VERSION ""

NS_ :

BS_:

BU_: LECU25 LECU23 LECU22 LECU21 LECU19 LECU20 LECU18 LECU17 LECU16 LECU15 LECU14 LECU12 LECU11 LECU10 LECU9 LECU8 LECU7 LECU6 LECU5 LECU4 LECU2 LECU31 LECU30 LECU29 LECU28 LECU27 LECU26 LECU24 LECU13 LECU3 LECU1 BMU Tester LECU32 Host IVT_Mod

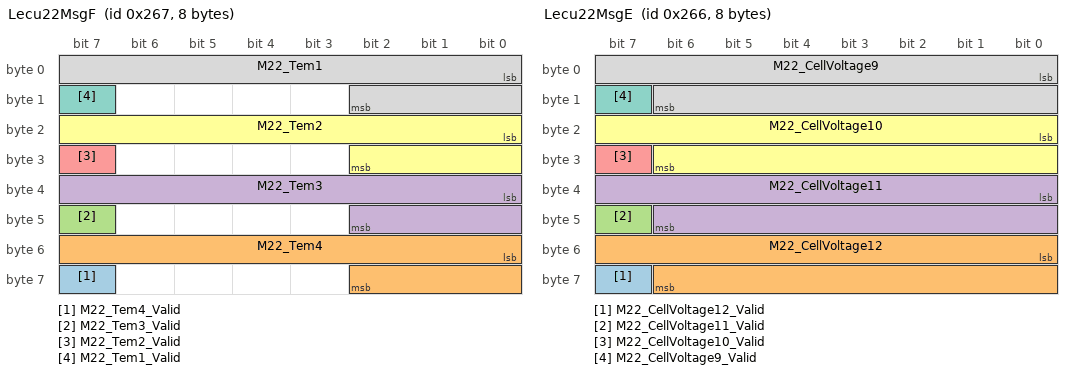
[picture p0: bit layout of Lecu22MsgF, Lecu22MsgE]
BO_ 615 Lecu22MsgF: 8 Vector__XXX
 SG_ M22_Tem4_Valid : 63|1@1+ (1,0) [0|0] "" Vector__XXX
 SG_ M22_Tem4 : 48|11@1+ (0.1,-40) [0|0] "" Vector__XXX
 SG_ M22_Tem3_Valid : 47|1@1+ (1,0) [0|0] "" Vector__XXX
 SG_ M22_Tem3 : 32|11@1+ (0.1,-40) [0|0] "" Vector__XXX
 SG_ M22_Tem2_Valid : 31|1@1+ (1,0) [0|0] "" Vector__XXX
 SG_ M22_Tem2 : 16|11@1+ (0.1,-40) [0|0] "" Vector__XXX
 SG_ M22_Tem1_Valid : 15|1@1+ (1,0) [0|0] "" Vector__XXX
 SG_ M22_Tem1 : 0|11@1+ (0.1,-40) [0|0] "" Vector__XXX

BO_ 614 Lecu22MsgE: 8 Vector__XXX
 SG_ M22_CellVoltage12_Valid : 63|1@1+ (1,0) [0|0] "" Vector__XXX
 SG_ M22_CellVoltage12 : 48|15@1- (0.001,0) [0|0] "" Vector__XXX
 SG_ M22_CellVoltage11_Valid : 47|1@1+ (1,0) [0|0] "" Vector__XXX
 SG_ M22_CellVoltage11 : 32|15@1- (0.001,0) [0|0] "" Vector__XXX
 SG_ M22_CellVoltage10_Valid : 31|1@1+ (1,0) [0|0] "" Vector__XXX
 SG_ M22_CellVoltage10 : 16|15@1- (0.001,0) [0|0] "" Vector__XXX
 SG_ M22_CellVoltage9_Valid : 15|1@1+ (1,0) [0|0] "" Vector__XXX
 SG_ M22_CellVoltage9 : 0|15@1- (0.001,0) [0|0] "" Vector__XXX

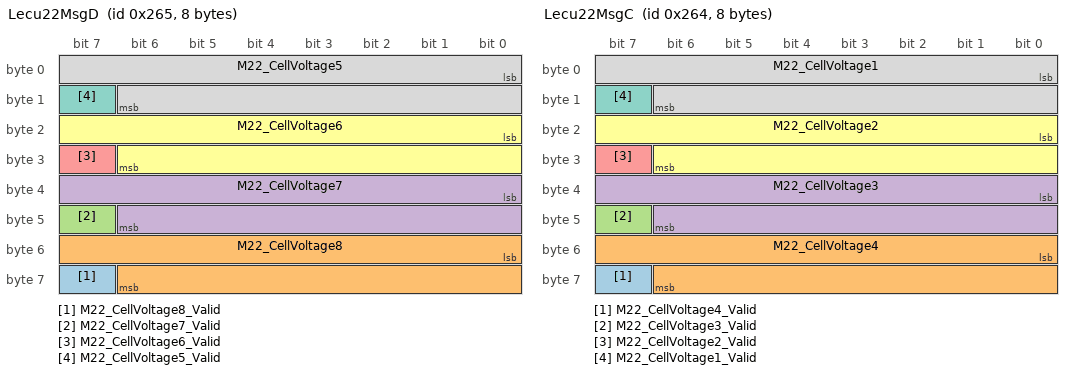
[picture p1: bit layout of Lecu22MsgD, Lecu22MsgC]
BO_ 613 Lecu22MsgD: 8 Vector__XXX
 SG_ M22_CellVoltage8_Valid : 63|1@1+ (1,0) [0|0] "" Vector__XXX
 SG_ M22_CellVoltage8 : 48|15@1- (0.001,0) [0|0] "" Vector__XXX
 SG_ M22_CellVoltage7_Valid : 47|1@1+ (1,0) [0|0] "" Vector__XXX
 SG_ M22_CellVoltage7 : 32|15@1- (0.001,0) [0|0] "" Vector__XXX
 SG_ M22_CellVoltage6_Valid : 31|1@1+ (1,0) [0|0] "" Vector__XXX
 SG_ M22_CellVoltage6 : 16|15@1- (0.001,0) [0|0] "" Vector__XXX
 SG_ M22_CellVoltage5_Valid : 15|1@1+ (1,0) [0|0] "" Vector__XXX
 SG_ M22_CellVoltage5 : 0|15@1- (0.001,0) [0|0] "" Vector__XXX

BO_ 612 Lecu22MsgC: 8 Vector__XXX
 SG_ M22_CellVoltage4_Valid : 63|1@1+ (1,0) [0|0] "" Vector__XXX
 SG_ M22_CellVoltage4 : 48|15@1- (0.001,0) [0|0] "" Vector__XXX
 SG_ M22_CellVoltage3_Valid : 47|1@1+ (1,0) [0|0] "" Vector__XXX
 SG_ M22_CellVoltage3 : 32|15@1- (0.001,0) [0|0] "" Vector__XXX
 SG_ M22_CellVoltage2_Valid : 31|1@1+ (1,0) [0|0] "" Vector__XXX
 SG_ M22_CellVoltage2 : 16|15@1- (0.001,0) [0|0] "" Vector__XXX
 SG_ M22_CellVoltage1_Valid : 15|1@1+ (1,0) [0|0] "" Vector__XXX
 SG_ M22_CellVoltage1 : 0|15@1- (0.001,0) [0|0] "" Vector__XXX

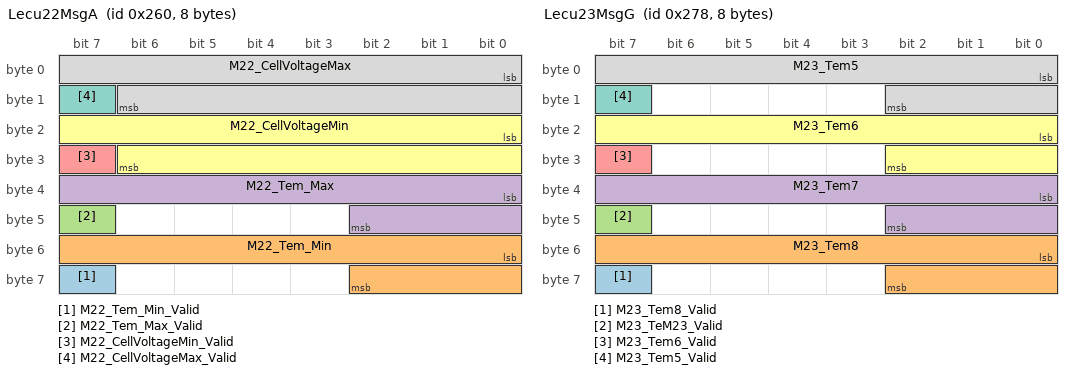
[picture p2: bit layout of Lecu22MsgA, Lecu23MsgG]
BO_ 608 Lecu22MsgA: 8 LECU22
 SG_ M22_Tem_Min_Valid : 63|1@1+ (1,0) [0|0] ""  BMU
 SG_ M22_Tem_Min : 48|11@1+ (0.1,-40) [0|0] "℃"  BMU
 SG_ M22_Tem_Max_Valid : 47|1@1+ (1,0) [0|0] ""  BMU
 SG_ M22_Tem_Max : 32|11@1+ (0.1,-40) [0|0] "℃"  BMU
 SG_ M22_CellVoltageMin_Valid : 31|1@1+ (1,0) [0|0] ""  BMU
 SG_ M22_CellVoltageMin : 16|15@1- (0.001,0) [0|0] "V"  BMU
 SG_ M22_CellVoltageMax_Valid : 15|1@1+ (1,0) [0|0] ""  BMU
 SG_ M22_CellVoltageMax : 0|15@1- (0.001,0) [0|0] "V"  BMU

BO_ 633 Lecu23MsgH: 8 Vector__XXX
 SG_ Lecu_Version3 : 63|8@0+ (1,0) [0|0] "" Vector__XXX
 SG_ Lecu_Version2 : 55|8@0+ (1,0) [0|0] "" Vector__XXX
 SG_ Lecu_Version1 : 47|8@0+ (1,0) [0|0] "" Vector__XXX
 SG_ Lecu_Version0 : 39|8@0+ (1,0) [0|0] "" Vector__XXX
 SG_ M23_CellBalance24 : 23|1@1+ (1,0) [0|0] "" Vector__XXX
 SG_ M23_CellBalance23 : 22|1@1+ (1,0) [0|0] "" Vector__XXX
 SG_ M23_CellBalance22 : 21|1@1+ (1,0) [0|0] "" Vector__XXX
 SG_ M23_CellBalance21 : 20|1@1+ (1,0) [0|0] "" Vector__XXX
 SG_ M23_CellBalance20 : 19|1@1+ (1,0) [0|0] "" Vector__XXX
 SG_ M23_CellBalance19 : 18|1@1+ (1,0) [0|0] "" Vector__XXX
 SG_ M23_CellBalance18 : 17|1@1+ (1,0) [0|0] "" Vector__XXX
 SG_ M23_CellBalance17 : 16|1@1+ (1,0) [0|0] "" Vector__XXX
 SG_ M23_CellBalance16 : 15|1@1+ (1,0) [0|0] "" Vector__XXX
 SG_ M23_CellBalance15 : 14|1@1+ (1,0) [0|0] "" Vector__XXX
 SG_ M23_CellBalance14 : 13|1@1+ (1,0) [0|0] "" Vector__XXX
 SG_ M23_CellBalance13 : 12|1@1+ (1,0) [0|0] "" Vector__XXX
 SG_ M23_CellBalance9 : 8|1@1+ (1,0) [0|0] "" Vector__XXX
 SG_ M23_CellBalance8 : 7|1@1+ (1,0) [0|0] "" Vector__XXX
 SG_ M23_CellBalance7 : 6|1@1+ (1,0) [0|0] "" Vector__XXX
 SG_ M23_CellBalance6 : 5|1@1+ (1,0) [0|0] "" Vector__XXX
 SG_ M23_CellBalance5 : 4|1@1+ (1,0) [0|0] "" Vector__XXX
 SG_ M23_CellBalance4 : 3|1@1+ (1,0) [0|0] "" Vector__XXX
 SG_ M23_CellBalance3 : 2|1@1+ (1,0) [0|0] "" Vector__XXX
 SG_ M23_CellBalance2 : 1|1@1+ (1,0) [0|0] "" Vector__XXX
 SG_ M23_CellBalance12 : 11|1@1+ (1,0) [0|0] "" Vector__XXX
 SG_ M23_CellBalance11 : 10|1@1+ (1,0) [0|0] "" Vector__XXX
 SG_ M23_CellBalance10 : 9|1@1+ (1,0) [0|0] "" Vector__XXX
 SG_ M23_CellBalance1 : 0|1@1+ (1,0) [0|0] "" Vector__XXX

BO_ 632 Lecu23MsgG: 8 Vector__XXX
 SG_ M23_Tem8_Valid : 63|1@1+ (1,0) [0|0] "" Vector__XXX
 SG_ M23_Tem8 : 48|11@1+ (0.1,-40) [0|0] "" Vector__XXX
 SG_ M23_TeM23_Valid : 47|1@1+ (1,0) [0|0] "" Vector__XXX
 SG_ M23_Tem7 : 32|11@1+ (0.1,-40) [0|0] "" Vector__XXX
 SG_ M23_Tem6_Valid : 31|1@1+ (1,0) [0|0] "" Vector__XXX
 SG_ M23_Tem6 : 16|11@1+ (0.1,-40) [0|0] "" Vector__XXX
 SG_ M23_Tem5_Valid : 15|1@1+ (1,0) [0|0] "" Vector__XXX
 SG_ M23_Tem5 : 0|11@1+ (0.1,-40) [0|0] "" Vector__XXX

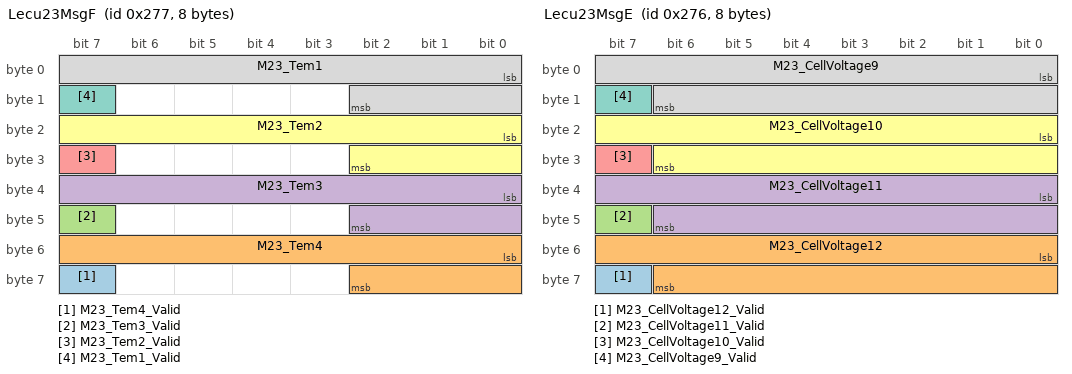
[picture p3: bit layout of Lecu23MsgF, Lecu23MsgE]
BO_ 631 Lecu23MsgF: 8 Vector__XXX
 SG_ M23_Tem4_Valid : 63|1@1+ (1,0) [0|0] "" Vector__XXX
 SG_ M23_Tem4 : 48|11@1+ (0.1,-40) [0|0] "" Vector__XXX
 SG_ M23_Tem3_Valid : 47|1@1+ (1,0) [0|0] "" Vector__XXX
 SG_ M23_Tem3 : 32|11@1+ (0.1,-40) [0|0] "" Vector__XXX
 SG_ M23_Tem2_Valid : 31|1@1+ (1,0) [0|0] "" Vector__XXX
 SG_ M23_Tem2 : 16|11@1+ (0.1,-40) [0|0] "" Vector__XXX
 SG_ M23_Tem1_Valid : 15|1@1+ (1,0) [0|0] "" Vector__XXX
 SG_ M23_Tem1 : 0|11@1+ (0.1,-40) [0|0] "" Vector__XXX

BO_ 630 Lecu23MsgE: 8 Vector__XXX
 SG_ M23_CellVoltage12_Valid : 63|1@1+ (1,0) [0|0] "" Vector__XXX
 SG_ M23_CellVoltage12 : 48|15@1- (0.001,0) [0|0] "" Vector__XXX
 SG_ M23_CellVoltage11_Valid : 47|1@1+ (1,0) [0|0] "" Vector__XXX
 SG_ M23_CellVoltage11 : 32|15@1- (0.001,0) [0|0] "" Vector__XXX
 SG_ M23_CellVoltage10_Valid : 31|1@1+ (1,0) [0|0] "" Vector__XXX
 SG_ M23_CellVoltage10 : 16|15@1- (0.001,0) [0|0] "" Vector__XXX
 SG_ M23_CellVoltage9_Valid : 15|1@1+ (1,0) [0|0] "" Vector__XXX
 SG_ M23_CellVoltage9 : 0|15@1- (0.001,0) [0|0] "" Vector__XXX

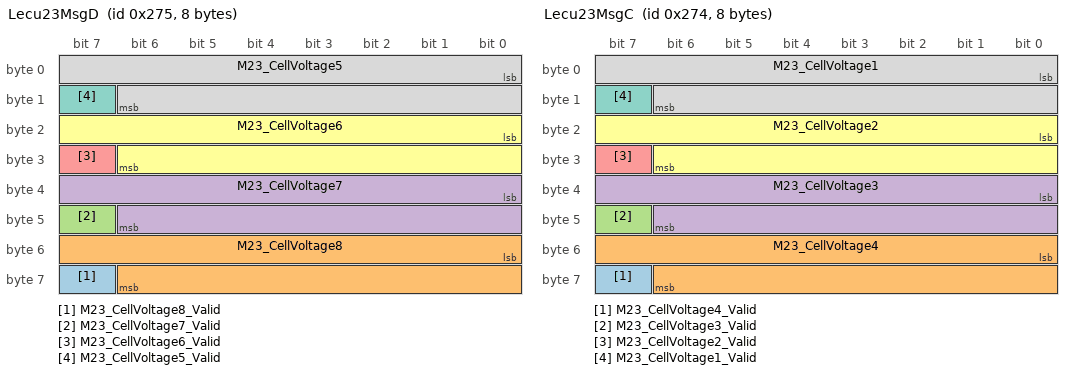
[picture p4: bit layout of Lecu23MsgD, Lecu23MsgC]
BO_ 629 Lecu23MsgD: 8 Vector__XXX
 SG_ M23_CellVoltage8_Valid : 63|1@1+ (1,0) [0|0] "" Vector__XXX
 SG_ M23_CellVoltage8 : 48|15@1- (0.001,0) [0|0] "" Vector__XXX
 SG_ M23_CellVoltage7_Valid : 47|1@1+ (1,0) [0|0] "" Vector__XXX
 SG_ M23_CellVoltage7 : 32|15@1- (0.001,0) [0|0] "" Vector__XXX
 SG_ M23_CellVoltage6_Valid : 31|1@1+ (1,0) [0|0] "" Vector__XXX
 SG_ M23_CellVoltage6 : 16|15@1- (0.001,0) [0|0] "" Vector__XXX
 SG_ M23_CellVoltage5_Valid : 15|1@1+ (1,0) [0|0] "" Vector__XXX
 SG_ M23_CellVoltage5 : 0|15@1- (0.001,0) [0|0] "" Vector__XXX

BO_ 628 Lecu23MsgC: 8 Vector__XXX
 SG_ M23_CellVoltage4_Valid : 63|1@1+ (1,0) [0|0] "" Vector__XXX
 SG_ M23_CellVoltage4 : 48|15@1- (0.001,0) [0|0] "" Vector__XXX
 SG_ M23_CellVoltage3_Valid : 47|1@1+ (1,0) [0|0] "" Vector__XXX
 SG_ M23_CellVoltage3 : 32|15@1- (0.001,0) [0|0] "" Vector__XXX
 SG_ M23_CellVoltage2_Valid : 31|1@1+ (1,0) [0|0] "" Vector__XXX
 SG_ M23_CellVoltage2 : 16|15@1- (0.001,0) [0|0] "" Vector__XXX
 SG_ M23_CellVoltage1_Valid : 15|1@1+ (1,0) [0|0] "" Vector__XXX
 SG_ M23_CellVoltage1 : 0|15@1- (0.001,0) [0|0] "" Vector__XXX

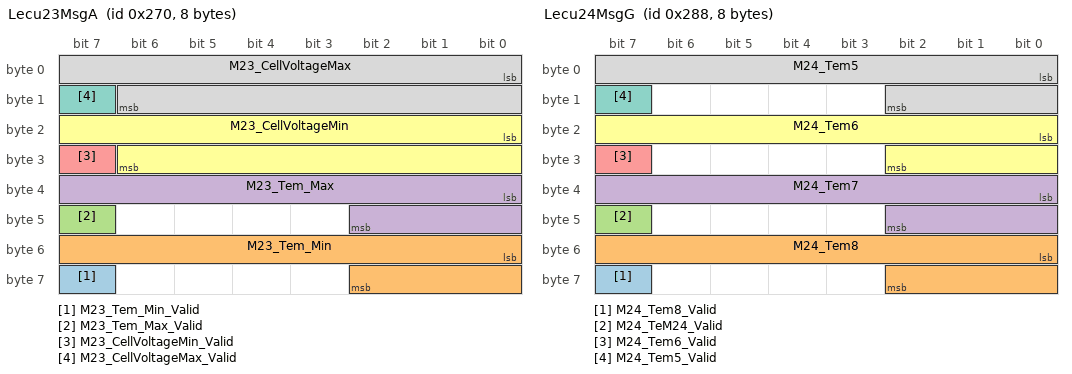
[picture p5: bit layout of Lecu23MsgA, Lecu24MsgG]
BO_ 624 Lecu23MsgA: 8 LECU23
 SG_ M23_Tem_Min_Valid : 63|1@1+ (1,0) [0|0] ""  BMU
 SG_ M23_Tem_Min : 48|11@1+ (0.1,-40) [0|0] "℃"  BMU
 SG_ M23_Tem_Max_Valid : 47|1@1+ (1,0) [0|0] ""  BMU
 SG_ M23_Tem_Max : 32|11@1+ (0.1,-40) [0|0] "℃"  BMU
 SG_ M23_CellVoltageMin_Valid : 31|1@1+ (1,0) [0|0] ""  BMU
 SG_ M23_CellVoltageMin : 16|15@1- (0.001,0) [0|0] "V"  BMU
 SG_ M23_CellVoltageMax_Valid : 15|1@1+ (1,0) [0|0] ""  BMU
 SG_ M23_CellVoltageMax : 0|15@1- (0.001,0) [0|0] "V"  BMU

BO_ 649 Lecu24MsgH: 8 Vector__XXX
 SG_ Lecu_Version3 : 63|8@0+ (1,0) [0|0] "" Vector__XXX
 SG_ Lecu_Version2 : 55|8@0+ (1,0) [0|0] "" Vector__XXX
 SG_ Lecu_Version1 : 47|8@0+ (1,0) [0|0] "" Vector__XXX
 SG_ Lecu_Version0 : 39|8@0+ (1,0) [0|0] "" Vector__XXX
 SG_ M24_CellBalance24 : 23|1@1+ (1,0) [0|0] "" Vector__XXX
 SG_ M24_CellBalance23 : 22|1@1+ (1,0) [0|0] "" Vector__XXX
 SG_ M24_CellBalance22 : 21|1@1+ (1,0) [0|0] "" Vector__XXX
 SG_ M24_CellBalance21 : 20|1@1+ (1,0) [0|0] "" Vector__XXX
 SG_ M24_CellBalance20 : 19|1@1+ (1,0) [0|0] "" Vector__XXX
 SG_ M24_CellBalance19 : 18|1@1+ (1,0) [0|0] "" Vector__XXX
 SG_ M24_CellBalance18 : 17|1@1+ (1,0) [0|0] "" Vector__XXX
 SG_ M24_CellBalance17 : 16|1@1+ (1,0) [0|0] "" Vector__XXX
 SG_ M24_CellBalance16 : 15|1@1+ (1,0) [0|0] "" Vector__XXX
 SG_ M24_CellBalance15 : 14|1@1+ (1,0) [0|0] "" Vector__XXX
 SG_ M24_CellBalance14 : 13|1@1+ (1,0) [0|0] "" Vector__XXX
 SG_ M24_CellBalance13 : 12|1@1+ (1,0) [0|0] "" Vector__XXX
 SG_ M24_CellBalance9 : 8|1@1+ (1,0) [0|0] "" Vector__XXX
 SG_ M24_CellBalance8 : 7|1@1+ (1,0) [0|0] "" Vector__XXX
 SG_ M24_CellBalance7 : 6|1@1+ (1,0) [0|0] "" Vector__XXX
 SG_ M24_CellBalance6 : 5|1@1+ (1,0) [0|0] "" Vector__XXX
 SG_ M24_CellBalance5 : 4|1@1+ (1,0) [0|0] "" Vector__XXX
 SG_ M24_CellBalance4 : 3|1@1+ (1,0) [0|0] "" Vector__XXX
 SG_ M24_CellBalance3 : 2|1@1+ (1,0) [0|0] "" Vector__XXX
 SG_ M24_CellBalance2 : 1|1@1+ (1,0) [0|0] "" Vector__XXX
 SG_ M24_CellBalance12 : 11|1@1+ (1,0) [0|0] "" Vector__XXX
 SG_ M24_CellBalance11 : 10|1@1+ (1,0) [0|0] "" Vector__XXX
 SG_ M24_CellBalance10 : 9|1@1+ (1,0) [0|0] "" Vector__XXX
 SG_ M24_CellBalance1 : 0|1@1+ (1,0) [0|0] "" Vector__XXX

BO_ 648 Lecu24MsgG: 8 Vector__XXX
 SG_ M24_Tem8_Valid : 63|1@1+ (1,0) [0|0] "" Vector__XXX
 SG_ M24_Tem8 : 48|11@1+ (0.1,-40) [0|0] "" Vector__XXX
 SG_ M24_TeM24_Valid : 47|1@1+ (1,0) [0|0] "" Vector__XXX
 SG_ M24_Tem7 : 32|11@1+ (0.1,-40) [0|0] "" Vector__XXX
 SG_ M24_Tem6_Valid : 31|1@1+ (1,0) [0|0] "" Vector__XXX
 SG_ M24_Tem6 : 16|11@1+ (0.1,-40) [0|0] "" Vector__XXX
 SG_ M24_Tem5_Valid : 15|1@1+ (1,0) [0|0] "" Vector__XXX
 SG_ M24_Tem5 : 0|11@1+ (0.1,-40) [0|0] "" Vector__XXX

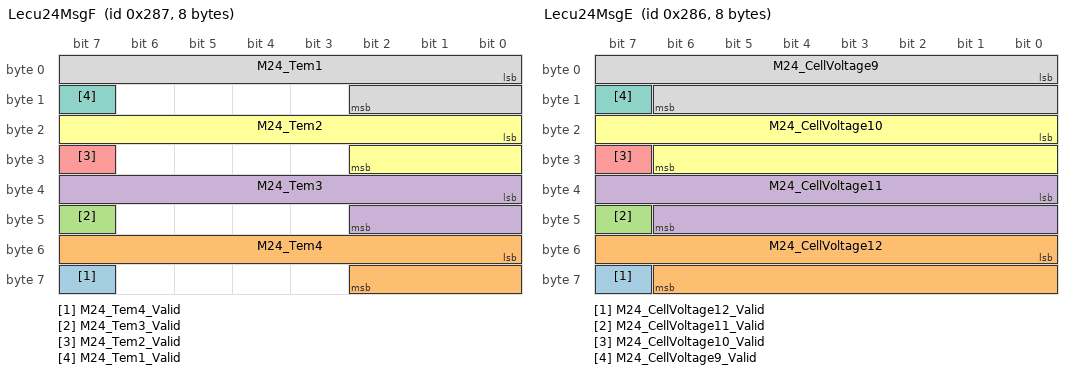
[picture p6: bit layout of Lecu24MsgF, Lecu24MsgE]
BO_ 647 Lecu24MsgF: 8 Vector__XXX
 SG_ M24_Tem4_Valid : 63|1@1+ (1,0) [0|0] "" Vector__XXX
 SG_ M24_Tem4 : 48|11@1+ (0.1,-40) [0|0] "" Vector__XXX
 SG_ M24_Tem3_Valid : 47|1@1+ (1,0) [0|0] "" Vector__XXX
 SG_ M24_Tem3 : 32|11@1+ (0.1,-40) [0|0] "" Vector__XXX
 SG_ M24_Tem2_Valid : 31|1@1+ (1,0) [0|0] "" Vector__XXX
 SG_ M24_Tem2 : 16|11@1+ (0.1,-40) [0|0] "" Vector__XXX
 SG_ M24_Tem1_Valid : 15|1@1+ (1,0) [0|0] "" Vector__XXX
 SG_ M24_Tem1 : 0|11@1+ (0.1,-40) [0|0] "" Vector__XXX

BO_ 646 Lecu24MsgE: 8 Vector__XXX
 SG_ M24_CellVoltage12_Valid : 63|1@1+ (1,0) [0|0] "" Vector__XXX
 SG_ M24_CellVoltage12 : 48|15@1- (0.001,0) [0|0] "" Vector__XXX
 SG_ M24_CellVoltage11_Valid : 47|1@1+ (1,0) [0|0] "" Vector__XXX
 SG_ M24_CellVoltage11 : 32|15@1- (0.001,0) [0|0] "" Vector__XXX
 SG_ M24_CellVoltage10_Valid : 31|1@1+ (1,0) [0|0] "" Vector__XXX
 SG_ M24_CellVoltage10 : 16|15@1- (0.001,0) [0|0] "" Vector__XXX
 SG_ M24_CellVoltage9_Valid : 15|1@1+ (1,0) [0|0] "" Vector__XXX
 SG_ M24_CellVoltage9 : 0|15@1- (0.001,0) [0|0] "" Vector__XXX

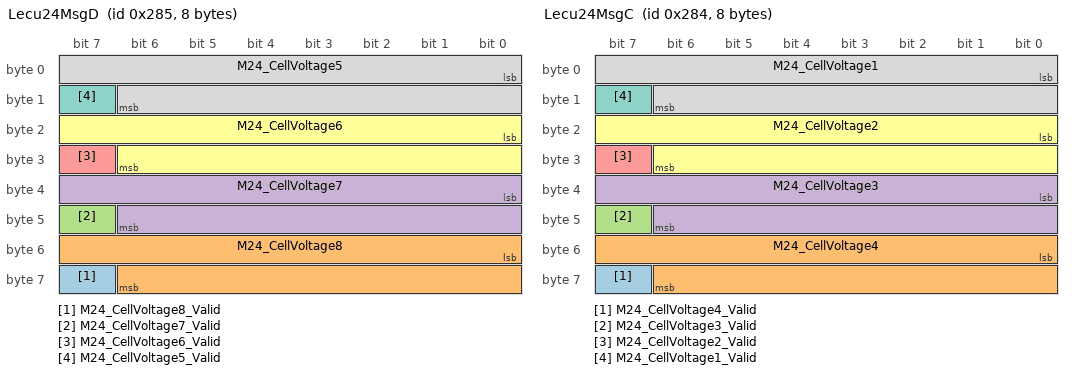
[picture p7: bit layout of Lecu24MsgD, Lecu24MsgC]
BO_ 645 Lecu24MsgD: 8 Vector__XXX
 SG_ M24_CellVoltage8_Valid : 63|1@1+ (1,0) [0|0] "" Vector__XXX
 SG_ M24_CellVoltage8 : 48|15@1- (0.001,0) [0|0] "" Vector__XXX
 SG_ M24_CellVoltage7_Valid : 47|1@1+ (1,0) [0|0] "" Vector__XXX
 SG_ M24_CellVoltage7 : 32|15@1- (0.001,0) [0|0] "" Vector__XXX
 SG_ M24_CellVoltage6_Valid : 31|1@1+ (1,0) [0|0] "" Vector__XXX
 SG_ M24_CellVoltage6 : 16|15@1- (0.001,0) [0|0] "" Vector__XXX
 SG_ M24_CellVoltage5_Valid : 15|1@1+ (1,0) [0|0] "" Vector__XXX
 SG_ M24_CellVoltage5 : 0|15@1- (0.001,0) [0|0] "" Vector__XXX

BO_ 644 Lecu24MsgC: 8 Vector__XXX
 SG_ M24_CellVoltage4_Valid : 63|1@1+ (1,0) [0|0] "" Vector__XXX
 SG_ M24_CellVoltage4 : 48|15@1- (0.001,0) [0|0] "" Vector__XXX
 SG_ M24_CellVoltage3_Valid : 47|1@1+ (1,0) [0|0] "" Vector__XXX
 SG_ M24_CellVoltage3 : 32|15@1- (0.001,0) [0|0] "" Vector__XXX
 SG_ M24_CellVoltage2_Valid : 31|1@1+ (1,0) [0|0] "" Vector__XXX
 SG_ M24_CellVoltage2 : 16|15@1- (0.001,0) [0|0] "" Vector__XXX
 SG_ M24_CellVoltage1_Valid : 15|1@1+ (1,0) [0|0] "" Vector__XXX
 SG_ M24_CellVoltage1 : 0|15@1- (0.001,0) [0|0] "" Vector__XXX

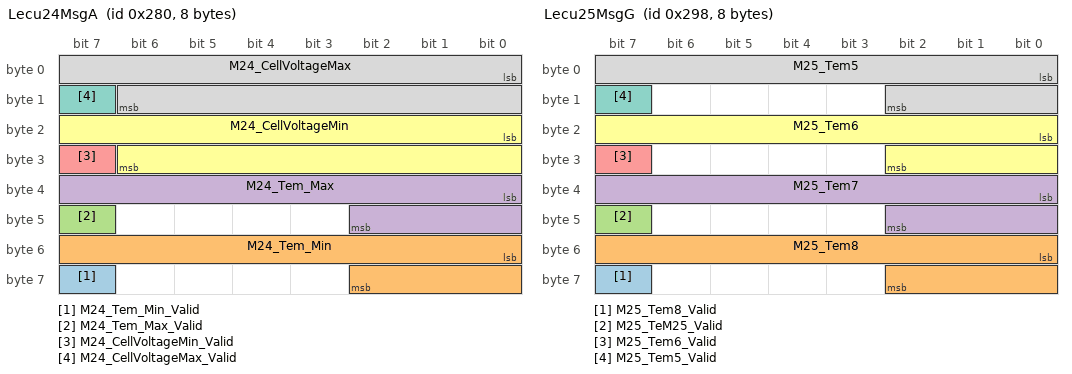
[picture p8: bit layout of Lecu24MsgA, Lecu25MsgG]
BO_ 640 Lecu24MsgA: 8 LECU24
 SG_ M24_Tem_Min_Valid : 63|1@1+ (1,0) [0|0] ""  BMU
 SG_ M24_Tem_Min : 48|11@1+ (0.1,-40) [0|0] "℃"  BMU
 SG_ M24_Tem_Max_Valid : 47|1@1+ (1,0) [0|0] ""  BMU
 SG_ M24_Tem_Max : 32|11@1+ (0.1,-40) [0|0] "℃"  BMU
 SG_ M24_CellVoltageMin_Valid : 31|1@1+ (1,0) [0|0] ""  BMU
 SG_ M24_CellVoltageMin : 16|15@1- (0.001,0) [0|0] "V"  BMU
 SG_ M24_CellVoltageMax_Valid : 15|1@1+ (1,0) [0|0] ""  BMU
 SG_ M24_CellVoltageMax : 0|15@1- (0.001,0) [0|0] "V"  BMU

BO_ 665 Lecu25MsgH: 8 Vector__XXX
 SG_ Lecu_Version3 : 63|8@0+ (1,0) [0|0] "" Vector__XXX
 SG_ Lecu_Version2 : 55|8@0+ (1,0) [0|0] "" Vector__XXX
 SG_ Lecu_Version1 : 47|8@0+ (1,0) [0|0] "" Vector__XXX
 SG_ Lecu_Version0 : 39|8@0+ (1,0) [0|0] "" Vector__XXX
 SG_ M25_CellBalance24 : 23|1@1+ (1,0) [0|0] "" Vector__XXX
 SG_ M25_CellBalance23 : 22|1@1+ (1,0) [0|0] "" Vector__XXX
 SG_ M25_CellBalance22 : 21|1@1+ (1,0) [0|0] "" Vector__XXX
 SG_ M25_CellBalance21 : 20|1@1+ (1,0) [0|0] "" Vector__XXX
 SG_ M25_CellBalance20 : 19|1@1+ (1,0) [0|0] "" Vector__XXX
 SG_ M25_CellBalance19 : 18|1@1+ (1,0) [0|0] "" Vector__XXX
 SG_ M25_CellBalance18 : 17|1@1+ (1,0) [0|0] "" Vector__XXX
 SG_ M25_CellBalance17 : 16|1@1+ (1,0) [0|0] "" Vector__XXX
 SG_ M25_CellBalance16 : 15|1@1+ (1,0) [0|0] "" Vector__XXX
 SG_ M25_CellBalance15 : 14|1@1+ (1,0) [0|0] "" Vector__XXX
 SG_ M25_CellBalance14 : 13|1@1+ (1,0) [0|0] "" Vector__XXX
 SG_ M25_CellBalance13 : 12|1@1+ (1,0) [0|0] "" Vector__XXX
 SG_ M25_CellBalance9 : 8|1@1+ (1,0) [0|0] "" Vector__XXX
 SG_ M25_CellBalance8 : 7|1@1+ (1,0) [0|0] "" Vector__XXX
 SG_ M25_CellBalance7 : 6|1@1+ (1,0) [0|0] "" Vector__XXX
 SG_ M25_CellBalance6 : 5|1@1+ (1,0) [0|0] "" Vector__XXX
 SG_ M25_CellBalance5 : 4|1@1+ (1,0) [0|0] "" Vector__XXX
 SG_ M25_CellBalance4 : 3|1@1+ (1,0) [0|0] "" Vector__XXX
 SG_ M25_CellBalance3 : 2|1@1+ (1,0) [0|0] "" Vector__XXX
 SG_ M25_CellBalance2 : 1|1@1+ (1,0) [0|0] "" Vector__XXX
 SG_ M25_CellBalance12 : 11|1@1+ (1,0) [0|0] "" Vector__XXX
 SG_ M25_CellBalance11 : 10|1@1+ (1,0) [0|0] "" Vector__XXX
 SG_ M25_CellBalance10 : 9|1@1+ (1,0) [0|0] "" Vector__XXX
 SG_ M25_CellBalance1 : 0|1@1+ (1,0) [0|0] "" Vector__XXX

BO_ 664 Lecu25MsgG: 8 Vector__XXX
 SG_ M25_Tem8_Valid : 63|1@1+ (1,0) [0|0] "" Vector__XXX
 SG_ M25_Tem8 : 48|11@1+ (0.1,-40) [0|0] "" Vector__XXX
 SG_ M25_TeM25_Valid : 47|1@1+ (1,0) [0|0] "" Vector__XXX
 SG_ M25_Tem7 : 32|11@1+ (0.1,-40) [0|0] "" Vector__XXX
 SG_ M25_Tem6_Valid : 31|1@1+ (1,0) [0|0] "" Vector__XXX
 SG_ M25_Tem6 : 16|11@1+ (0.1,-40) [0|0] "" Vector__XXX
 SG_ M25_Tem5_Valid : 15|1@1+ (1,0) [0|0] "" Vector__XXX
 SG_ M25_Tem5 : 0|11@1+ (0.1,-40) [0|0] "" Vector__XXX

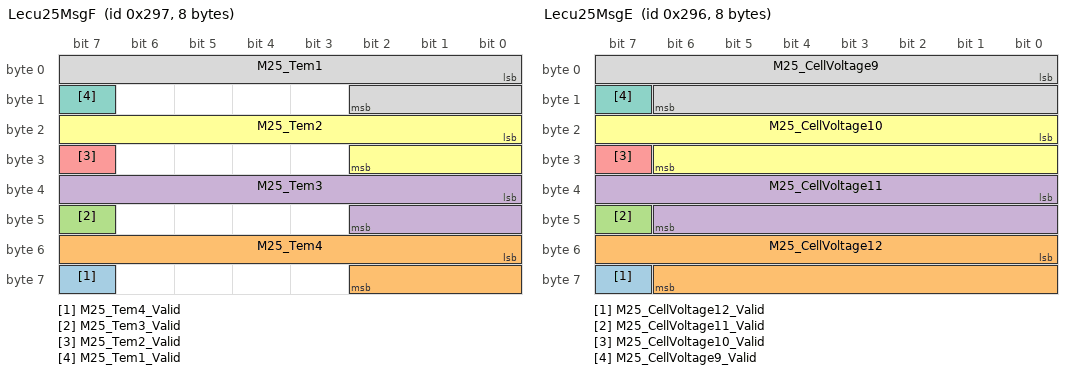
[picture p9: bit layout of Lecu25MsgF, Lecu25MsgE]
BO_ 663 Lecu25MsgF: 8 Vector__XXX
 SG_ M25_Tem4_Valid : 63|1@1+ (1,0) [0|0] "" Vector__XXX
 SG_ M25_Tem4 : 48|11@1+ (0.1,-40) [0|0] "" Vector__XXX
 SG_ M25_Tem3_Valid : 47|1@1+ (1,0) [0|0] "" Vector__XXX
 SG_ M25_Tem3 : 32|11@1+ (0.1,-40) [0|0] "" Vector__XXX
 SG_ M25_Tem2_Valid : 31|1@1+ (1,0) [0|0] "" Vector__XXX
 SG_ M25_Tem2 : 16|11@1+ (0.1,-40) [0|0] "" Vector__XXX
 SG_ M25_Tem1_Valid : 15|1@1+ (1,0) [0|0] "" Vector__XXX
 SG_ M25_Tem1 : 0|11@1+ (0.1,-40) [0|0] "" Vector__XXX

BO_ 662 Lecu25MsgE: 8 Vector__XXX
 SG_ M25_CellVoltage12_Valid : 63|1@1+ (1,0) [0|0] "" Vector__XXX
 SG_ M25_CellVoltage12 : 48|15@1- (0.001,0) [0|0] "" Vector__XXX
 SG_ M25_CellVoltage11_Valid : 47|1@1+ (1,0) [0|0] "" Vector__XXX
 SG_ M25_CellVoltage11 : 32|15@1- (0.001,0) [0|0] "" Vector__XXX
 SG_ M25_CellVoltage10_Valid : 31|1@1+ (1,0) [0|0] "" Vector__XXX
 SG_ M25_CellVoltage10 : 16|15@1- (0.001,0) [0|0] "" Vector__XXX
 SG_ M25_CellVoltage9_Valid : 15|1@1+ (1,0) [0|0] "" Vector__XXX
 SG_ M25_CellVoltage9 : 0|15@1- (0.001,0) [0|0] "" Vector__XXX

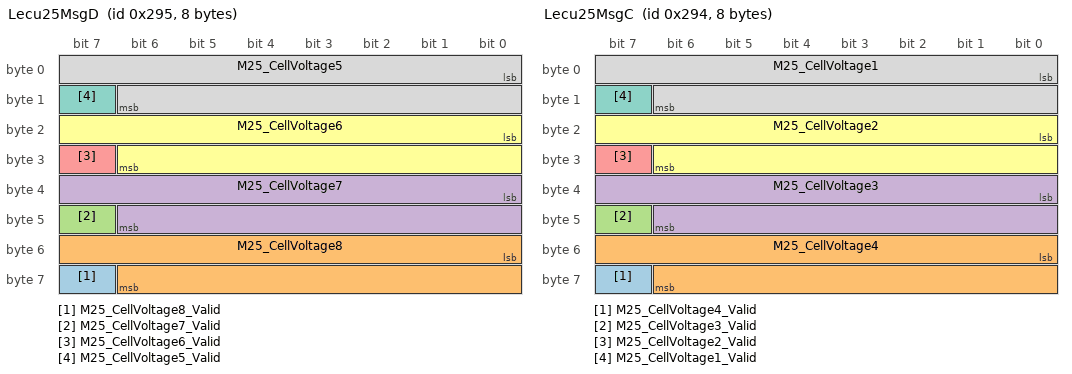
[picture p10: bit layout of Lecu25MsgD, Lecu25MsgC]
BO_ 661 Lecu25MsgD: 8 Vector__XXX
 SG_ M25_CellVoltage8_Valid : 63|1@1+ (1,0) [0|0] "" Vector__XXX
 SG_ M25_CellVoltage8 : 48|15@1- (0.001,0) [0|0] "" Vector__XXX
 SG_ M25_CellVoltage7_Valid : 47|1@1+ (1,0) [0|0] "" Vector__XXX
 SG_ M25_CellVoltage7 : 32|15@1- (0.001,0) [0|0] "" Vector__XXX
 SG_ M25_CellVoltage6_Valid : 31|1@1+ (1,0) [0|0] "" Vector__XXX
 SG_ M25_CellVoltage6 : 16|15@1- (0.001,0) [0|0] "" Vector__XXX
 SG_ M25_CellVoltage5_Valid : 15|1@1+ (1,0) [0|0] "" Vector__XXX
 SG_ M25_CellVoltage5 : 0|15@1- (0.001,0) [0|0] "" Vector__XXX

BO_ 660 Lecu25MsgC: 8 Vector__XXX
 SG_ M25_CellVoltage4_Valid : 63|1@1+ (1,0) [0|0] "" Vector__XXX
 SG_ M25_CellVoltage4 : 48|15@1- (0.001,0) [0|0] "" Vector__XXX
 SG_ M25_CellVoltage3_Valid : 47|1@1+ (1,0) [0|0] "" Vector__XXX
 SG_ M25_CellVoltage3 : 32|15@1- (0.001,0) [0|0] "" Vector__XXX
 SG_ M25_CellVoltage2_Valid : 31|1@1+ (1,0) [0|0] "" Vector__XXX
 SG_ M25_CellVoltage2 : 16|15@1- (0.001,0) [0|0] "" Vector__XXX
 SG_ M25_CellVoltage1_Valid : 15|1@1+ (1,0) [0|0] "" Vector__XXX
 SG_ M25_CellVoltage1 : 0|15@1- (0.001,0) [0|0] "" Vector__XXX

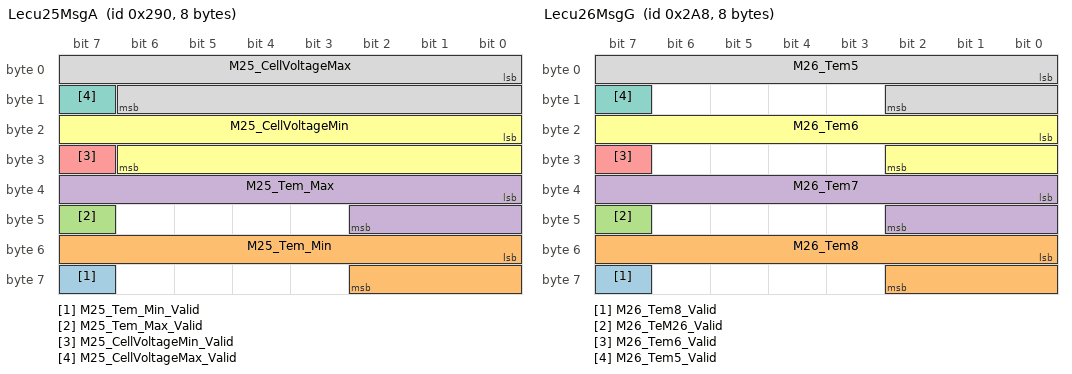
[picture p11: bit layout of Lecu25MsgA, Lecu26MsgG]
BO_ 656 Lecu25MsgA: 8 LECU25
 SG_ M25_Tem_Min_Valid : 63|1@1+ (1,0) [0|0] ""  BMU
 SG_ M25_Tem_Min : 48|11@1+ (0.1,-40) [0|0] "℃"  BMU
 SG_ M25_Tem_Max_Valid : 47|1@1+ (1,0) [0|0] ""  BMU
 SG_ M25_Tem_Max : 32|11@1+ (0.1,-40) [0|0] "℃"  BMU
 SG_ M25_CellVoltageMin_Valid : 31|1@1+ (1,0) [0|0] ""  BMU
 SG_ M25_CellVoltageMin : 16|15@1- (0.001,0) [0|0] "V"  BMU
 SG_ M25_CellVoltageMax_Valid : 15|1@1+ (1,0) [0|0] ""  BMU
 SG_ M25_CellVoltageMax : 0|15@1- (0.001,0) [0|0] "V"  BMU

BO_ 681 Lecu26MsgH: 8 Vector__XXX
 SG_ Lecu_Version3 : 63|8@0+ (1,0) [0|0] "" Vector__XXX
 SG_ Lecu_Version2 : 55|8@0+ (1,0) [0|0] "" Vector__XXX
 SG_ Lecu_Version1 : 47|8@0+ (1,0) [0|0] "" Vector__XXX
 SG_ Lecu_Version0 : 39|8@0+ (1,0) [0|0] "" Vector__XXX
 SG_ M26_CellBalance24 : 23|1@1+ (1,0) [0|0] "" Vector__XXX
 SG_ M26_CellBalance23 : 22|1@1+ (1,0) [0|0] "" Vector__XXX
 SG_ M26_CellBalance22 : 21|1@1+ (1,0) [0|0] "" Vector__XXX
 SG_ M26_CellBalance21 : 20|1@1+ (1,0) [0|0] "" Vector__XXX
 SG_ M26_CellBalance20 : 19|1@1+ (1,0) [0|0] "" Vector__XXX
 SG_ M26_CellBalance19 : 18|1@1+ (1,0) [0|0] "" Vector__XXX
 SG_ M26_CellBalance18 : 17|1@1+ (1,0) [0|0] "" Vector__XXX
 SG_ M26_CellBalance17 : 16|1@1+ (1,0) [0|0] "" Vector__XXX
 SG_ M26_CellBalance16 : 15|1@1+ (1,0) [0|0] "" Vector__XXX
 SG_ M26_CellBalance15 : 14|1@1+ (1,0) [0|0] "" Vector__XXX
 SG_ M26_CellBalance14 : 13|1@1+ (1,0) [0|0] "" Vector__XXX
 SG_ M26_CellBalance13 : 12|1@1+ (1,0) [0|0] "" Vector__XXX
 SG_ M26_CellBalance9 : 8|1@1+ (1,0) [0|0] "" Vector__XXX
 SG_ M26_CellBalance8 : 7|1@1+ (1,0) [0|0] "" Vector__XXX
 SG_ M26_CellBalance7 : 6|1@1+ (1,0) [0|0] "" Vector__XXX
 SG_ M26_CellBalance6 : 5|1@1+ (1,0) [0|0] "" Vector__XXX
 SG_ M26_CellBalance5 : 4|1@1+ (1,0) [0|0] "" Vector__XXX
 SG_ M26_CellBalance4 : 3|1@1+ (1,0) [0|0] "" Vector__XXX
 SG_ M26_CellBalance3 : 2|1@1+ (1,0) [0|0] "" Vector__XXX
 SG_ M26_CellBalance2 : 1|1@1+ (1,0) [0|0] "" Vector__XXX
 SG_ M26_CellBalance12 : 11|1@1+ (1,0) [0|0] "" Vector__XXX
 SG_ M26_CellBalance11 : 10|1@1+ (1,0) [0|0] "" Vector__XXX
 SG_ M26_CellBalance10 : 9|1@1+ (1,0) [0|0] "" Vector__XXX
 SG_ M26_CellBalance1 : 0|1@1+ (1,0) [0|0] "" Vector__XXX

BO_ 680 Lecu26MsgG: 8 Vector__XXX
 SG_ M26_Tem8_Valid : 63|1@1+ (1,0) [0|0] "" Vector__XXX
 SG_ M26_Tem8 : 48|11@1+ (0.1,-40) [0|0] "" Vector__XXX
 SG_ M26_TeM26_Valid : 47|1@1+ (1,0) [0|0] "" Vector__XXX
 SG_ M26_Tem7 : 32|11@1+ (0.1,-40) [0|0] "" Vector__XXX
 SG_ M26_Tem6_Valid : 31|1@1+ (1,0) [0|0] "" Vector__XXX
 SG_ M26_Tem6 : 16|11@1+ (0.1,-40) [0|0] "" Vector__XXX
 SG_ M26_Tem5_Valid : 15|1@1+ (1,0) [0|0] "" Vector__XXX
 SG_ M26_Tem5 : 0|11@1+ (0.1,-40) [0|0] "" Vector__XXX

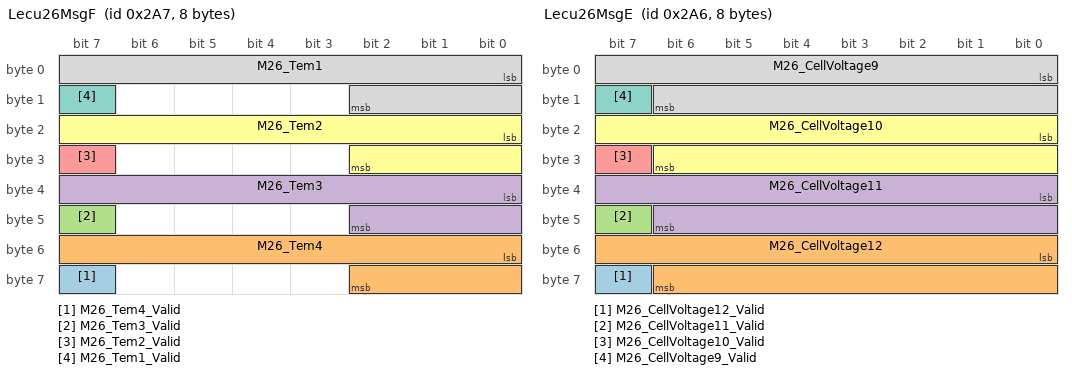
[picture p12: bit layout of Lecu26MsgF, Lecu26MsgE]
BO_ 679 Lecu26MsgF: 8 Vector__XXX
 SG_ M26_Tem4_Valid : 63|1@1+ (1,0) [0|0] "" Vector__XXX
 SG_ M26_Tem4 : 48|11@1+ (0.1,-40) [0|0] "" Vector__XXX
 SG_ M26_Tem3_Valid : 47|1@1+ (1,0) [0|0] "" Vector__XXX
 SG_ M26_Tem3 : 32|11@1+ (0.1,-40) [0|0] "" Vector__XXX
 SG_ M26_Tem2_Valid : 31|1@1+ (1,0) [0|0] "" Vector__XXX
 SG_ M26_Tem2 : 16|11@1+ (0.1,-40) [0|0] "" Vector__XXX
 SG_ M26_Tem1_Valid : 15|1@1+ (1,0) [0|0] "" Vector__XXX
 SG_ M26_Tem1 : 0|11@1+ (0.1,-40) [0|0] "" Vector__XXX

BO_ 678 Lecu26MsgE: 8 Vector__XXX
 SG_ M26_CellVoltage12_Valid : 63|1@1+ (1,0) [0|0] "" Vector__XXX
 SG_ M26_CellVoltage12 : 48|15@1- (0.001,0) [0|0] "" Vector__XXX
 SG_ M26_CellVoltage11_Valid : 47|1@1+ (1,0) [0|0] "" Vector__XXX
 SG_ M26_CellVoltage11 : 32|15@1- (0.001,0) [0|0] "" Vector__XXX
 SG_ M26_CellVoltage10_Valid : 31|1@1+ (1,0) [0|0] "" Vector__XXX
 SG_ M26_CellVoltage10 : 16|15@1- (0.001,0) [0|0] "" Vector__XXX
 SG_ M26_CellVoltage9_Valid : 15|1@1+ (1,0) [0|0] "" Vector__XXX
 SG_ M26_CellVoltage9 : 0|15@1- (0.001,0) [0|0] "" Vector__XXX

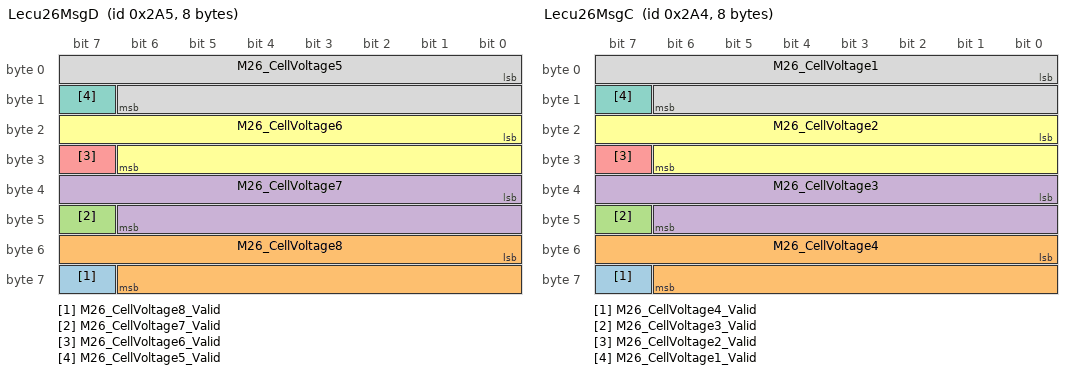
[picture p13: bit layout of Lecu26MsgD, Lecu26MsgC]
BO_ 677 Lecu26MsgD: 8 Vector__XXX
 SG_ M26_CellVoltage8_Valid : 63|1@1+ (1,0) [0|0] "" Vector__XXX
 SG_ M26_CellVoltage8 : 48|15@1- (0.001,0) [0|0] "" Vector__XXX
 SG_ M26_CellVoltage7_Valid : 47|1@1+ (1,0) [0|0] "" Vector__XXX
 SG_ M26_CellVoltage7 : 32|15@1- (0.001,0) [0|0] "" Vector__XXX
 SG_ M26_CellVoltage6_Valid : 31|1@1+ (1,0) [0|0] "" Vector__XXX
 SG_ M26_CellVoltage6 : 16|15@1- (0.001,0) [0|0] "" Vector__XXX
 SG_ M26_CellVoltage5_Valid : 15|1@1+ (1,0) [0|0] "" Vector__XXX
 SG_ M26_CellVoltage5 : 0|15@1- (0.001,0) [0|0] "" Vector__XXX

BO_ 676 Lecu26MsgC: 8 Vector__XXX
 SG_ M26_CellVoltage4_Valid : 63|1@1+ (1,0) [0|0] "" Vector__XXX
 SG_ M26_CellVoltage4 : 48|15@1- (0.001,0) [0|0] "" Vector__XXX
 SG_ M26_CellVoltage3_Valid : 47|1@1+ (1,0) [0|0] "" Vector__XXX
 SG_ M26_CellVoltage3 : 32|15@1- (0.001,0) [0|0] "" Vector__XXX
 SG_ M26_CellVoltage2_Valid : 31|1@1+ (1,0) [0|0] "" Vector__XXX
 SG_ M26_CellVoltage2 : 16|15@1- (0.001,0) [0|0] "" Vector__XXX
 SG_ M26_CellVoltage1_Valid : 15|1@1+ (1,0) [0|0] "" Vector__XXX
 SG_ M26_CellVoltage1 : 0|15@1- (0.001,0) [0|0] "" Vector__XXX

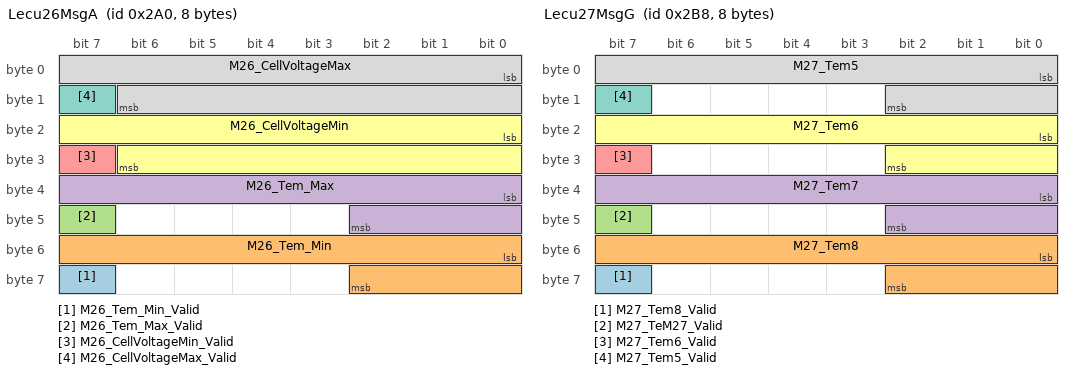
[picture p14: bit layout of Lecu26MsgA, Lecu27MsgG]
BO_ 672 Lecu26MsgA: 8 LECU26
 SG_ M26_Tem_Min_Valid : 63|1@1+ (1,0) [0|0] ""  BMU
 SG_ M26_Tem_Min : 48|11@1+ (0.1,-40) [0|0] "℃"  BMU
 SG_ M26_Tem_Max_Valid : 47|1@1+ (1,0) [0|0] ""  BMU
 SG_ M26_Tem_Max : 32|11@1+ (0.1,-40) [0|0] "℃"  BMU
 SG_ M26_CellVoltageMin_Valid : 31|1@1+ (1,0) [0|0] ""  BMU
 SG_ M26_CellVoltageMin : 16|15@1- (0.001,0) [0|0] "V"  BMU
 SG_ M26_CellVoltageMax_Valid : 15|1@1+ (1,0) [0|0] ""  BMU
 SG_ M26_CellVoltageMax : 0|15@1- (0.001,0) [0|0] "V"  BMU

BO_ 697 Lecu27MsgH: 8 Vector__XXX
 SG_ Lecu_Version3 : 63|8@0+ (1,0) [0|0] "" Vector__XXX
 SG_ Lecu_Version2 : 55|8@0+ (1,0) [0|0] "" Vector__XXX
 SG_ Lecu_Version1 : 47|8@0+ (1,0) [0|0] "" Vector__XXX
 SG_ Lecu_Version0 : 39|8@0+ (1,0) [0|0] "" Vector__XXX
 SG_ M27_CellBalance24 : 23|1@1+ (1,0) [0|0] "" Vector__XXX
 SG_ M27_CellBalance23 : 22|1@1+ (1,0) [0|0] "" Vector__XXX
 SG_ M27_CellBalance22 : 21|1@1+ (1,0) [0|0] "" Vector__XXX
 SG_ M27_CellBalance21 : 20|1@1+ (1,0) [0|0] "" Vector__XXX
 SG_ M27_CellBalance20 : 19|1@1+ (1,0) [0|0] "" Vector__XXX
 SG_ M27_CellBalance19 : 18|1@1+ (1,0) [0|0] "" Vector__XXX
 SG_ M27_CellBalance18 : 17|1@1+ (1,0) [0|0] "" Vector__XXX
 SG_ M27_CellBalance17 : 16|1@1+ (1,0) [0|0] "" Vector__XXX
 SG_ M27_CellBalance16 : 15|1@1+ (1,0) [0|0] "" Vector__XXX
 SG_ M27_CellBalance15 : 14|1@1+ (1,0) [0|0] "" Vector__XXX
 SG_ M27_CellBalance14 : 13|1@1+ (1,0) [0|0] "" Vector__XXX
 SG_ M27_CellBalance13 : 12|1@1+ (1,0) [0|0] "" Vector__XXX
 SG_ M27_CellBalance9 : 8|1@1+ (1,0) [0|0] "" Vector__XXX
 SG_ M27_CellBalance8 : 7|1@1+ (1,0) [0|0] "" Vector__XXX
 SG_ M27_CellBalance7 : 6|1@1+ (1,0) [0|0] "" Vector__XXX
 SG_ M27_CellBalance6 : 5|1@1+ (1,0) [0|0] "" Vector__XXX
 SG_ M27_CellBalance5 : 4|1@1+ (1,0) [0|0] "" Vector__XXX
 SG_ M27_CellBalance4 : 3|1@1+ (1,0) [0|0] "" Vector__XXX
 SG_ M27_CellBalance3 : 2|1@1+ (1,0) [0|0] "" Vector__XXX
 SG_ M27_CellBalance2 : 1|1@1+ (1,0) [0|0] "" Vector__XXX
 SG_ M27_CellBalance12 : 11|1@1+ (1,0) [0|0] "" Vector__XXX
 SG_ M27_CellBalance11 : 10|1@1+ (1,0) [0|0] "" Vector__XXX
 SG_ M27_CellBalance10 : 9|1@1+ (1,0) [0|0] "" Vector__XXX
 SG_ M27_CellBalance1 : 0|1@1+ (1,0) [0|0] "" Vector__XXX

BO_ 696 Lecu27MsgG: 8 Vector__XXX
 SG_ M27_Tem8_Valid : 63|1@1+ (1,0) [0|0] "" Vector__XXX
 SG_ M27_Tem8 : 48|11@1+ (0.1,-40) [0|0] "" Vector__XXX
 SG_ M27_TeM27_Valid : 47|1@1+ (1,0) [0|0] "" Vector__XXX
 SG_ M27_Tem7 : 32|11@1+ (0.1,-40) [0|0] "" Vector__XXX
 SG_ M27_Tem6_Valid : 31|1@1+ (1,0) [0|0] "" Vector__XXX
 SG_ M27_Tem6 : 16|11@1+ (0.1,-40) [0|0] "" Vector__XXX
 SG_ M27_Tem5_Valid : 15|1@1+ (1,0) [0|0] "" Vector__XXX
 SG_ M27_Tem5 : 0|11@1+ (0.1,-40) [0|0] "" Vector__XXX

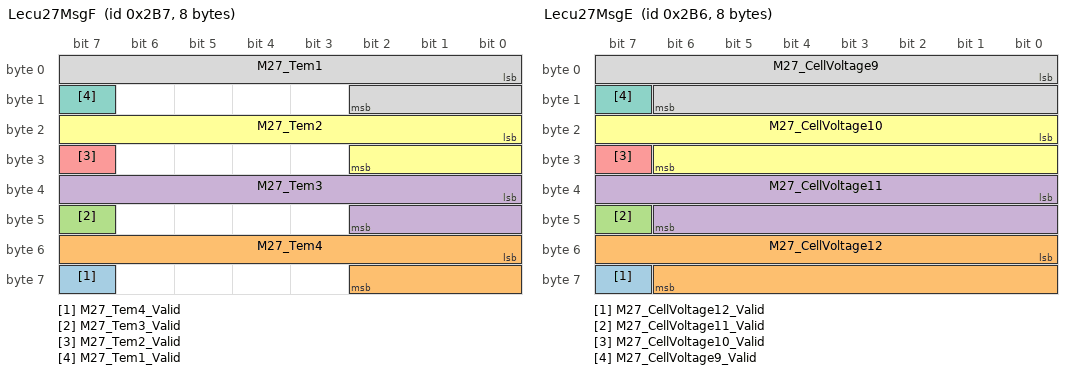
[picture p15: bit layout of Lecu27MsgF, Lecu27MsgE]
BO_ 695 Lecu27MsgF: 8 Vector__XXX
 SG_ M27_Tem4_Valid : 63|1@1+ (1,0) [0|0] "" Vector__XXX
 SG_ M27_Tem4 : 48|11@1+ (0.1,-40) [0|0] "" Vector__XXX
 SG_ M27_Tem3_Valid : 47|1@1+ (1,0) [0|0] "" Vector__XXX
 SG_ M27_Tem3 : 32|11@1+ (0.1,-40) [0|0] "" Vector__XXX
 SG_ M27_Tem2_Valid : 31|1@1+ (1,0) [0|0] "" Vector__XXX
 SG_ M27_Tem2 : 16|11@1+ (0.1,-40) [0|0] "" Vector__XXX
 SG_ M27_Tem1_Valid : 15|1@1+ (1,0) [0|0] "" Vector__XXX
 SG_ M27_Tem1 : 0|11@1+ (0.1,-40) [0|0] "" Vector__XXX

BO_ 694 Lecu27MsgE: 8 Vector__XXX
 SG_ M27_CellVoltage12_Valid : 63|1@1+ (1,0) [0|0] "" Vector__XXX
 SG_ M27_CellVoltage12 : 48|15@1- (0.001,0) [0|0] "" Vector__XXX
 SG_ M27_CellVoltage11_Valid : 47|1@1+ (1,0) [0|0] "" Vector__XXX
 SG_ M27_CellVoltage11 : 32|15@1- (0.001,0) [0|0] "" Vector__XXX
 SG_ M27_CellVoltage10_Valid : 31|1@1+ (1,0) [0|0] "" Vector__XXX
 SG_ M27_CellVoltage10 : 16|15@1- (0.001,0) [0|0] "" Vector__XXX
 SG_ M27_CellVoltage9_Valid : 15|1@1+ (1,0) [0|0] "" Vector__XXX
 SG_ M27_CellVoltage9 : 0|15@1- (0.001,0) [0|0] "" Vector__XXX

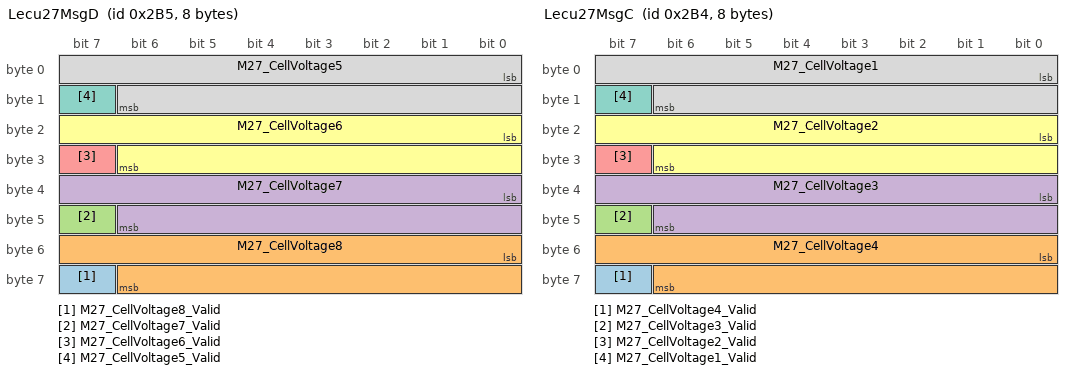
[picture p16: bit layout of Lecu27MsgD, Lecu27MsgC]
BO_ 693 Lecu27MsgD: 8 Vector__XXX
 SG_ M27_CellVoltage8_Valid : 63|1@1+ (1,0) [0|0] "" Vector__XXX
 SG_ M27_CellVoltage8 : 48|15@1- (0.001,0) [0|0] "" Vector__XXX
 SG_ M27_CellVoltage7_Valid : 47|1@1+ (1,0) [0|0] "" Vector__XXX
 SG_ M27_CellVoltage7 : 32|15@1- (0.001,0) [0|0] "" Vector__XXX
 SG_ M27_CellVoltage6_Valid : 31|1@1+ (1,0) [0|0] "" Vector__XXX
 SG_ M27_CellVoltage6 : 16|15@1- (0.001,0) [0|0] "" Vector__XXX
 SG_ M27_CellVoltage5_Valid : 15|1@1+ (1,0) [0|0] "" Vector__XXX
 SG_ M27_CellVoltage5 : 0|15@1- (0.001,0) [0|0] "" Vector__XXX

BO_ 692 Lecu27MsgC: 8 Vector__XXX
 SG_ M27_CellVoltage4_Valid : 63|1@1+ (1,0) [0|0] "" Vector__XXX
 SG_ M27_CellVoltage4 : 48|15@1- (0.001,0) [0|0] "" Vector__XXX
 SG_ M27_CellVoltage3_Valid : 47|1@1+ (1,0) [0|0] "" Vector__XXX
 SG_ M27_CellVoltage3 : 32|15@1- (0.001,0) [0|0] "" Vector__XXX
 SG_ M27_CellVoltage2_Valid : 31|1@1+ (1,0) [0|0] "" Vector__XXX
 SG_ M27_CellVoltage2 : 16|15@1- (0.001,0) [0|0] "" Vector__XXX
 SG_ M27_CellVoltage1_Valid : 15|1@1+ (1,0) [0|0] "" Vector__XXX
 SG_ M27_CellVoltage1 : 0|15@1- (0.001,0) [0|0] "" Vector__XXX

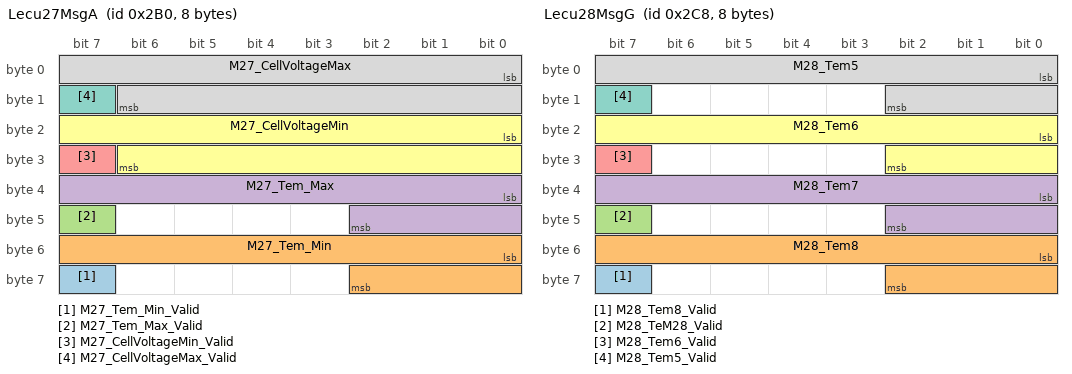
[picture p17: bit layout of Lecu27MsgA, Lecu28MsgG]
BO_ 688 Lecu27MsgA: 8 LECU27
 SG_ M27_Tem_Min_Valid : 63|1@1+ (1,0) [0|0] ""  BMU
 SG_ M27_Tem_Min : 48|11@1+ (0.1,-40) [0|0] "℃"  BMU
 SG_ M27_Tem_Max_Valid : 47|1@1+ (1,0) [0|0] ""  BMU
 SG_ M27_Tem_Max : 32|11@1+ (0.1,-40) [0|0] "℃"  BMU
 SG_ M27_CellVoltageMin_Valid : 31|1@1+ (1,0) [0|0] ""  BMU
 SG_ M27_CellVoltageMin : 16|15@1- (0.001,0) [0|0] "V"  BMU
 SG_ M27_CellVoltageMax_Valid : 15|1@1+ (1,0) [0|0] ""  BMU
 SG_ M27_CellVoltageMax : 0|15@1- (0.001,0) [0|0] "V"  BMU

BO_ 713 Lecu28MsgH: 8 Vector__XXX
 SG_ Lecu_Version3 : 63|8@0+ (1,0) [0|0] "" Vector__XXX
 SG_ Lecu_Version2 : 55|8@0+ (1,0) [0|0] "" Vector__XXX
 SG_ Lecu_Version1 : 47|8@0+ (1,0) [0|0] "" Vector__XXX
 SG_ Lecu_Version0 : 39|8@0+ (1,0) [0|0] "" Vector__XXX
 SG_ M28_CellBalance24 : 23|1@1+ (1,0) [0|0] "" Vector__XXX
 SG_ M28_CellBalance23 : 22|1@1+ (1,0) [0|0] "" Vector__XXX
 SG_ M28_CellBalance22 : 21|1@1+ (1,0) [0|0] "" Vector__XXX
 SG_ M28_CellBalance21 : 20|1@1+ (1,0) [0|0] "" Vector__XXX
 SG_ M28_CellBalance20 : 19|1@1+ (1,0) [0|0] "" Vector__XXX
 SG_ M28_CellBalance19 : 18|1@1+ (1,0) [0|0] "" Vector__XXX
 SG_ M28_CellBalance18 : 17|1@1+ (1,0) [0|0] "" Vector__XXX
 SG_ M28_CellBalance17 : 16|1@1+ (1,0) [0|0] "" Vector__XXX
 SG_ M28_CellBalance16 : 15|1@1+ (1,0) [0|0] "" Vector__XXX
 SG_ M28_CellBalance15 : 14|1@1+ (1,0) [0|0] "" Vector__XXX
 SG_ M28_CellBalance14 : 13|1@1+ (1,0) [0|0] "" Vector__XXX
 SG_ M28_CellBalance13 : 12|1@1+ (1,0) [0|0] "" Vector__XXX
 SG_ M28_CellBalance9 : 8|1@1+ (1,0) [0|0] "" Vector__XXX
 SG_ M28_CellBalance8 : 7|1@1+ (1,0) [0|0] "" Vector__XXX
 SG_ M28_CellBalance7 : 6|1@1+ (1,0) [0|0] "" Vector__XXX
 SG_ M28_CellBalance6 : 5|1@1+ (1,0) [0|0] "" Vector__XXX
 SG_ M28_CellBalance5 : 4|1@1+ (1,0) [0|0] "" Vector__XXX
 SG_ M28_CellBalance4 : 3|1@1+ (1,0) [0|0] "" Vector__XXX
 SG_ M28_CellBalance3 : 2|1@1+ (1,0) [0|0] "" Vector__XXX
 SG_ M28_CellBalance2 : 1|1@1+ (1,0) [0|0] "" Vector__XXX
 SG_ M28_CellBalance12 : 11|1@1+ (1,0) [0|0] "" Vector__XXX
 SG_ M28_CellBalance11 : 10|1@1+ (1,0) [0|0] "" Vector__XXX
 SG_ M28_CellBalance10 : 9|1@1+ (1,0) [0|0] "" Vector__XXX
 SG_ M28_CellBalance1 : 0|1@1+ (1,0) [0|0] "" Vector__XXX

BO_ 712 Lecu28MsgG: 8 Vector__XXX
 SG_ M28_Tem8_Valid : 63|1@1+ (1,0) [0|0] "" Vector__XXX
 SG_ M28_Tem8 : 48|11@1+ (0.1,-40) [0|0] "" Vector__XXX
 SG_ M28_TeM28_Valid : 47|1@1+ (1,0) [0|0] "" Vector__XXX
 SG_ M28_Tem7 : 32|11@1+ (0.1,-40) [0|0] "" Vector__XXX
 SG_ M28_Tem6_Valid : 31|1@1+ (1,0) [0|0] "" Vector__XXX
 SG_ M28_Tem6 : 16|11@1+ (0.1,-40) [0|0] "" Vector__XXX
 SG_ M28_Tem5_Valid : 15|1@1+ (1,0) [0|0] "" Vector__XXX
 SG_ M28_Tem5 : 0|11@1+ (0.1,-40) [0|0] "" Vector__XXX

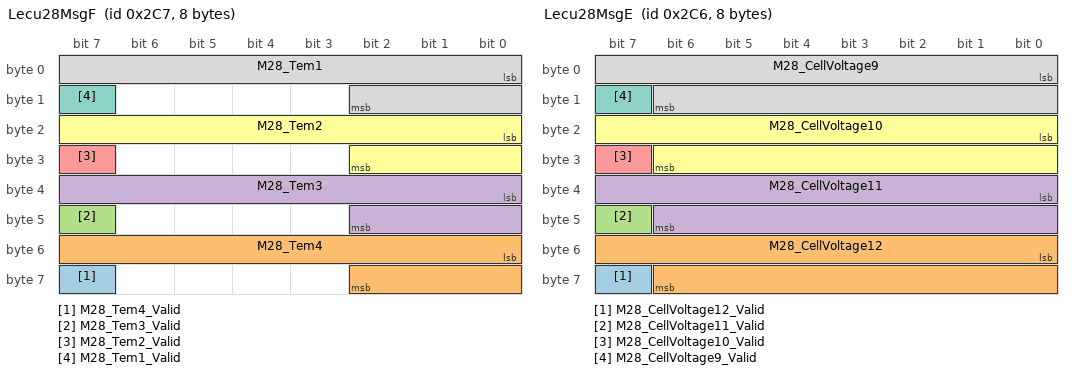
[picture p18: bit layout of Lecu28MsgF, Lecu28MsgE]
BO_ 711 Lecu28MsgF: 8 Vector__XXX
 SG_ M28_Tem4_Valid : 63|1@1+ (1,0) [0|0] "" Vector__XXX
 SG_ M28_Tem4 : 48|11@1+ (0.1,-40) [0|0] "" Vector__XXX
 SG_ M28_Tem3_Valid : 47|1@1+ (1,0) [0|0] "" Vector__XXX
 SG_ M28_Tem3 : 32|11@1+ (0.1,-40) [0|0] "" Vector__XXX
 SG_ M28_Tem2_Valid : 31|1@1+ (1,0) [0|0] "" Vector__XXX
 SG_ M28_Tem2 : 16|11@1+ (0.1,-40) [0|0] "" Vector__XXX
 SG_ M28_Tem1_Valid : 15|1@1+ (1,0) [0|0] "" Vector__XXX
 SG_ M28_Tem1 : 0|11@1+ (0.1,-40) [0|0] "" Vector__XXX

BO_ 710 Lecu28MsgE: 8 Vector__XXX
 SG_ M28_CellVoltage12_Valid : 63|1@1+ (1,0) [0|0] "" Vector__XXX
 SG_ M28_CellVoltage12 : 48|15@1- (0.001,0) [0|0] "" Vector__XXX
 SG_ M28_CellVoltage11_Valid : 47|1@1+ (1,0) [0|0] "" Vector__XXX
 SG_ M28_CellVoltage11 : 32|15@1- (0.001,0) [0|0] "" Vector__XXX
 SG_ M28_CellVoltage10_Valid : 31|1@1+ (1,0) [0|0] "" Vector__XXX
 SG_ M28_CellVoltage10 : 16|15@1- (0.001,0) [0|0] "" Vector__XXX
 SG_ M28_CellVoltage9_Valid : 15|1@1+ (1,0) [0|0] "" Vector__XXX
 SG_ M28_CellVoltage9 : 0|15@1- (0.001,0) [0|0] "" Vector__XXX

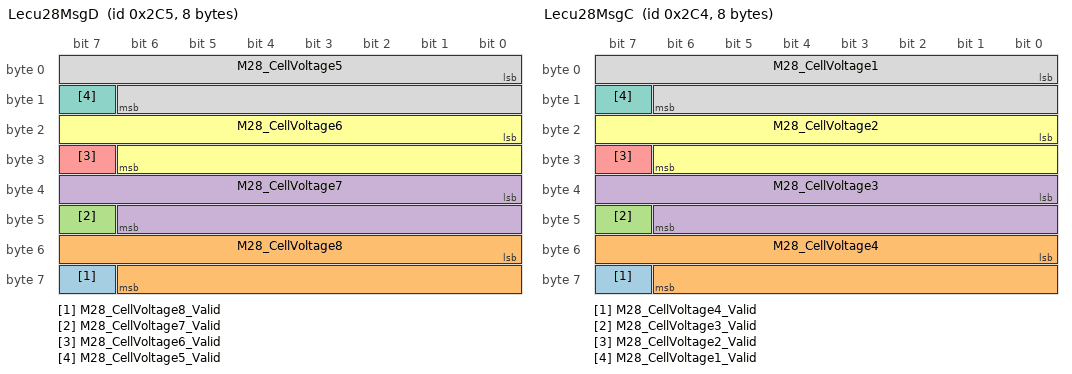
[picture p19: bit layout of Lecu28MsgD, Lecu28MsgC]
BO_ 709 Lecu28MsgD: 8 Vector__XXX
 SG_ M28_CellVoltage8_Valid : 63|1@1+ (1,0) [0|0] "" Vector__XXX
 SG_ M28_CellVoltage8 : 48|15@1- (0.001,0) [0|0] "" Vector__XXX
 SG_ M28_CellVoltage7_Valid : 47|1@1+ (1,0) [0|0] "" Vector__XXX
 SG_ M28_CellVoltage7 : 32|15@1- (0.001,0) [0|0] "" Vector__XXX
 SG_ M28_CellVoltage6_Valid : 31|1@1+ (1,0) [0|0] "" Vector__XXX
 SG_ M28_CellVoltage6 : 16|15@1- (0.001,0) [0|0] "" Vector__XXX
 SG_ M28_CellVoltage5_Valid : 15|1@1+ (1,0) [0|0] "" Vector__XXX
 SG_ M28_CellVoltage5 : 0|15@1- (0.001,0) [0|0] "" Vector__XXX

BO_ 708 Lecu28MsgC: 8 Vector__XXX
 SG_ M28_CellVoltage4_Valid : 63|1@1+ (1,0) [0|0] "" Vector__XXX
 SG_ M28_CellVoltage4 : 48|15@1- (0.001,0) [0|0] "" Vector__XXX
 SG_ M28_CellVoltage3_Valid : 47|1@1+ (1,0) [0|0] "" Vector__XXX
 SG_ M28_CellVoltage3 : 32|15@1- (0.001,0) [0|0] "" Vector__XXX
 SG_ M28_CellVoltage2_Valid : 31|1@1+ (1,0) [0|0] "" Vector__XXX
 SG_ M28_CellVoltage2 : 16|15@1- (0.001,0) [0|0] "" Vector__XXX
 SG_ M28_CellVoltage1_Valid : 15|1@1+ (1,0) [0|0] "" Vector__XXX
 SG_ M28_CellVoltage1 : 0|15@1- (0.001,0) [0|0] "" Vector__XXX

BO_ 704 Lecu28MsgA: 8 LECU28
 SG_ M28_Tem_Min_Valid : 63|1@1+ (1,0) [0|0] ""  BMU
 SG_ M28_Tem_Min : 48|11@1+ (0.1,-40) [0|0] "℃"  BMU
 SG_ M28_Tem_Max_Valid : 47|1@1+ (1,0) [0|0] ""  BMU
 SG_ M28_Tem_Max : 32|11@1+ (0.1,-40) [0|0] "℃"  BMU
 SG_ M28_CellVoltageMin_Valid : 31|1@1+ (1,0) [0|0] ""  BMU
 SG_ M28_CellVoltageMin : 16|15@1- (0.001,0) [0|0] "V"  BMU
 SG_ M28_CellVoltageMax_Valid : 15|1@1+ (1,0) [0|0] ""  BMU
 SG_ M28_CellVoltageMax : 0|15@1- (0.001,0) [0|0] "V"  BMU

BO_ 729 Lecu29MsgH: 8 Vector__XXX
 SG_ Lecu_Version3 : 63|8@0+ (1,0) [0|0] "" Vector__XXX
 SG_ Lecu_Version2 : 55|8@0+ (1,0) [0|0] "" Vector__XXX
 SG_ Lecu_Version1 : 47|8@0+ (1,0) [0|0] "" Vector__XXX
 SG_ Lecu_Version0 : 39|8@0+ (1,0) [0|0] "" Vector__XXX
 SG_ M29_CellBalance24 : 23|1@1+ (1,0) [0|0] "" Vector__XXX
 SG_ M29_CellBalance23 : 22|1@1+ (1,0) [0|0] "" Vector__XXX
 SG_ M29_CellBalance22 : 21|1@1+ (1,0) [0|0] "" Vector__XXX
 SG_ M29_CellBalance21 : 20|1@1+ (1,0) [0|0] "" Vector__XXX
 SG_ M29_CellBalance20 : 19|1@1+ (1,0) [0|0] "" Vector__XXX
 SG_ M29_CellBalance19 : 18|1@1+ (1,0) [0|0] "" Vector__XXX
 SG_ M29_CellBalance18 : 17|1@1+ (1,0) [0|0] "" Vector__XXX
 SG_ M29_CellBalance17 : 16|1@1+ (1,0) [0|0] "" Vector__XXX
 SG_ M29_CellBalance16 : 15|1@1+ (1,0) [0|0] "" Vector__XXX
 SG_ M29_CellBalance15 : 14|1@1+ (1,0) [0|0] "" Vector__XXX
 SG_ M29_CellBalance14 : 13|1@1+ (1,0) [0|0] "" Vector__XXX
 SG_ M29_CellBalance13 : 12|1@1+ (1,0) [0|0] "" Vector__XXX
 SG_ M29_CellBalance9 : 8|1@1+ (1,0) [0|0] "" Vector__XXX
 SG_ M29_CellBalance8 : 7|1@1+ (1,0) [0|0] "" Vector__XXX
 SG_ M29_CellBalance7 : 6|1@1+ (1,0) [0|0] "" Vector__XXX
 SG_ M29_CellBalance6 : 5|1@1+ (1,0) [0|0] "" Vector__XXX
 SG_ M29_CellBalance5 : 4|1@1+ (1,0) [0|0] "" Vector__XXX
 SG_ M29_CellBalance4 : 3|1@1+ (1,0) [0|0] "" Vector__XXX
 SG_ M29_CellBalance3 : 2|1@1+ (1,0) [0|0] "" Vector__XXX
 SG_ M29_CellBalance2 : 1|1@1+ (1,0) [0|0] "" Vector__XXX
 SG_ M29_CellBalance12 : 11|1@1+ (1,0) [0|0] "" Vector__XXX
 SG_ M29_CellBalance11 : 10|1@1+ (1,0) [0|0] "" Vector__XXX
 SG_ M29_CellBalance10 : 9|1@1+ (1,0) [0|0] "" Vector__XXX
 SG_ M29_CellBalance1 : 0|1@1+ (1,0) [0|0] "" Vector__XXX

BO_ 728 Lecu29MsgG: 8 Vector__XXX
 SG_ M29_Tem8_Valid : 63|1@1+ (1,0) [0|0] "" Vector__XXX
 SG_ M29_Tem8 : 48|11@1+ (0.1,-40) [0|0] "" Vector__XXX
 SG_ M29_TeM29_Valid : 47|1@1+ (1,0) [0|0] "" Vector__XXX
 SG_ M29_Tem7 : 32|11@1+ (0.1,-40) [0|0] "" Vector__XXX
 SG_ M29_Tem6_Valid : 31|1@1+ (1,0) [0|0] "" Vector__XXX
 SG_ M29_Tem6 : 16|11@1+ (0.1,-40) [0|0] "" Vector__XXX
 SG_ M29_Tem5_Valid : 15|1@1+ (1,0) [0|0] "" Vector__XXX
 SG_ M29_Tem5 : 0|11@1+ (0.1,-40) [0|0] "" Vector__XXX

BO_ 727 Lecu29MsgF: 8 Vector__XXX
 SG_ M29_Tem4_Valid : 63|1@1+ (1,0) [0|0] "" Vector__XXX
 SG_ M29_Tem4 : 48|11@1+ (0.1,-40) [0|0] "" Vector__XXX
 SG_ M29_Tem3_Valid : 47|1@1+ (1,0) [0|0] "" Vector__XXX
 SG_ M29_Tem3 : 32|11@1+ (0.1,-40) [0|0] "" Vector__XXX
 SG_ M29_Tem2_Valid : 31|1@1+ (1,0) [0|0] "" Vector__XXX
 SG_ M29_Tem2 : 16|11@1+ (0.1,-40) [0|0] "" Vector__XXX
 SG_ M29_Tem1_Valid : 15|1@1+ (1,0) [0|0] "" Vector__XXX
 SG_ M29_Tem1 : 0|11@1+ (0.1,-40) [0|0] "" Vector__XXX

BO_ 726 Lecu29MsgE: 8 Vector__XXX
 SG_ M29_CellVoltage12_Valid : 63|1@1+ (1,0) [0|0] "" Vector__XXX
 SG_ M29_CellVoltage12 : 48|15@1- (0.001,0) [0|0] "" Vector__XXX
 SG_ M29_CellVoltage11_Valid : 47|1@1+ (1,0) [0|0] "" Vector__XXX
 SG_ M29_CellVoltage11 : 32|15@1- (0.001,0) [0|0] "" Vector__XXX
 SG_ M29_CellVoltage10_Valid : 31|1@1+ (1,0) [0|0] "" Vector__XXX
 SG_ M29_CellVoltage10 : 16|15@1- (0.001,0) [0|0] "" Vector__XXX
 SG_ M29_CellVoltage9_Valid : 15|1@1+ (1,0) [0|0] "" Vector__XXX
 SG_ M29_CellVoltage9 : 0|15@1- (0.001,0) [0|0] "" Vector__XXX

BO_ 725 Lecu29MsgD: 8 Vector__XXX
 SG_ M29_CellVoltage8_Valid : 63|1@1+ (1,0) [0|0] "" Vector__XXX
 SG_ M29_CellVoltage8 : 48|15@1- (0.001,0) [0|0] "" Vector__XXX
 SG_ M29_CellVoltage7_Valid : 47|1@1+ (1,0) [0|0] "" Vector__XXX
 SG_ M29_CellVoltage7 : 32|15@1- (0.001,0) [0|0] "" Vector__XXX
 SG_ M29_CellVoltage6_Valid : 31|1@1+ (1,0) [0|0] "" Vector__XXX
 SG_ M29_CellVoltage6 : 16|15@1- (0.001,0) [0|0] "" Vector__XXX
 SG_ M29_CellVoltage5_Valid : 15|1@1+ (1,0) [0|0] "" Vector__XXX
 SG_ M29_CellVoltage5 : 0|15@1- (0.001,0) [0|0] "" Vector__XXX

BO_ 724 Lecu29MsgC: 8 Vector__XXX
 SG_ M29_CellVoltage4_Valid : 63|1@1+ (1,0) [0|0] "" Vector__XXX
 SG_ M29_CellVoltage4 : 48|15@1- (0.001,0) [0|0] "" Vector__XXX
 SG_ M29_CellVoltage3_Valid : 47|1@1+ (1,0) [0|0] "" Vector__XXX
 SG_ M29_CellVoltage3 : 32|15@1- (0.001,0) [0|0] "" Vector__XXX
 SG_ M29_CellVoltage2_Valid : 31|1@1+ (1,0) [0|0] "" Vector__XXX
 SG_ M29_CellVoltage2 : 16|15@1- (0.001,0) [0|0] "" Vector__XXX
 SG_ M29_CellVoltage1_Valid : 15|1@1+ (1,0) [0|0] "" Vector__XXX
 SG_ M29_CellVoltage1 : 0|15@1- (0.001,0) [0|0] "" Vector__XXX

BO_ 720 Lecu29MsgA: 8 LECU29
 SG_ M29_Tem_Min_Valid : 63|1@1+ (1,0) [0|0] ""  BMU
 SG_ M29_Tem_Min : 48|11@1+ (0.1,-40) [0|0] "℃"  BMU
 SG_ M29_Tem_Max_Valid : 47|1@1+ (1,0) [0|0] ""  BMU
 SG_ M29_Tem_Max : 32|11@1+ (0.1,-40) [0|0] "℃"  BMU
 SG_ M29_CellVoltageMin_Valid : 31|1@1+ (1,0) [0|0] ""  BMU
 SG_ M29_CellVoltageMin : 16|15@1- (0.001,0) [0|0] "V"  BMU
 SG_ M29_CellVoltageMax_Valid : 15|1@1+ (1,0) [0|0] ""  BMU
 SG_ M29_CellVoltageMax : 0|15@1- (0.001,0) [0|0] "V"  BMU

BO_ 745 Lecu30MsgH: 8 Vector__XXX
 SG_ Lecu_Version3 : 63|8@0+ (1,0) [0|0] "" Vector__XXX
 SG_ Lecu_Version2 : 55|8@0+ (1,0) [0|0] "" Vector__XXX
 SG_ Lecu_Version1 : 47|8@0+ (1,0) [0|0] "" Vector__XXX
 SG_ Lecu_Version0 : 39|8@0+ (1,0) [0|0] "" Vector__XXX
 SG_ M30_CellBalance24 : 23|1@1+ (1,0) [0|0] "" Vector__XXX
 SG_ M30_CellBalance23 : 22|1@1+ (1,0) [0|0] "" Vector__XXX
 SG_ M30_CellBalance22 : 21|1@1+ (1,0) [0|0] "" Vector__XXX
 SG_ M30_CellBalance21 : 20|1@1+ (1,0) [0|0] "" Vector__XXX
 SG_ M30_CellBalance20 : 19|1@1+ (1,0) [0|0] "" Vector__XXX
 SG_ M30_CellBalance19 : 18|1@1+ (1,0) [0|0] "" Vector__XXX
 SG_ M30_CellBalance18 : 17|1@1+ (1,0) [0|0] "" Vector__XXX
 SG_ M30_CellBalance17 : 16|1@1+ (1,0) [0|0] "" Vector__XXX
 SG_ M30_CellBalance16 : 15|1@1+ (1,0) [0|0] "" Vector__XXX
 SG_ M30_CellBalance15 : 14|1@1+ (1,0) [0|0] "" Vector__XXX
 SG_ M30_CellBalance14 : 13|1@1+ (1,0) [0|0] "" Vector__XXX
 SG_ M30_CellBalance13 : 12|1@1+ (1,0) [0|0] "" Vector__XXX
 SG_ M30_CellBalance9 : 8|1@1+ (1,0) [0|0] "" Vector__XXX
 SG_ M30_CellBalance8 : 7|1@1+ (1,0) [0|0] "" Vector__XXX
 SG_ M30_CellBalance7 : 6|1@1+ (1,0) [0|0] "" Vector__XXX
 SG_ M30_CellBalance6 : 5|1@1+ (1,0) [0|0] "" Vector__XXX
 SG_ M30_CellBalance5 : 4|1@1+ (1,0) [0|0] "" Vector__XXX
 SG_ M30_CellBalance4 : 3|1@1+ (1,0) [0|0] "" Vector__XXX
 SG_ M30_CellBalance3 : 2|1@1+ (1,0) [0|0] "" Vector__XXX
 SG_ M30_CellBalance2 : 1|1@1+ (1,0) [0|0] "" Vector__XXX
 SG_ M30_CellBalance12 : 11|1@1+ (1,0) [0|0] "" Vector__XXX
 SG_ M30_CellBalance11 : 10|1@1+ (1,0) [0|0] "" Vector__XXX
 SG_ M30_CellBalance10 : 9|1@1+ (1,0) [0|0] "" Vector__XXX
 SG_ M30_CellBalance1 : 0|1@1+ (1,0) [0|0] "" Vector__XXX

BO_ 744 Lecu30MsgG: 8 Vector__XXX
 SG_ M30_Tem8_Valid : 63|1@1+ (1,0) [0|0] "" Vector__XXX
 SG_ M30_Tem8 : 48|11@1+ (0.1,-40) [0|0] "" Vector__XXX
 SG_ M30_TeM30_Valid : 47|1@1+ (1,0) [0|0] "" Vector__XXX
 SG_ M30_Tem7 : 32|11@1+ (0.1,-40) [0|0] "" Vector__XXX
 SG_ M30_Tem6_Valid : 31|1@1+ (1,0) [0|0] "" Vector__XXX
 SG_ M30_Tem6 : 16|11@1+ (0.1,-40) [0|0] "" Vector__XXX
 SG_ M30_Tem5_Valid : 15|1@1+ (1,0) [0|0] "" Vector__XXX
 SG_ M30_Tem5 : 0|11@1+ (0.1,-40) [0|0] "" Vector__XXX

BO_ 743 Lecu30MsgF: 8 Vector__XXX
 SG_ M30_Tem4_Valid : 63|1@1+ (1,0) [0|0] "" Vector__XXX
 SG_ M30_Tem4 : 48|11@1+ (0.1,-40) [0|0] "" Vector__XXX
 SG_ M30_Tem3_Valid : 47|1@1+ (1,0) [0|0] "" Vector__XXX
 SG_ M30_Tem3 : 32|11@1+ (0.1,-40) [0|0] "" Vector__XXX
 SG_ M30_Tem2_Valid : 31|1@1+ (1,0) [0|0] "" Vector__XXX
 SG_ M30_Tem2 : 16|11@1+ (0.1,-40) [0|0] "" Vector__XXX
 SG_ M30_Tem1_Valid : 15|1@1+ (1,0) [0|0] "" Vector__XXX
 SG_ M30_Tem1 : 0|11@1+ (0.1,-40) [0|0] "" Vector__XXX

BO_ 742 Lecu30MsgE: 8 Vector__XXX
 SG_ M30_CellVoltage12_Valid : 63|1@1+ (1,0) [0|0] "" Vector__XXX
 SG_ M30_CellVoltage12 : 48|15@1- (0.001,0) [0|0] "" Vector__XXX
 SG_ M30_CellVoltage11_Valid : 47|1@1+ (1,0) [0|0] "" Vector__XXX
 SG_ M30_CellVoltage11 : 32|15@1- (0.001,0) [0|0] "" Vector__XXX
 SG_ M30_CellVoltage10_Valid : 31|1@1+ (1,0) [0|0] "" Vector__XXX
 SG_ M30_CellVoltage10 : 16|15@1- (0.001,0) [0|0] "" Vector__XXX
 SG_ M30_CellVoltage9_Valid : 15|1@1+ (1,0) [0|0] "" Vector__XXX
 SG_ M30_CellVoltage9 : 0|15@1- (0.001,0) [0|0] "" Vector__XXX

BO_ 741 Lecu30MsgD: 8 Vector__XXX
 SG_ M30_CellVoltage8_Valid : 63|1@1+ (1,0) [0|0] "" Vector__XXX
 SG_ M30_CellVoltage8 : 48|15@1- (0.001,0) [0|0] "" Vector__XXX
 SG_ M30_CellVoltage7_Valid : 47|1@1+ (1,0) [0|0] "" Vector__XXX
 SG_ M30_CellVoltage7 : 32|15@1- (0.001,0) [0|0] "" Vector__XXX
 SG_ M30_CellVoltage6_Valid : 31|1@1+ (1,0) [0|0] "" Vector__XXX
 SG_ M30_CellVoltage6 : 16|15@1- (0.001,0) [0|0] "" Vector__XXX
 SG_ M30_CellVoltage5_Valid : 15|1@1+ (1,0) [0|0] "" Vector__XXX
 SG_ M30_CellVoltage5 : 0|15@1- (0.001,0) [0|0] "" Vector__XXX

BO_ 740 Lecu30MsgC: 8 Vector__XXX
 SG_ M30_CellVoltage4_Valid : 63|1@1+ (1,0) [0|0] "" Vector__XXX
 SG_ M30_CellVoltage4 : 48|15@1- (0.001,0) [0|0] "" Vector__XXX
 SG_ M30_CellVoltage3_Valid : 47|1@1+ (1,0) [0|0] "" Vector__XXX
 SG_ M30_CellVoltage3 : 32|15@1- (0.001,0) [0|0] "" Vector__XXX
 SG_ M30_CellVoltage2_Valid : 31|1@1+ (1,0) [0|0] "" Vector__XXX
 SG_ M30_CellVoltage2 : 16|15@1- (0.001,0) [0|0] "" Vector__XXX
 SG_ M30_CellVoltage1_Valid : 15|1@1+ (1,0) [0|0] "" Vector__XXX
 SG_ M30_CellVoltage1 : 0|15@1- (0.001,0) [0|0] "" Vector__XXX

BO_ 736 Lecu30MsgA: 8 LECU30
 SG_ M30_Tem_Min_Valid : 63|1@1+ (1,0) [0|0] ""  BMU
 SG_ M30_Tem_Min : 48|11@1+ (0.1,-40) [0|0] "℃"  BMU
 SG_ M30_Tem_Max_Valid : 47|1@1+ (1,0) [0|0] ""  BMU
 SG_ M30_Tem_Max : 32|11@1+ (0.1,-40) [0|0] "℃"  BMU
 SG_ M30_CellVoltageMin_Valid : 31|1@1+ (1,0) [0|0] ""  BMU
 SG_ M30_CellVoltageMin : 16|15@1- (0.001,0) [0|0] "V"  BMU
 SG_ M30_CellVoltageMax_Valid : 15|1@1+ (1,0) [0|0] ""  BMU
 SG_ M30_CellVoltageMax : 0|15@1- (0.001,0) [0|0] "V"  BMU

BO_ 761 Lecu31MsgH: 8 Vector__XXX
 SG_ Lecu_Version3 : 63|8@0+ (1,0) [0|0] "" Vector__XXX
 SG_ Lecu_Version2 : 55|8@0+ (1,0) [0|0] "" Vector__XXX
 SG_ Lecu_Version1 : 47|8@0+ (1,0) [0|0] "" Vector__XXX
 SG_ Lecu_Version0 : 39|8@0+ (1,0) [0|0] "" Vector__XXX
 SG_ M31_CellBalance24 : 23|1@1+ (1,0) [0|0] "" Vector__XXX
 SG_ M31_CellBalance23 : 22|1@1+ (1,0) [0|0] "" Vector__XXX
 SG_ M31_CellBalance22 : 21|1@1+ (1,0) [0|0] "" Vector__XXX
 SG_ M31_CellBalance21 : 20|1@1+ (1,0) [0|0] "" Vector__XXX
 SG_ M31_CellBalance20 : 19|1@1+ (1,0) [0|0] "" Vector__XXX
 SG_ M31_CellBalance19 : 18|1@1+ (1,0) [0|0] "" Vector__XXX
 SG_ M31_CellBalance18 : 17|1@1+ (1,0) [0|0] "" Vector__XXX
 SG_ M31_CellBalance17 : 16|1@1+ (1,0) [0|0] "" Vector__XXX
 SG_ M31_CellBalance16 : 15|1@1+ (1,0) [0|0] "" Vector__XXX
 SG_ M31_CellBalance15 : 14|1@1+ (1,0) [0|0] "" Vector__XXX
 SG_ M31_CellBalance14 : 13|1@1+ (1,0) [0|0] "" Vector__XXX
 SG_ M31_CellBalance13 : 12|1@1+ (1,0) [0|0] "" Vector__XXX
 SG_ M31_CellBalance9 : 8|1@1+ (1,0) [0|0] "" Vector__XXX
 SG_ M31_CellBalance8 : 7|1@1+ (1,0) [0|0] "" Vector__XXX
 SG_ M31_CellBalance7 : 6|1@1+ (1,0) [0|0] "" Vector__XXX
 SG_ M31_CellBalance6 : 5|1@1+ (1,0) [0|0] "" Vector__XXX
 SG_ M31_CellBalance5 : 4|1@1+ (1,0) [0|0] "" Vector__XXX
 SG_ M31_CellBalance4 : 3|1@1+ (1,0) [0|0] "" Vector__XXX
 SG_ M31_CellBalance3 : 2|1@1+ (1,0) [0|0] "" Vector__XXX
 SG_ M31_CellBalance2 : 1|1@1+ (1,0) [0|0] "" Vector__XXX
 SG_ M31_CellBalance12 : 11|1@1+ (1,0) [0|0] "" Vector__XXX
 SG_ M31_CellBalance11 : 10|1@1+ (1,0) [0|0] "" Vector__XXX
 SG_ M31_CellBalance10 : 9|1@1+ (1,0) [0|0] "" Vector__XXX
 SG_ M31_CellBalance1 : 0|1@1+ (1,0) [0|0] "" Vector__XXX

BO_ 760 Lecu31MsgG: 8 Vector__XXX
 SG_ M31_Tem8_Valid : 63|1@1+ (1,0) [0|0] "" Vector__XXX
 SG_ M31_Tem8 : 48|11@1+ (0.1,-40) [0|0] "" Vector__XXX
 SG_ M31_TeM31_Valid : 47|1@1+ (1,0) [0|0] "" Vector__XXX
 SG_ M31_Tem7 : 32|11@1+ (0.1,-40) [0|0] "" Vector__XXX
 SG_ M31_Tem6_Valid : 31|1@1+ (1,0) [0|0] "" Vector__XXX
 SG_ M31_Tem6 : 16|11@1+ (0.1,-40) [0|0] "" Vector__XXX
 SG_ M31_Tem5_Valid : 15|1@1+ (1,0) [0|0] "" Vector__XXX
 SG_ M31_Tem5 : 0|11@1+ (0.1,-40) [0|0] "" Vector__XXX

BO_ 759 Lecu31MsgF: 8 Vector__XXX
 SG_ M31_Tem4_Valid : 63|1@1+ (1,0) [0|0] "" Vector__XXX
 SG_ M31_Tem4 : 48|11@1+ (0.1,-40) [0|0] "" Vector__XXX
 SG_ M31_Tem3_Valid : 47|1@1+ (1,0) [0|0] "" Vector__XXX
 SG_ M31_Tem3 : 32|11@1+ (0.1,-40) [0|0] "" Vector__XXX
 SG_ M31_Tem2_Valid : 31|1@1+ (1,0) [0|0] "" Vector__XXX
 SG_ M31_Tem2 : 16|11@1+ (0.1,-40) [0|0] "" Vector__XXX
 SG_ M31_Tem1_Valid : 15|1@1+ (1,0) [0|0] "" Vector__XXX
 SG_ M31_Tem1 : 0|11@1+ (0.1,-40) [0|0] "" Vector__XXX

BO_ 758 Lecu31MsgE: 8 Vector__XXX
 SG_ M31_CellVoltage12_Valid : 63|1@1+ (1,0) [0|0] "" Vector__XXX
 SG_ M31_CellVoltage12 : 48|15@1- (0.001,0) [0|0] "" Vector__XXX
 SG_ M31_CellVoltage11_Valid : 47|1@1+ (1,0) [0|0] "" Vector__XXX
 SG_ M31_CellVoltage11 : 32|15@1- (0.001,0) [0|0] "" Vector__XXX
 SG_ M31_CellVoltage10_Valid : 31|1@1+ (1,0) [0|0] "" Vector__XXX
 SG_ M31_CellVoltage10 : 16|15@1- (0.001,0) [0|0] "" Vector__XXX
 SG_ M31_CellVoltage9_Valid : 15|1@1+ (1,0) [0|0] "" Vector__XXX
 SG_ M31_CellVoltage9 : 0|15@1- (0.001,0) [0|0] "" Vector__XXX

BO_ 757 Lecu31MsgD: 8 Vector__XXX
 SG_ M31_CellVoltage8_Valid : 63|1@1+ (1,0) [0|0] "" Vector__XXX
 SG_ M31_CellVoltage8 : 48|15@1- (0.001,0) [0|0] "" Vector__XXX
 SG_ M31_CellVoltage7_Valid : 47|1@1+ (1,0) [0|0] "" Vector__XXX
 SG_ M31_CellVoltage7 : 32|15@1- (0.001,0) [0|0] "" Vector__XXX
 SG_ M31_CellVoltage6_Valid : 31|1@1+ (1,0) [0|0] "" Vector__XXX
 SG_ M31_CellVoltage6 : 16|15@1- (0.001,0) [0|0] "" Vector__XXX
 SG_ M31_CellVoltage5_Valid : 15|1@1+ (1,0) [0|0] "" Vector__XXX
 SG_ M31_CellVoltage5 : 0|15@1- (0.001,0) [0|0] "" Vector__XXX

BO_ 756 Lecu31MsgC: 8 Vector__XXX
 SG_ M31_CellVoltage4_Valid : 63|1@1+ (1,0) [0|0] "" Vector__XXX
 SG_ M31_CellVoltage4 : 48|15@1- (0.001,0) [0|0] "" Vector__XXX
 SG_ M31_CellVoltage3_Valid : 47|1@1+ (1,0) [0|0] "" Vector__XXX
 SG_ M31_CellVoltage3 : 32|15@1- (0.001,0) [0|0] "" Vector__XXX
 SG_ M31_CellVoltage2_Valid : 31|1@1+ (1,0) [0|0] "" Vector__XXX
 SG_ M31_CellVoltage2 : 16|15@1- (0.001,0) [0|0] "" Vector__XXX
 SG_ M31_CellVoltage1_Valid : 15|1@1+ (1,0) [0|0] "" Vector__XXX
 SG_ M31_CellVoltage1 : 0|15@1- (0.001,0) [0|0] "" Vector__XXX

BO_ 752 Lecu31MsgA: 8 LECU31
 SG_ M31_Tem_Min_Valid : 63|1@1+ (1,0) [0|0] ""  BMU
 SG_ M31_Tem_Min : 48|11@1+ (0.1,-40) [0|0] "℃"  BMU
 SG_ M31_Tem_Max_Valid : 47|1@1+ (1,0) [0|0] ""  BMU
 SG_ M31_Tem_Max : 32|11@1+ (0.1,-40) [0|0] "℃"  BMU
 SG_ M31_CellVoltageMin_Valid : 31|1@1+ (1,0) [0|0] ""  BMU
 SG_ M31_CellVoltageMin : 16|15@1- (0.001,0) [0|0] "V"  BMU
 SG_ M31_CellVoltageMax_Valid : 15|1@1+ (1,0) [0|0] ""  BMU
 SG_ M31_CellVoltageMax : 0|15@1- (0.001,0) [0|0] "V"  BMU

BO_ 283 Lecu1MsgJ: 8 Vector__XXX
 SG_ M1_Time_Cell8Balance : 48|16@1+ (0.5,0) [0|0] "Hour" Vector__XXX
 SG_ M1_Time_Cell7Balance : 32|16@1+ (0.5,0) [0|0] "Hour" Vector__XXX
 SG_ M1_Time_Cell6Balance : 16|16@1+ (0.5,0) [0|0] "Hour" Vector__XXX
 SG_ M1_Time_Cell5Balance : 0|16@1+ (0.5,0) [0|0] "Hour" Vector__XXX

BO_ 282 Lecu1MsgI: 8 Vector__XXX
 SG_ M1_Time_Cell4Balance : 48|16@1+ (0.5,0) [0|0] "Hour" Vector__XXX
 SG_ M1_Time_Cell3Balance : 32|16@1+ (0.5,0) [0|0] "Hour" Vector__XXX
 SG_ M1_Time_Cell2Balance : 16|16@1+ (0.5,0) [0|0] "Hour" Vector__XXX
 SG_ M1_Time_Cell1Balance : 0|16@1+ (0.5,0) [0|0] "Hour" Vector__XXX

BO_ 505 Lecu15MsgH: 8 Vector__XXX
 SG_ Lecu_Version3 : 63|8@0+ (1,0) [0|0] "" Vector__XXX
 SG_ Lecu_Version2 : 55|8@0+ (1,0) [0|0] "" Vector__XXX
 SG_ Lecu_Version1 : 47|8@0+ (1,0) [0|0] "" Vector__XXX
 SG_ Lecu_Version0 : 39|8@0+ (1,0) [0|0] "" Vector__XXX
 SG_ M15_CellBalance24 : 23|1@1+ (1,0) [0|0] "" Vector__XXX
 SG_ M15_CellBalance23 : 22|1@1+ (1,0) [0|0] "" Vector__XXX
 SG_ M15_CellBalance22 : 21|1@1+ (1,0) [0|0] "" Vector__XXX
 SG_ M15_CellBalance21 : 20|1@1+ (1,0) [0|0] "" Vector__XXX
 SG_ M15_CellBalance20 : 19|1@1+ (1,0) [0|0] "" Vector__XXX
 SG_ M15_CellBalance19 : 18|1@1+ (1,0) [0|0] "" Vector__XXX
 SG_ M15_CellBalance18 : 17|1@1+ (1,0) [0|0] "" Vector__XXX
 SG_ M15_CellBalance17 : 16|1@1+ (1,0) [0|0] "" Vector__XXX
 SG_ M15_CellBalance16 : 15|1@1+ (1,0) [0|0] "" Vector__XXX
 SG_ M15_CellBalance15 : 14|1@1+ (1,0) [0|0] "" Vector__XXX
 SG_ M15_CellBalance14 : 13|1@1+ (1,0) [0|0] "" Vector__XXX
 SG_ M15_CellBalance13 : 12|1@1+ (1,0) [0|0] "" Vector__XXX
 SG_ M15_CellBalance9 : 8|1@1+ (1,0) [0|0] "" Vector__XXX
 SG_ M15_CellBalance8 : 7|1@1+ (1,0) [0|0] "" Vector__XXX
 SG_ M15_CellBalance7 : 6|1@1+ (1,0) [0|0] "" Vector__XXX
 SG_ M15_CellBalance6 : 5|1@1+ (1,0) [0|0] "" Vector__XXX
 SG_ M15_CellBalance5 : 4|1@1+ (1,0) [0|0] "" Vector__XXX
 SG_ M15_CellBalance4 : 3|1@1+ (1,0) [0|0] "" Vector__XXX
 SG_ M15_CellBalance3 : 2|1@1+ (1,0) [0|0] "" Vector__XXX
 SG_ M15_CellBalance2 : 1|1@1+ (1,0) [0|0] "" Vector__XXX
 SG_ M15_CellBalance12 : 11|1@1+ (1,0) [0|0] "" Vector__XXX
 SG_ M15_CellBalance11 : 10|1@1+ (1,0) [0|0] "" Vector__XXX
 SG_ M15_CellBalance10 : 9|1@1+ (1,0) [0|0] "" Vector__XXX
 SG_ M15_CellBalance1 : 0|1@1+ (1,0) [0|0] "" Vector__XXX

BO_ 504 Lecu15MsgG: 8 Vector__XXX
 SG_ M15_Tem8_Valid : 63|1@1+ (1,0) [0|0] "" Vector__XXX
 SG_ M15_Tem8 : 48|11@1+ (0.1,-40) [0|0] "" Vector__XXX
 SG_ M15_Tem7_Valid : 47|1@1+ (1,0) [0|0] "" Vector__XXX
 SG_ M15_Tem7 : 32|11@1+ (0.1,-40) [0|0] "" Vector__XXX
 SG_ M15_Tem6_Valid : 31|1@1+ (1,0) [0|0] "" Vector__XXX
 SG_ M15_Tem6 : 16|11@1+ (0.1,-40) [0|0] "" Vector__XXX
 SG_ M15_Tem5_Valid : 15|1@1+ (1,0) [0|0] "" Vector__XXX
 SG_ M15_Tem5 : 0|11@1+ (0.1,-40) [0|0] "" Vector__XXX

BO_ 503 Lecu15MsgF: 8 Vector__XXX
 SG_ M15_Tem4_Valid : 63|1@1+ (1,0) [0|0] "" Vector__XXX
 SG_ M15_Tem4 : 48|11@1+ (0.1,-40) [0|0] "" Vector__XXX
 SG_ M15_Tem3_Valid : 47|1@1+ (1,0) [0|0] "" Vector__XXX
 SG_ M15_Tem3 : 32|11@1+ (0.1,-40) [0|0] "" Vector__XXX
 SG_ M15_Tem2_Valid : 31|1@1+ (1,0) [0|0] "" Vector__XXX
 SG_ M15_Tem2 : 16|11@1+ (0.1,-40) [0|0] "" Vector__XXX
 SG_ M15_Tem1_Valid : 15|1@1+ (1,0) [0|0] "" Vector__XXX
 SG_ M15_Tem1 : 0|11@1+ (0.1,-40) [0|0] "" Vector__XXX

BO_ 502 Lecu15MsgE: 8 Vector__XXX
 SG_ M15_CellVoltage12_Valid : 63|1@1+ (1,0) [0|0] "" Vector__XXX
 SG_ M15_CellVoltage12 : 48|15@1- (0.001,0) [0|0] "" Vector__XXX
 SG_ M15_CellVoltage11_Valid : 47|1@1+ (1,0) [0|0] "" Vector__XXX
 SG_ M15_CellVoltage11 : 32|15@1- (0.001,0) [0|0] "" Vector__XXX
 SG_ M15_CellVoltage10_Valid : 31|1@1+ (1,0) [0|0] "" Vector__XXX
 SG_ M15_CellVoltage10 : 16|15@1- (0.001,0) [0|0] "" Vector__XXX
 SG_ M15_CellVoltage9_Valid : 15|1@1+ (1,0) [0|0] "" Vector__XXX
 SG_ M15_CellVoltage9 : 0|15@1- (0.001,0) [0|0] "" Vector__XXX

BO_ 501 Lecu15MsgD: 8 Vector__XXX
 SG_ M15_CellVoltage8_Valid : 63|1@1+ (1,0) [0|0] "" Vector__XXX
 SG_ M15_CellVoltage8 : 48|15@1- (0.001,0) [0|0] "" Vector__XXX
 SG_ M15_CellVoltage7_Valid : 47|1@1+ (1,0) [0|0] "" Vector__XXX
 SG_ M15_CellVoltage7 : 32|15@1- (0.001,0) [0|0] "" Vector__XXX
 SG_ M15_CellVoltage6_Valid : 31|1@1+ (1,0) [0|0] "" Vector__XXX
 SG_ M15_CellVoltage6 : 16|15@1- (0.001,0) [0|0] "" Vector__XXX
 SG_ M15_CellVoltage5_Valid : 15|1@1+ (1,0) [0|0] "" Vector__XXX
 SG_ M15_CellVoltage5 : 0|15@1- (0.001,0) [0|0] "" Vector__XXX

BO_ 500 Lecu15MsgC: 8 Vector__XXX
 SG_ M15_CellVoltage4_Valid : 63|1@1+ (1,0) [0|0] "" Vector__XXX
 SG_ M15_CellVoltage4 : 48|15@1- (0.001,0) [0|0] "" Vector__XXX
 SG_ M15_CellVoltage3_Valid : 47|1@1+ (1,0) [0|0] "" Vector__XXX
 SG_ M15_CellVoltage3 : 32|15@1- (0.001,0) [0|0] "" Vector__XXX
 SG_ M15_CellVoltage2_Valid : 31|1@1+ (1,0) [0|0] "" Vector__XXX
 SG_ M15_CellVoltage2 : 16|15@1- (0.001,0) [0|0] "" Vector__XXX
 SG_ M15_CellVoltage1_Valid : 15|1@1+ (1,0) [0|0] "" Vector__XXX
 SG_ M15_CellVoltage1 : 0|15@1- (0.001,0) [0|0] "" Vector__XXX

BO_ 496 Lecu15MsgA: 8 LECU15
 SG_ M15_Tem_Min_Valid : 63|1@1+ (1,0) [0|0] ""  BMU
 SG_ M15_Tem_Min : 48|11@1+ (0.1,-40) [0|0] "℃"  BMU
 SG_ M15_Tem_Max_Valid : 47|1@1+ (1,0) [0|0] ""  BMU
 SG_ M15_Tem_Max : 32|11@1+ (0.1,-40) [0|0] "℃"  BMU
 SG_ M15_CellVoltageMin_Valid : 31|1@1+ (1,0) [0|0] ""  BMU
 SG_ M15_CellVoltageMin : 16|15@1- (0.001,0) [0|0] "V"  BMU
 SG_ M15_CellVoltageMax_Valid : 15|1@1+ (1,0) [0|0] ""  BMU
 SG_ M15_CellVoltageMax : 0|15@1- (0.001,0) [0|0] "V"  BMU

BO_ 489 Lecu14MsgH: 8 Vector__XXX
 SG_ Lecu_Version3 : 63|8@0+ (1,0) [0|0] "" Vector__XXX
 SG_ Lecu_Version2 : 55|8@0+ (1,0) [0|0] "" Vector__XXX
 SG_ Lecu_Version1 : 47|8@0+ (1,0) [0|0] "" Vector__XXX
 SG_ Lecu_Version0 : 39|8@0+ (1,0) [0|0] "" Vector__XXX
 SG_ M14_CellBalance24 : 23|1@1+ (1,0) [0|0] "" Vector__XXX
 SG_ M14_CellBalance23 : 22|1@1+ (1,0) [0|0] "" Vector__XXX
 SG_ M14_CellBalance22 : 21|1@1+ (1,0) [0|0] "" Vector__XXX
 SG_ M14_CellBalance21 : 20|1@1+ (1,0) [0|0] "" Vector__XXX
 SG_ M14_CellBalance20 : 19|1@1+ (1,0) [0|0] "" Vector__XXX
 SG_ M14_CellBalance19 : 18|1@1+ (1,0) [0|0] "" Vector__XXX
 SG_ M14_CellBalance18 : 17|1@1+ (1,0) [0|0] "" Vector__XXX
 SG_ M14_CellBalance17 : 16|1@1+ (1,0) [0|0] "" Vector__XXX
 SG_ M14_CellBalance16 : 15|1@1+ (1,0) [0|0] "" Vector__XXX
 SG_ M14_CellBalance15 : 14|1@1+ (1,0) [0|0] "" Vector__XXX
 SG_ M14_CellBalance14 : 13|1@1+ (1,0) [0|0] "" Vector__XXX
 SG_ M14_CellBalance13 : 12|1@1+ (1,0) [0|0] "" Vector__XXX
 SG_ M14_CellBalance9 : 8|1@1+ (1,0) [0|0] "" Vector__XXX
 SG_ M14_CellBalance8 : 7|1@1+ (1,0) [0|0] "" Vector__XXX
 SG_ M14_CellBalance7 : 6|1@1+ (1,0) [0|0] "" Vector__XXX
 SG_ M14_CellBalance6 : 5|1@1+ (1,0) [0|0] "" Vector__XXX
 SG_ M14_CellBalance5 : 4|1@1+ (1,0) [0|0] "" Vector__XXX
 SG_ M14_CellBalance4 : 3|1@1+ (1,0) [0|0] "" Vector__XXX
 SG_ M14_CellBalance3 : 2|1@1+ (1,0) [0|0] "" Vector__XXX
 SG_ M14_CellBalance2 : 1|1@1+ (1,0) [0|0] "" Vector__XXX
 SG_ M14_CellBalance12 : 11|1@1+ (1,0) [0|0] "" Vector__XXX
 SG_ M14_CellBalance11 : 10|1@1+ (1,0) [0|0] "" Vector__XXX
 SG_ M14_CellBalance10 : 9|1@1+ (1,0) [0|0] "" Vector__XXX
 SG_ M14_CellBalance1 : 0|1@1+ (1,0) [0|0] "" Vector__XXX

BO_ 488 Lecu14MsgG: 8 Vector__XXX
 SG_ M14_Tem8_Valid : 15|1@1+ (1,0) [0|0] "" Vector__XXX
 SG_ M14_Tem8 : 48|11@1+ (0.1,-40) [0|0] "" Vector__XXX
 SG_ M14_Tem7_Valid : 31|1@1+ (1,0) [0|0] "" Vector__XXX
 SG_ M14_Tem7 : 32|11@1+ (0.1,-40) [0|0] "" Vector__XXX
 SG_ M14_Tem6_Valid : 47|1@1+ (1,0) [0|0] "" Vector__XXX
 SG_ M14_Tem6 : 16|11@1+ (0.1,-40) [0|0] "" Vector__XXX
 SG_ M14_Tem5_Valid : 63|1@1+ (1,0) [0|0] "" Vector__XXX
 SG_ M14_Tem5 : 0|11@1+ (0.1,-40) [0|0] "" Vector__XXX

BO_ 487 Lecu14MsgF: 8 Vector__XXX
 SG_ M14_Tem4_Valid : 63|1@1+ (1,0) [0|0] "" Vector__XXX
 SG_ M14_Tem4 : 48|11@1+ (0.1,-40) [0|0] "" Vector__XXX
 SG_ M14_Tem3_Valid : 47|1@1+ (1,0) [0|0] "" Vector__XXX
 SG_ M14_Tem3 : 32|11@1+ (0.1,-40) [0|0] "" Vector__XXX
 SG_ M14_Tem2_Valid : 31|1@1+ (1,0) [0|0] "" Vector__XXX
 SG_ M14_Tem2 : 16|11@1+ (0.1,-40) [0|0] "" Vector__XXX
 SG_ M14_Tem1_Valid : 15|1@1+ (1,0) [0|0] "" Vector__XXX
 SG_ M14_Tem1 : 0|11@1+ (0.1,-40) [0|0] "" Vector__XXX

BO_ 486 Lecu14MsgE: 8 Vector__XXX
 SG_ M14_CellVoltage12_Valid : 63|1@1+ (1,0) [0|0] "" Vector__XXX
 SG_ M14_CellVoltage12 : 48|15@1- (0.001,0) [0|0] "" Vector__XXX
 SG_ M14_CellVoltage11_Valid : 47|1@1+ (1,0) [0|0] "" Vector__XXX
 SG_ M14_CellVoltage11 : 32|15@1- (0.001,0) [0|0] "" Vector__XXX
 SG_ M14_CellVoltage10_Valid : 31|1@1+ (1,0) [0|0] "" Vector__XXX
 SG_ M14_CellVoltage10 : 16|15@1- (0.001,0) [0|0] "" Vector__XXX
 SG_ M14_CellVoltage9_Valid : 15|1@1+ (1,0) [0|0] "" Vector__XXX
 SG_ M14_CellVoltage9 : 0|15@1- (0.001,0) [0|0] "" Vector__XXX

BO_ 485 Lecu14MsgD: 8 Vector__XXX
 SG_ M14_CellVoltage8_Valid : 63|1@1+ (1,0) [0|0] "" Vector__XXX
 SG_ M14_CellVoltage8 : 48|15@1- (0.001,0) [0|0] "" Vector__XXX
 SG_ M14_CellVoltage7_Valid : 47|1@1+ (1,0) [0|0] "" Vector__XXX
 SG_ M14_CellVoltage7 : 32|15@1- (0.001,0) [0|0] "" Vector__XXX
 SG_ M14_CellVoltage6_Valid : 31|1@1+ (1,0) [0|0] "" Vector__XXX
 SG_ M14_CellVoltage6 : 16|15@1- (0.001,0) [0|0] "" Vector__XXX
 SG_ M14_CellVoltage5_Valid : 15|1@1+ (1,0) [0|0] "" Vector__XXX
 SG_ M14_CellVoltage5 : 0|15@1- (0.001,0) [0|0] "" Vector__XXX

BO_ 484 Lecu14MsgC: 8 Vector__XXX
 SG_ M14_CellVoltage4_Valid : 63|1@1+ (1,0) [0|0] "" Vector__XXX
 SG_ M14_CellVoltage4 : 48|15@1- (0.001,0) [0|0] "" Vector__XXX
 SG_ M14_CellVoltage3_Valid : 47|1@1+ (1,0) [0|0] "" Vector__XXX
 SG_ M14_CellVoltage3 : 32|15@1- (0.001,0) [0|0] "" Vector__XXX
 SG_ M14_CellVoltage2_Valid : 31|1@1+ (1,0) [0|0] "" Vector__XXX
 SG_ M14_CellVoltage2 : 16|15@1- (0.001,0) [0|0] "" Vector__XXX
 SG_ M14_CellVoltage1_Valid : 15|1@1+ (1,0) [0|0] "" Vector__XXX
 SG_ M14_CellVoltage1 : 0|15@1- (0.001,0) [0|0] "" Vector__XXX

BO_ 480 Lecu14MsgA: 8 LECU14
 SG_ M14_Tem_Min_Valid : 63|1@1+ (1,0) [0|0] ""  BMU
 SG_ M14_Tem_Min : 48|11@1+ (0.1,-40) [0|0] "℃"  BMU
 SG_ M14_Tem_Max_Valid : 47|1@1+ (1,0) [0|0] ""  BMU
 SG_ M14_Tem_Max : 32|11@1+ (0.1,-40) [0|0] "℃"  BMU
 SG_ M14_CellVoltageMin_Valid : 31|1@1+ (1,0) [0|0] ""  BMU
 SG_ M14_CellVoltageMin : 16|15@1- (0.001,0) [0|0] "V"  BMU
 SG_ M14_CellVoltageMax_Valid : 15|1@1+ (1,0) [0|0] ""  BMU
 SG_ M14_CellVoltageMax : 0|15@1- (0.001,0) [0|0] "V"  BMU

BO_ 361 Lecu6MsgH: 8 Vector__XXX
 SG_ Lecu_Version3 : 63|8@0+ (1,0) [0|0] "" Vector__XXX
 SG_ Lecu_Version2 : 55|8@0+ (1,0) [0|0] "" Vector__XXX
 SG_ Lecu_Version1 : 47|8@0+ (1,0) [0|0] "" Vector__XXX
 SG_ Lecu_Version0 : 39|8@0+ (1,0) [0|0] "" Vector__XXX
 SG_ M6_CellBalance24 : 23|1@1+ (1,0) [0|0] "" Vector__XXX
 SG_ M6_CellBalance23 : 22|1@1+ (1,0) [0|0] "" Vector__XXX
 SG_ M6_CellBalance22 : 21|1@1+ (1,0) [0|0] "" Vector__XXX
 SG_ M6_CellBalance21 : 20|1@1+ (1,0) [0|0] "" Vector__XXX
 SG_ M6_CellBalance20 : 19|1@1+ (1,0) [0|0] "" Vector__XXX
 SG_ M6_CellBalance19 : 18|1@1+ (1,0) [0|0] "" Vector__XXX
 SG_ M6_CellBalance18 : 17|1@1+ (1,0) [0|0] "" Vector__XXX
 SG_ M6_CellBalance17 : 16|1@1+ (1,0) [0|0] "" Vector__XXX
 SG_ M6_CellBalance16 : 15|1@1+ (1,0) [0|0] "" Vector__XXX
 SG_ M6_CellBalance15 : 14|1@1+ (1,0) [0|0] "" Vector__XXX
 SG_ M6_CellBalance14 : 13|1@1+ (1,0) [0|0] "" Vector__XXX
 SG_ M6_CellBalance13 : 12|1@1+ (1,0) [0|0] "" Vector__XXX
 SG_ M6_CellBalance9 : 8|1@1+ (1,0) [0|0] "" Vector__XXX
 SG_ M6_CellBalance8 : 7|1@1+ (1,0) [0|0] "" Vector__XXX
 SG_ M6_CellBalance7 : 6|1@1+ (1,0) [0|0] "" Vector__XXX
 SG_ M6_CellBalance6 : 5|1@1+ (1,0) [0|0] "" Vector__XXX
 SG_ M6_CellBalance5 : 4|1@1+ (1,0) [0|0] "" Vector__XXX
 SG_ M6_CellBalance4 : 3|1@1+ (1,0) [0|0] "" Vector__XXX
 SG_ M6_CellBalance3 : 2|1@1+ (1,0) [0|0] "" Vector__XXX
 SG_ M6_CellBalance2 : 1|1@1+ (1,0) [0|0] "" Vector__XXX
 SG_ M6_CellBalance12 : 11|1@1+ (1,0) [0|0] "" Vector__XXX
 SG_ M6_CellBalance11 : 10|1@1+ (1,0) [0|0] "" Vector__XXX
 SG_ M6_CellBalance10 : 9|1@1+ (1,0) [0|0] "" Vector__XXX
 SG_ M6_CellBalance1 : 0|1@1+ (1,0) [0|0] "" Vector__XXX

BO_ 473 Lecu13MsgH: 8 Vector__XXX
 SG_ Lecu_Version3 : 63|8@0+ (1,0) [0|0] "" Vector__XXX
 SG_ Lecu_Version2 : 55|8@0+ (1,0) [0|0] "" Vector__XXX
 SG_ Lecu_Version1 : 47|8@0+ (1,0) [0|0] "" Vector__XXX
 SG_ Lecu_Version0 : 39|8@0+ (1,0) [0|0] "" Vector__XXX
 SG_ M13_CellBalance24 : 23|1@1+ (1,0) [0|0] "" Vector__XXX
 SG_ M13_CellBalance23 : 22|1@1+ (1,0) [0|0] "" Vector__XXX
 SG_ M13_CellBalance22 : 21|1@1+ (1,0) [0|0] "" Vector__XXX
 SG_ M13_CellBalance21 : 20|1@1+ (1,0) [0|0] "" Vector__XXX
 SG_ M13_CellBalance20 : 19|1@1+ (1,0) [0|0] "" Vector__XXX
 SG_ M13_CellBalance19 : 18|1@1+ (1,0) [0|0] "" Vector__XXX
 SG_ M13_CellBalance18 : 17|1@1+ (1,0) [0|0] "" Vector__XXX
 SG_ M13_CellBalance17 : 16|1@1+ (1,0) [0|0] "" Vector__XXX
 SG_ M13_CellBalance16 : 15|1@1+ (1,0) [0|0] "" Vector__XXX
 SG_ M13_CellBalance15 : 14|1@1+ (1,0) [0|0] "" Vector__XXX
 SG_ M13_CellBalance14 : 13|1@1+ (1,0) [0|0] "" Vector__XXX
 SG_ M13_CellBalance13 : 12|1@1+ (1,0) [0|0] "" Vector__XXX
 SG_ M13_CellBalance9 : 8|1@1+ (1,0) [0|0] "" Vector__XXX
 SG_ M13_CellBalance8 : 7|1@1+ (1,0) [0|0] "" Vector__XXX
 SG_ M13_CellBalance7 : 6|1@1+ (1,0) [0|0] "" Vector__XXX
 SG_ M13_CellBalance6 : 5|1@1+ (1,0) [0|0] "" Vector__XXX
 SG_ M13_CellBalance5 : 4|1@1+ (1,0) [0|0] "" Vector__XXX
 SG_ M13_CellBalance4 : 3|1@1+ (1,0) [0|0] "" Vector__XXX
 SG_ M13_CellBalance3 : 2|1@1+ (1,0) [0|0] "" Vector__XXX
 SG_ M13_CellBalance2 : 1|1@1+ (1,0) [0|0] "" Vector__XXX
 SG_ M13_CellBalance12 : 11|1@1+ (1,0) [0|0] "" Vector__XXX
 SG_ M13_CellBalance11 : 10|1@1+ (1,0) [0|0] "" Vector__XXX
 SG_ M13_CellBalance10 : 9|1@1+ (1,0) [0|0] "" Vector__XXX
 SG_ M13_CellBalance1 : 0|1@1+ (1,0) [0|0] "" Vector__XXX

BO_ 472 Lecu13MsgG: 8 Vector__XXX
 SG_ M13_Tem8_Valid : 63|1@1+ (1,0) [0|0] "" Vector__XXX
 SG_ M13_Tem8 : 48|11@1+ (0.1,-40) [0|0] "" Vector__XXX
 SG_ M13_Tem7_Valid : 47|1@1+ (1,0) [0|0] "" Vector__XXX
 SG_ M13_Tem7 : 32|11@1+ (0.1,-40) [0|0] "" Vector__XXX
 SG_ M13_Tem6_Valid : 31|1@1+ (1,0) [0|0] "" Vector__XXX
 SG_ M13_Tem6 : 16|11@1+ (0.1,-40) [0|0] "" Vector__XXX
 SG_ M13_Tem5_Valid : 15|1@1+ (1,0) [0|0] "" Vector__XXX
 SG_ M13_Tem5 : 0|11@1+ (0.1,-40) [0|0] "" Vector__XXX

BO_ 471 Lecu13MsgF: 8 Vector__XXX
 SG_ M13_Tem4_Valid : 63|1@1+ (1,0) [0|0] "" Vector__XXX
 SG_ M13_Tem4 : 48|11@1+ (0.1,-40) [0|0] "" Vector__XXX
 SG_ M13_Tem3_Valid : 47|1@1+ (1,0) [0|0] "" Vector__XXX
 SG_ M13_Tem3 : 32|11@1+ (0.1,-40) [0|0] "" Vector__XXX
 SG_ M13_Tem2_Valid : 31|1@1+ (1,0) [0|0] "" Vector__XXX
 SG_ M13_Tem2 : 16|11@1+ (0.1,-40) [0|0] "" Vector__XXX
 SG_ M13_Tem1_Valid : 15|1@1+ (1,0) [0|0] "" Vector__XXX
 SG_ M13_Tem1 : 0|11@1+ (0.1,-40) [0|0] "" Vector__XXX

BO_ 470 Lecu13MsgE: 8 Vector__XXX
 SG_ M13_CellVoltage12_Valid : 63|1@1+ (1,0) [0|0] "" Vector__XXX
 SG_ M13_CellVoltage12 : 48|15@1- (0.001,0) [0|0] "" Vector__XXX
 SG_ M13_CellVoltage11_Valid : 47|1@1+ (1,0) [0|0] "" Vector__XXX
 SG_ M13_CellVoltage11 : 32|15@1- (0.001,0) [0|0] "" Vector__XXX
 SG_ M13_CellVoltage10_Valid : 31|1@1+ (1,0) [0|0] "" Vector__XXX
 SG_ M13_CellVoltage10 : 16|15@1- (0.001,0) [0|0] "" Vector__XXX
 SG_ M13_CellVoltage9_Valid : 15|1@1+ (1,0) [0|0] "" Vector__XXX
 SG_ M13_CellVoltage9 : 0|15@1- (0.001,0) [0|0] "" Vector__XXX

BO_ 469 Lecu13MsgD: 8 Vector__XXX
 SG_ M13_CellVoltage8_Valid : 63|1@1+ (1,0) [0|0] "" Vector__XXX
 SG_ M13_CellVoltage8 : 48|15@1- (0.001,0) [0|0] "" Vector__XXX
 SG_ M13_CellVoltage7_Valid : 47|1@1+ (1,0) [0|0] "" Vector__XXX
 SG_ M13_CellVoltage7 : 32|15@1- (0.001,0) [0|0] "" Vector__XXX
 SG_ M13_CellVoltage6_Valid : 31|1@1+ (1,0) [0|0] "" Vector__XXX
 SG_ M13_CellVoltage6 : 16|15@1- (0.001,0) [0|0] "" Vector__XXX
 SG_ M13_CellVoltage5_Valid : 15|1@1+ (1,0) [0|0] "" Vector__XXX
 SG_ M13_CellVoltage5 : 0|15@1- (0.001,0) [0|0] "" Vector__XXX

BO_ 468 Lecu13MsgC: 8 Vector__XXX
 SG_ M13_CellVoltage4_Valid : 63|1@1+ (1,0) [0|0] "" Vector__XXX
 SG_ M13_CellVoltage4 : 48|15@1- (0.001,0) [0|0] "" Vector__XXX
 SG_ M13_CellVoltage3_Valid : 47|1@1+ (1,0) [0|0] "" Vector__XXX
 SG_ M13_CellVoltage3 : 32|15@1- (0.001,0) [0|0] "" Vector__XXX
 SG_ M13_CellVoltage2_Valid : 31|1@1+ (1,0) [0|0] "" Vector__XXX
 SG_ M13_CellVoltage2 : 16|15@1- (0.001,0) [0|0] "" Vector__XXX
 SG_ M13_CellVoltage1_Valid : 15|1@1+ (1,0) [0|0] "" Vector__XXX
 SG_ M13_CellVoltage1 : 0|15@1- (0.001,0) [0|0] "" Vector__XXX

BO_ 464 Lecu13MsgA: 8 LECU13
 SG_ M13_Tem_Min_Valid : 63|1@1+ (1,0) [0|0] ""  BMU
 SG_ M13_Tem_Min : 48|11@1+ (0.1,-40) [0|0] "℃"  BMU
 SG_ M13_Tem_Max_Valid : 47|1@1+ (1,0) [0|0] ""  BMU
 SG_ M13_Tem_Max : 32|11@1+ (0.1,-40) [0|0] "℃"  BMU
 SG_ M13_CellVoltageMin_Valid : 31|1@1+ (1,0) [0|0] ""  BMU
 SG_ M13_CellVoltageMin : 16|15@1- (0.001,0) [0|0] "V"  BMU
 SG_ M13_CellVoltageMax_Valid : 15|1@1+ (1,0) [0|0] ""  BMU
 SG_ M13_CellVoltageMax : 0|15@1- (0.001,0) [0|0] "V"  BMU

BO_ 457 Lecu12MsgH: 8 Vector__XXX
 SG_ Lecu_Version3 : 63|8@0+ (1,0) [0|0] "" Vector__XXX
 SG_ Lecu_Version2 : 55|8@0+ (1,0) [0|0] "" Vector__XXX
 SG_ Lecu_Version1 : 47|8@0+ (1,0) [0|0] "" Vector__XXX
 SG_ Lecu_Version0 : 39|8@0+ (1,0) [0|0] "" Vector__XXX
 SG_ M12_CellBalance24 : 23|1@1+ (1,0) [0|0] "" Vector__XXX
 SG_ M12_CellBalance23 : 22|1@1+ (1,0) [0|0] "" Vector__XXX
 SG_ M12_CellBalance22 : 21|1@1+ (1,0) [0|0] "" Vector__XXX
 SG_ M12_CellBalance21 : 20|1@1+ (1,0) [0|0] "" Vector__XXX
 SG_ M12_CellBalance20 : 19|1@1+ (1,0) [0|0] "" Vector__XXX
 SG_ M12_CellBalance19 : 18|1@1+ (1,0) [0|0] "" Vector__XXX
 SG_ M12_CellBalance18 : 17|1@1+ (1,0) [0|0] "" Vector__XXX
 SG_ M12_CellBalance17 : 16|1@1+ (1,0) [0|0] "" Vector__XXX
 SG_ M12_CellBalance16 : 15|1@1+ (1,0) [0|0] "" Vector__XXX
 SG_ M12_CellBalance15 : 14|1@1+ (1,0) [0|0] "" Vector__XXX
 SG_ M12_CellBalance14 : 13|1@1+ (1,0) [0|0] "" Vector__XXX
 SG_ M12_CellBalance13 : 12|1@1+ (1,0) [0|0] "" Vector__XXX
 SG_ M12_CellBalance9 : 8|1@1+ (1,0) [0|0] "" Vector__XXX
 SG_ M12_CellBalance8 : 7|1@1+ (1,0) [0|0] "" Vector__XXX
 SG_ M12_CellBalance7 : 6|1@1+ (1,0) [0|0] "" Vector__XXX
 SG_ M12_CellBalance6 : 5|1@1+ (1,0) [0|0] "" Vector__XXX
 SG_ M12_CellBalance5 : 4|1@1+ (1,0) [0|0] "" Vector__XXX
 SG_ M12_CellBalance4 : 3|1@1+ (1,0) [0|0] "" Vector__XXX
 SG_ M12_CellBalance3 : 2|1@1+ (1,0) [0|0] "" Vector__XXX
 SG_ M12_CellBalance2 : 1|1@1+ (1,0) [0|0] "" Vector__XXX
 SG_ M12_CellBalance12 : 11|1@1+ (1,0) [0|0] "" Vector__XXX
 SG_ M12_CellBalance11 : 10|1@1+ (1,0) [0|0] "" Vector__XXX
 SG_ M12_CellBalance10 : 9|1@1+ (1,0) [0|0] "" Vector__XXX
 SG_ M12_CellBalance1 : 0|1@1+ (1,0) [0|0] "" Vector__XXX

BO_ 456 Lecu12MsgG: 8 Vector__XXX
 SG_ M12_Tem8_Valid : 63|1@1+ (1,0) [0|0] "" Vector__XXX
 SG_ M12_Tem8 : 48|11@1+ (0.1,-40) [0|0] "" Vector__XXX
 SG_ M12_Tem7_Valid : 47|1@1+ (1,0) [0|0] "" Vector__XXX
 SG_ M12_Tem7 : 32|11@1+ (0.1,-40) [0|0] "" Vector__XXX
 SG_ M12_Tem6_Valid : 31|1@1+ (1,0) [0|0] "" Vector__XXX
 SG_ M12_Tem6 : 16|11@1+ (0.1,-40) [0|0] "" Vector__XXX
 SG_ M12_Tem5_Valid : 15|1@1+ (1,0) [0|0] "" Vector__XXX
 SG_ M12_Tem5 : 0|11@1+ (0.1,-40) [0|0] "" Vector__XXX

BO_ 455 Lecu12MsgF: 8 Vector__XXX
 SG_ M12_Tem4_Valid : 63|1@1+ (1,0) [0|0] "" Vector__XXX
 SG_ M12_Tem4 : 48|11@1+ (0.1,-40) [0|0] "" Vector__XXX
 SG_ M12_Tem3_Valid : 47|1@1+ (1,0) [0|0] "" Vector__XXX
 SG_ M12_Tem3 : 32|11@1+ (0.1,-40) [0|0] "" Vector__XXX
 SG_ M12_Tem2_Valid : 31|1@1+ (1,0) [0|0] "" Vector__XXX
 SG_ M12_Tem2 : 16|11@1+ (0.1,-40) [0|0] "" Vector__XXX
 SG_ M12_Tem1_Valid : 15|1@1+ (1,0) [0|0] "" Vector__XXX
 SG_ M12_Tem1 : 0|11@1+ (0.1,-40) [0|0] "" Vector__XXX

BO_ 454 Lecu12MsgE: 8 Vector__XXX
 SG_ M12_CellVoltage12_Valid : 63|1@1+ (1,0) [0|0] "" Vector__XXX
 SG_ M12_CellVoltage12 : 48|15@1- (0.001,0) [0|0] "" Vector__XXX
 SG_ M12_CellVoltage11_Valid : 47|1@1+ (1,0) [0|0] "" Vector__XXX
 SG_ M12_CellVoltage11 : 32|15@1- (0.001,0) [0|0] "" Vector__XXX
 SG_ M12_CellVoltage10_Valid : 31|1@1+ (1,0) [0|0] "" Vector__XXX
 SG_ M12_CellVoltage10 : 16|15@1- (0.001,0) [0|0] "" Vector__XXX
 SG_ M12_CellVoltage9_Valid : 15|1@1+ (1,0) [0|0] "" Vector__XXX
 SG_ M12_CellVoltage9 : 0|15@1- (0.001,0) [0|0] "" Vector__XXX

BO_ 453 Lecu12MsgD: 8 Vector__XXX
 SG_ M12_CellVoltage8_Valid : 63|1@1+ (1,0) [0|0] "" Vector__XXX
 SG_ M12_CellVoltage8 : 48|15@1- (0.001,0) [0|0] "" Vector__XXX
 SG_ M12_CellVoltage7_Valid : 47|1@1+ (1,0) [0|0] "" Vector__XXX
 SG_ M12_CellVoltage7 : 32|15@1- (0.001,0) [0|0] "" Vector__XXX
 SG_ M12_CellVoltage6_Valid : 31|1@1+ (1,0) [0|0] "" Vector__XXX
 SG_ M12_CellVoltage6 : 16|15@1- (0.001,0) [0|0] "" Vector__XXX
 SG_ M12_CellVoltage5_Valid : 15|1@1+ (1,0) [0|0] "" Vector__XXX
 SG_ M12_CellVoltage5 : 0|15@1- (0.001,0) [0|0] "" Vector__XXX

BO_ 452 Lecu12MsgC: 8 Vector__XXX
 SG_ M12_CellVoltage4_Valid : 63|1@1+ (1,0) [0|0] "" Vector__XXX
 SG_ M12_CellVoltage4 : 48|15@1- (0.001,0) [0|0] "" Vector__XXX
 SG_ M12_CellVoltage3_Valid : 47|1@1+ (1,0) [0|0] "" Vector__XXX
 SG_ M12_CellVoltage3 : 32|15@1- (0.001,0) [0|0] "" Vector__XXX
 SG_ M12_CellVoltage2_Valid : 31|1@1+ (1,0) [0|0] "" Vector__XXX
 SG_ M12_CellVoltage2 : 16|15@1- (0.001,0) [0|0] "" Vector__XXX
 SG_ M12_CellVoltage1_Valid : 15|1@1+ (1,0) [0|0] "" Vector__XXX
 SG_ M12_CellVoltage1 : 0|15@1- (0.001,0) [0|0] "" Vector__XXX

BO_ 441 Lecu11MsgH: 8 Vector__XXX
 SG_ Lecu_Version3 : 63|8@0+ (1,0) [0|0] "" Vector__XXX
 SG_ Lecu_Version2 : 55|8@0+ (1,0) [0|0] "" Vector__XXX
 SG_ Lecu_Version1 : 47|8@0+ (1,0) [0|0] "" Vector__XXX
 SG_ Lecu_Version0 : 39|8@0+ (1,0) [0|0] "" Vector__XXX
 SG_ M11_CellBalance24 : 23|1@1+ (1,0) [0|0] "" Vector__XXX
 SG_ M11_CellBalance23 : 22|1@1+ (1,0) [0|0] "" Vector__XXX
 SG_ M11_CellBalance22 : 21|1@1+ (1,0) [0|0] "" Vector__XXX
 SG_ M11_CellBalance21 : 20|1@1+ (1,0) [0|0] "" Vector__XXX
 SG_ M11_CellBalance20 : 19|1@1+ (1,0) [0|0] "" Vector__XXX
 SG_ M11_CellBalance19 : 18|1@1+ (1,0) [0|0] "" Vector__XXX
 SG_ M11_CellBalance18 : 17|1@1+ (1,0) [0|0] "" Vector__XXX
 SG_ M11_CellBalance17 : 16|1@1+ (1,0) [0|0] "" Vector__XXX
 SG_ M11_CellBalance16 : 15|1@1+ (1,0) [0|0] "" Vector__XXX
 SG_ M11_CellBalance15 : 14|1@1+ (1,0) [0|0] "" Vector__XXX
 SG_ M11_CellBalance14 : 13|1@1+ (1,0) [0|0] "" Vector__XXX
 SG_ M11_CellBalance13 : 12|1@1+ (1,0) [0|0] "" Vector__XXX
 SG_ M11_CellBalance9 : 8|1@1+ (1,0) [0|0] "" Vector__XXX
 SG_ M11_CellBalance8 : 7|1@1+ (1,0) [0|0] "" Vector__XXX
 SG_ M11_CellBalance7 : 6|1@1+ (1,0) [0|0] "" Vector__XXX
 SG_ M11_CellBalance6 : 5|1@1+ (1,0) [0|0] "" Vector__XXX
 SG_ M11_CellBalance5 : 4|1@1+ (1,0) [0|0] "" Vector__XXX
 SG_ M11_CellBalance4 : 3|1@1+ (1,0) [0|0] "" Vector__XXX
 SG_ M11_CellBalance3 : 2|1@1+ (1,0) [0|0] "" Vector__XXX
 SG_ M11_CellBalance2 : 1|1@1+ (1,0) [0|0] "" Vector__XXX
 SG_ M11_CellBalance12 : 11|1@1+ (1,0) [0|0] "" Vector__XXX
 SG_ M11_CellBalance11 : 10|1@1+ (1,0) [0|0] "" Vector__XXX
 SG_ M11_CellBalance10 : 9|1@1+ (1,0) [0|0] "" Vector__XXX
 SG_ M11_CellBalance1 : 0|1@1+ (1,0) [0|0] "" Vector__XXX

BO_ 440 Lecu11MsgG: 8 Vector__XXX
 SG_ M11_Tem8_Valid : 63|1@1+ (1,0) [0|0] "" Vector__XXX
 SG_ M11_Tem8 : 48|11@1+ (0.1,-40) [0|0] "" Vector__XXX
 SG_ M11_Tem7_Valid : 47|1@1+ (1,0) [0|0] "" Vector__XXX
 SG_ M11_Tem7 : 32|11@1+ (0.1,-40) [0|0] "" Vector__XXX
 SG_ M11_Tem6_Valid : 31|1@1+ (1,0) [0|0] "" Vector__XXX
 SG_ M11_Tem6 : 16|11@1+ (0.1,-40) [0|0] "" Vector__XXX
 SG_ M11_Tem5_Valid : 15|1@1+ (1,0) [0|0] "" Vector__XXX
 SG_ M11_Tem5 : 0|11@1+ (0.1,-40) [0|0] "" Vector__XXX

BO_ 439 Lecu11MsgF: 8 Vector__XXX
 SG_ M11_Tem4_Valid : 63|1@1+ (1,0) [0|0] "" Vector__XXX
 SG_ M11_Tem4 : 48|11@1+ (0.1,-40) [0|0] "" Vector__XXX
 SG_ M11_Tem3_Valid : 47|1@1+ (1,0) [0|0] "" Vector__XXX
 SG_ M11_Tem3 : 32|11@1+ (0.1,-40) [0|0] "" Vector__XXX
 SG_ M11_Tem2_Valid : 31|1@1+ (1,0) [0|0] "" Vector__XXX
 SG_ M11_Tem2 : 16|11@1+ (0.1,-40) [0|0] "" Vector__XXX
 SG_ M11_Tem1_Valid : 15|1@1+ (1,0) [0|0] "" Vector__XXX
 SG_ M11_Tem1 : 0|11@1+ (0.1,-40) [0|0] "" Vector__XXX

BO_ 438 Lecu11MsgE: 8 Vector__XXX
 SG_ M11_CellVoltage12_Valid : 63|1@1+ (1,0) [0|0] "" Vector__XXX
 SG_ M11_CellVoltage12 : 48|15@1- (0.001,0) [0|0] "" Vector__XXX
 SG_ M11_CellVoltage11_Valid : 47|1@1+ (1,0) [0|0] "" Vector__XXX
 SG_ M11_CellVoltage11 : 32|15@1- (0.001,0) [0|0] "" Vector__XXX
 SG_ M11_CellVoltage10_Valid : 31|1@1+ (1,0) [0|0] "" Vector__XXX
 SG_ M11_CellVoltage10 : 16|15@1- (0.001,0) [0|0] "" Vector__XXX
 SG_ M11_CellVoltage9_Valid : 15|1@1+ (1,0) [0|0] "" Vector__XXX
 SG_ M11_CellVoltage9 : 0|15@1- (0.001,0) [0|0] "" Vector__XXX

BO_ 437 Lecu11MsgD: 8 Vector__XXX
 SG_ M11_CellVoltage8_Valid : 63|1@1+ (1,0) [0|0] "" Vector__XXX
 SG_ M11_CellVoltage8 : 48|15@1- (0.001,0) [0|0] "" Vector__XXX
 SG_ M11_CellVoltage7_Valid : 47|1@1+ (1,0) [0|0] "" Vector__XXX
 SG_ M11_CellVoltage7 : 32|15@1- (0.001,0) [0|0] "" Vector__XXX
 SG_ M11_CellVoltage6_Valid : 31|1@1+ (1,0) [0|0] "" Vector__XXX
 SG_ M11_CellVoltage6 : 16|15@1- (0.001,0) [0|0] "" Vector__XXX
 SG_ M11_CellVoltage5_Valid : 15|1@1+ (1,0) [0|0] "" Vector__XXX
 SG_ M11_CellVoltage5 : 0|15@1- (0.001,0) [0|0] "" Vector__XXX

BO_ 436 Lecu11MsgC: 8 Vector__XXX
 SG_ M11_CellVoltage4_Valid : 63|1@1+ (1,0) [0|0] "" Vector__XXX
 SG_ M11_CellVoltage4 : 48|15@1- (0.001,0) [0|0] "" Vector__XXX
 SG_ M11_CellVoltage3_Valid : 47|1@1+ (1,0) [0|0] "" Vector__XXX
 SG_ M11_CellVoltage3 : 32|15@1- (0.001,0) [0|0] "" Vector__XXX
 SG_ M11_CellVoltage2_Valid : 31|1@1+ (1,0) [0|0] "" Vector__XXX
 SG_ M11_CellVoltage2 : 16|15@1- (0.001,0) [0|0] "" Vector__XXX
 SG_ M11_CellVoltage1_Valid : 15|1@1+ (1,0) [0|0] "" Vector__XXX
 SG_ M11_CellVoltage1 : 0|15@1- (0.001,0) [0|0] "" Vector__XXX

BO_ 448 Lecu12MsgA: 8 LECU12
 SG_ M12_Tem_Min_Valid : 63|1@1+ (1,0) [0|0] ""  BMU
 SG_ M12_Tem_Min : 48|11@1+ (0.1,-40) [0|0] "℃"  BMU
 SG_ M12_Tem_Max_Valid : 47|1@1+ (1,0) [0|0] ""  BMU
 SG_ M12_Tem_Max : 32|11@1+ (0.1,-40) [0|0] "℃"  BMU
 SG_ M12_CellVoltageMin_Valid : 31|1@1+ (1,0) [0|0] ""  BMU
 SG_ M12_CellVoltageMin : 16|15@1- (0.001,0) [0|0] "V"  BMU
 SG_ M12_CellVoltageMax_Valid : 15|1@1+ (1,0) [0|0] ""  BMU
 SG_ M12_CellVoltageMax : 0|15@1- (0.001,0) [0|0] "V"  BMU

BO_ 425 Lecu10MsgH: 8 Vector__XXX
 SG_ Lecu_Version3 : 63|8@0+ (1,0) [0|0] "" Vector__XXX
 SG_ Lecu_Version2 : 55|8@0+ (1,0) [0|0] "" Vector__XXX
 SG_ Lecu_Version1 : 47|8@0+ (1,0) [0|0] "" Vector__XXX
 SG_ Lecu_Version0 : 39|8@0+ (1,0) [0|0] "" Vector__XXX
 SG_ M10_CellBalance24 : 23|1@1+ (1,0) [0|0] "" Vector__XXX
 SG_ M10_CellBalance23 : 22|1@1+ (1,0) [0|0] "" Vector__XXX
 SG_ M10_CellBalance22 : 21|1@1+ (1,0) [0|0] "" Vector__XXX
 SG_ M10_CellBalance21 : 20|1@1+ (1,0) [0|0] "" Vector__XXX
 SG_ M10_CellBalance20 : 19|1@1+ (1,0) [0|0] "" Vector__XXX
 SG_ M10_CellBalance19 : 18|1@1+ (1,0) [0|0] "" Vector__XXX
 SG_ M10_CellBalance18 : 17|1@1+ (1,0) [0|0] "" Vector__XXX
 SG_ M10_CellBalance17 : 16|1@1+ (1,0) [0|0] "" Vector__XXX
 SG_ M10_CellBalance16 : 15|1@1+ (1,0) [0|0] "" Vector__XXX
 SG_ M10_CellBalance15 : 14|1@1+ (1,0) [0|0] "" Vector__XXX
 SG_ M10_CellBalance14 : 13|1@1+ (1,0) [0|0] "" Vector__XXX
 SG_ M10_CellBalance13 : 12|1@1+ (1,0) [0|0] "" Vector__XXX
 SG_ M10_CellBalance9 : 8|1@1+ (1,0) [0|0] "" Vector__XXX
 SG_ M10_CellBalance8 : 7|1@1+ (1,0) [0|0] "" Vector__XXX
 SG_ M10_CellBalance7 : 6|1@1+ (1,0) [0|0] "" Vector__XXX
 SG_ M10_CellBalance6 : 5|1@1+ (1,0) [0|0] "" Vector__XXX
 SG_ M10_CellBalance5 : 4|1@1+ (1,0) [0|0] "" Vector__XXX
 SG_ M10_CellBalance4 : 3|1@1+ (1,0) [0|0] "" Vector__XXX
 SG_ M10_CellBalance3 : 2|1@1+ (1,0) [0|0] "" Vector__XXX
 SG_ M10_CellBalance2 : 1|1@1+ (1,0) [0|0] "" Vector__XXX
 SG_ M10_CellBalance12 : 11|1@1+ (1,0) [0|0] "" Vector__XXX
 SG_ M10_CellBalance11 : 10|1@1+ (1,0) [0|0] "" Vector__XXX
 SG_ M10_CellBalance10 : 9|1@1+ (1,0) [0|0] "" Vector__XXX
 SG_ M10_CellBalance1 : 0|1@1+ (1,0) [0|0] "" Vector__XXX

BO_ 424 Lecu10MsgG: 8 Vector__XXX
 SG_ M10_Tem8_Valid : 63|1@1+ (1,0) [0|0] "" Vector__XXX
 SG_ M10_Tem8 : 48|11@1+ (0.1,-40) [0|0] "" Vector__XXX
 SG_ M10_Tem7_Valid : 47|1@1+ (1,0) [0|0] "" Vector__XXX
 SG_ M10_Tem7 : 32|11@1+ (0.1,-40) [0|0] "" Vector__XXX
 SG_ M10_Tem6_Valid : 31|1@1+ (1,0) [0|0] "" Vector__XXX
 SG_ M10_Tem6 : 16|11@1+ (0.1,-40) [0|0] "" Vector__XXX
 SG_ M10_Tem5_Valid : 15|1@1+ (1,0) [0|0] "" Vector__XXX
 SG_ M10_Tem5 : 0|11@1+ (0.1,-40) [0|0] "" Vector__XXX

BO_ 423 Lecu10MsgF: 8 Vector__XXX
 SG_ M10_Tem4_Valid : 63|1@1+ (1,0) [0|0] "" Vector__XXX
 SG_ M10_Tem4 : 48|11@1+ (0.1,-40) [0|0] "" Vector__XXX
 SG_ M10_Tem3_Valid : 47|1@1+ (1,0) [0|0] "" Vector__XXX
 SG_ M10_Tem3 : 32|11@1+ (0.1,-40) [0|0] "" Vector__XXX
 SG_ M10_Tem2_Valid : 31|1@1+ (1,0) [0|0] "" Vector__XXX
 SG_ M10_Tem2 : 16|11@1+ (0.1,-40) [0|0] "" Vector__XXX
 SG_ M10_Tem1_Valid : 15|1@1+ (1,0) [0|0] "" Vector__XXX
 SG_ M10_Tem1 : 0|11@1+ (0.1,-40) [0|0] "" Vector__XXX

BO_ 422 Lecu10MsgE: 8 Vector__XXX
 SG_ M10_CellVoltage12_Valid : 63|1@1+ (1,0) [0|0] "" Vector__XXX
 SG_ M10_CellVoltage12 : 48|15@1- (0.001,0) [0|0] "" Vector__XXX
 SG_ M10_CellVoltage11_Valid : 47|1@1+ (1,0) [0|0] "" Vector__XXX
 SG_ M10_CellVoltage11 : 32|15@1- (0.001,0) [0|0] "" Vector__XXX
 SG_ M10_CellVoltage10_Valid : 31|1@1+ (1,0) [0|0] "" Vector__XXX
 SG_ M10_CellVoltage10 : 16|15@1- (0.001,0) [0|0] "" Vector__XXX
 SG_ M10_CellVoltage9_Valid : 15|1@1+ (1,0) [0|0] "" Vector__XXX
 SG_ M10_CellVoltage9 : 0|15@1- (0.001,0) [0|0] "" Vector__XXX

BO_ 421 Lecu10MsgD: 8 Vector__XXX
 SG_ M10_CellVoltage8_Valid : 63|1@1+ (1,0) [0|0] "" Vector__XXX
 SG_ M10_CellVoltage8 : 48|15@1- (0.001,0) [0|0] "" Vector__XXX
 SG_ M10_CellVoltage7_Valid : 47|1@1+ (1,0) [0|0] "" Vector__XXX
 SG_ M10_CellVoltage7 : 32|15@1- (0.001,0) [0|0] "" Vector__XXX
 SG_ M10_CellVoltage6_Valid : 31|1@1+ (1,0) [0|0] "" Vector__XXX
 SG_ M10_CellVoltage6 : 16|15@1- (0.001,0) [0|0] "" Vector__XXX
 SG_ M10_CellVoltage5_Valid : 15|1@1+ (1,0) [0|0] "" Vector__XXX
 SG_ M10_CellVoltage5 : 0|15@1- (0.001,0) [0|0] "" Vector__XXX

BO_ 420 Lecu10MsgC: 8 Vector__XXX
 SG_ M10_CellVoltage1 : 0|15@1- (0.001,0) [0|0] "" Vector__XXX
 SG_ M10_CellVoltage4_Valid : 63|1@1+ (1,0) [0|0] "" Vector__XXX
 SG_ M10_CellVoltage4 : 48|15@1- (0.001,0) [0|0] "" Vector__XXX
 SG_ M10_CellVoltage3_Valid : 47|1@1+ (1,0) [0|0] "" Vector__XXX
 SG_ M10_CellVoltage3 : 32|15@1- (0.001,0) [0|0] "" Vector__XXX
 SG_ M10_CellVoltage2_Valid : 31|1@1+ (1,0) [0|0] "" Vector__XXX
 SG_ M10_CellVoltage2 : 16|15@1- (0.001,0) [0|0] "" Vector__XXX
 SG_ M10_CellVoltage1_Valid : 15|1@1+ (1,0) [0|0] "" Vector__XXX

BO_ 409 Lecu9MsgH: 8 Vector__XXX
 SG_ Lecu_Version3 : 63|8@0+ (1,0) [0|0] "" Vector__XXX
 SG_ Lecu_Version2 : 55|8@0+ (1,0) [0|0] "" Vector__XXX
 SG_ Lecu_Version1 : 47|8@0+ (1,0) [0|0] "" Vector__XXX
 SG_ Lecu_Version0 : 39|8@0+ (1,0) [0|0] "" Vector__XXX
 SG_ M9_CellBalance24 : 23|1@1+ (1,0) [0|0] "" Vector__XXX
 SG_ M9_CellBalance23 : 22|1@1+ (1,0) [0|0] "" Vector__XXX
 SG_ M9_CellBalance22 : 21|1@1+ (1,0) [0|0] "" Vector__XXX
 SG_ M9_CellBalance21 : 20|1@1+ (1,0) [0|0] "" Vector__XXX
 SG_ M9_CellBalance20 : 19|1@1+ (1,0) [0|0] "" Vector__XXX
 SG_ M9_CellBalance19 : 18|1@1+ (1,0) [0|0] "" Vector__XXX
 SG_ M9_CellBalance18 : 17|1@1+ (1,0) [0|0] "" Vector__XXX
 SG_ M9_CellBalance17 : 16|1@1+ (1,0) [0|0] "" Vector__XXX
 SG_ M9_CellBalance16 : 15|1@1+ (1,0) [0|0] "" Vector__XXX
 SG_ M9_CellBalance15 : 14|1@1+ (1,0) [0|0] "" Vector__XXX
 SG_ M9_CellBalance14 : 13|1@1+ (1,0) [0|0] "" Vector__XXX
 SG_ M9_CellBalance13 : 12|1@1+ (1,0) [0|0] "" Vector__XXX
 SG_ M9_CellBalance9 : 8|1@1+ (1,0) [0|0] "" Vector__XXX
 SG_ M9_CellBalance8 : 7|1@1+ (1,0) [0|0] "" Vector__XXX
 SG_ M9_CellBalance7 : 6|1@1+ (1,0) [0|0] "" Vector__XXX
 SG_ M9_CellBalance6 : 5|1@1+ (1,0) [0|0] "" Vector__XXX
 SG_ M9_CellBalance5 : 4|1@1+ (1,0) [0|0] "" Vector__XXX
 SG_ M9_CellBalance4 : 3|1@1+ (1,0) [0|0] "" Vector__XXX
 SG_ M9_CellBalance3 : 2|1@1+ (1,0) [0|0] "" Vector__XXX
 SG_ M9_CellBalance2 : 1|1@1+ (1,0) [0|0] "" Vector__XXX
 SG_ M9_CellBalance12 : 11|1@1+ (1,0) [0|0] "" Vector__XXX
 SG_ M9_CellBalance11 : 10|1@1+ (1,0) [0|0] "" Vector__XXX
 SG_ M9_CellBalance10 : 9|1@1+ (1,0) [0|0] "" Vector__XXX
 SG_ M9_CellBalance1 : 0|1@1+ (1,0) [0|0] "" Vector__XXX

BO_ 393 Lecu8MsgH: 8 Vector__XXX
 SG_ Lecu_Version3 : 63|8@0+ (1,0) [0|0] "" Vector__XXX
 SG_ Lecu_Version2 : 55|8@0+ (1,0) [0|0] "" Vector__XXX
 SG_ Lecu_Version1 : 47|8@0+ (1,0) [0|0] "" Vector__XXX
 SG_ Lecu_Version0 : 39|8@0+ (1,0) [0|0] "" Vector__XXX
 SG_ M8_CellBalance24 : 23|1@1+ (1,0) [0|0] "" Vector__XXX
 SG_ M8_CellBalance23 : 22|1@1+ (1,0) [0|0] "" Vector__XXX
 SG_ M8_CellBalance22 : 21|1@1+ (1,0) [0|0] "" Vector__XXX
 SG_ M8_CellBalance21 : 20|1@1+ (1,0) [0|0] "" Vector__XXX
 SG_ M8_CellBalance20 : 19|1@1+ (1,0) [0|0] "" Vector__XXX
 SG_ M8_CellBalance19 : 18|1@1+ (1,0) [0|0] "" Vector__XXX
 SG_ M8_CellBalance18 : 17|1@1+ (1,0) [0|0] "" Vector__XXX
 SG_ M8_CellBalance17 : 16|1@1+ (1,0) [0|0] "" Vector__XXX
 SG_ M8_CellBalance16 : 15|1@1+ (1,0) [0|0] "" Vector__XXX
 SG_ M8_CellBalance15 : 14|1@1+ (1,0) [0|0] "" Vector__XXX
 SG_ M8_CellBalance14 : 13|1@1+ (1,0) [0|0] "" Vector__XXX
 SG_ M8_CellBalance13 : 12|1@1+ (1,0) [0|0] "" Vector__XXX
 SG_ M8_CellBalance9 : 8|1@1+ (1,0) [0|0] "" Vector__XXX
 SG_ M8_CellBalance8 : 7|1@1+ (1,0) [0|0] "" Vector__XXX
 SG_ M8_CellBalance7 : 6|1@1+ (1,0) [0|0] "" Vector__XXX
 SG_ M8_CellBalance6 : 5|1@1+ (1,0) [0|0] "" Vector__XXX
 SG_ M8_CellBalance5 : 4|1@1+ (1,0) [0|0] "" Vector__XXX
 SG_ M8_CellBalance4 : 3|1@1+ (1,0) [0|0] "" Vector__XXX
 SG_ M8_CellBalance3 : 2|1@1+ (1,0) [0|0] "" Vector__XXX
 SG_ M8_CellBalance2 : 1|1@1+ (1,0) [0|0] "" Vector__XXX
 SG_ M8_CellBalance12 : 11|1@1+ (1,0) [0|0] "" Vector__XXX
 SG_ M8_CellBalance11 : 10|1@1+ (1,0) [0|0] "" Vector__XXX
 SG_ M8_CellBalance10 : 9|1@1+ (1,0) [0|0] "" Vector__XXX
 SG_ M8_CellBalance1 : 0|1@1+ (1,0) [0|0] "" Vector__XXX

BO_ 377 Lecu7MsgH: 8 Vector__XXX
 SG_ Lecu_Version3 : 63|8@0+ (1,0) [0|0] "" Vector__XXX
 SG_ Lecu_Version2 : 55|8@0+ (1,0) [0|0] "" Vector__XXX
 SG_ Lecu_Version1 : 47|8@0+ (1,0) [0|0] "" Vector__XXX
 SG_ Lecu_Version0 : 39|8@0+ (1,0) [0|0] "" Vector__XXX
 SG_ M7_CellBalance24 : 23|1@1+ (1,0) [0|0] "" Vector__XXX
 SG_ M7_CellBalance23 : 22|1@1+ (1,0) [0|0] "" Vector__XXX
 SG_ M7_CellBalance22 : 21|1@1+ (1,0) [0|0] "" Vector__XXX
 SG_ M7_CellBalance21 : 20|1@1+ (1,0) [0|0] "" Vector__XXX
 SG_ M7_CellBalance20 : 19|1@1+ (1,0) [0|0] "" Vector__XXX
 SG_ M7_CellBalance19 : 18|1@1+ (1,0) [0|0] "" Vector__XXX
 SG_ M7_CellBalance18 : 17|1@1+ (1,0) [0|0] "" Vector__XXX
 SG_ M7_CellBalance17 : 16|1@1+ (1,0) [0|0] "" Vector__XXX
 SG_ M7_CellBalance16 : 15|1@1+ (1,0) [0|0] "" Vector__XXX
 SG_ M7_CellBalance15 : 14|1@1+ (1,0) [0|0] "" Vector__XXX
 SG_ M7_CellBalance14 : 13|1@1+ (1,0) [0|0] "" Vector__XXX
 SG_ M7_CellBalance13 : 12|1@1+ (1,0) [0|0] "" Vector__XXX
 SG_ M7_CellBalance9 : 8|1@1+ (1,0) [0|0] "" Vector__XXX
 SG_ M7_CellBalance8 : 7|1@1+ (1,0) [0|0] "" Vector__XXX
 SG_ M7_CellBalance7 : 6|1@1+ (1,0) [0|0] "" Vector__XXX
 SG_ M7_CellBalance6 : 5|1@1+ (1,0) [0|0] "" Vector__XXX
 SG_ M7_CellBalance5 : 4|1@1+ (1,0) [0|0] "" Vector__XXX
 SG_ M7_CellBalance4 : 3|1@1+ (1,0) [0|0] "" Vector__XXX
 SG_ M7_CellBalance3 : 2|1@1+ (1,0) [0|0] "" Vector__XXX
 SG_ M7_CellBalance2 : 1|1@1+ (1,0) [0|0] "" Vector__XXX
 SG_ M7_CellBalance12 : 11|1@1+ (1,0) [0|0] "" Vector__XXX
 SG_ M7_CellBalance11 : 10|1@1+ (1,0) [0|0] "" Vector__XXX
 SG_ M7_CellBalance10 : 9|1@1+ (1,0) [0|0] "" Vector__XXX
 SG_ M7_CellBalance1 : 0|1@1+ (1,0) [0|0] "" Vector__XXX

BO_ 345 Lecu5MsgH: 8 Vector__XXX
 SG_ Lecu_Version3 : 63|8@0+ (1,0) [0|0] "" Vector__XXX
 SG_ Lecu_Version2 : 55|8@0+ (1,0) [0|0] "" Vector__XXX
 SG_ Lecu_Version1 : 47|8@0+ (1,0) [0|0] "" Vector__XXX
 SG_ Lecu_Version0 : 39|8@0+ (1,0) [0|0] "" Vector__XXX
 SG_ M5_CellBalance24 : 23|1@1+ (1,0) [0|0] "" Vector__XXX
 SG_ M5_CellBalance23 : 22|1@1+ (1,0) [0|0] "" Vector__XXX
 SG_ M5_CellBalance22 : 21|1@1+ (1,0) [0|0] "" Vector__XXX
 SG_ M5_CellBalance21 : 20|1@1+ (1,0) [0|0] "" Vector__XXX
 SG_ M5_CellBalance20 : 19|1@1+ (1,0) [0|0] "" Vector__XXX
 SG_ M5_CellBalance19 : 18|1@1+ (1,0) [0|0] "" Vector__XXX
 SG_ M5_CellBalance18 : 17|1@1+ (1,0) [0|0] "" Vector__XXX
 SG_ M5_CellBalance17 : 16|1@1+ (1,0) [0|0] "" Vector__XXX
 SG_ M5_CellBalance16 : 15|1@1+ (1,0) [0|0] "" Vector__XXX
 SG_ M5_CellBalance15 : 14|1@1+ (1,0) [0|0] "" Vector__XXX
 SG_ M5_CellBalance14 : 13|1@1+ (1,0) [0|0] "" Vector__XXX
 SG_ M5_CellBalance13 : 12|1@1+ (1,0) [0|0] "" Vector__XXX
 SG_ M5_CellBalance11 : 10|1@1+ (1,0) [0|0] "" Vector__XXX
 SG_ M5_CellBalance10 : 9|1@1+ (1,0) [0|0] "" Vector__XXX
 SG_ M5_CellBalance9 : 8|1@1+ (1,0) [0|0] "" Vector__XXX
 SG_ M5_CellBalance8 : 7|1@1+ (1,0) [0|0] "" Vector__XXX
 SG_ M5_CellBalance7 : 6|1@1+ (1,0) [0|0] "" Vector__XXX
 SG_ M5_CellBalance6 : 5|1@1+ (1,0) [0|0] "" Vector__XXX
 SG_ M5_CellBalance5 : 4|1@1+ (1,0) [0|0] "" Vector__XXX
 SG_ M5_CellBalance4 : 3|1@1+ (1,0) [0|0] "" Vector__XXX
 SG_ M5_CellBalance3 : 2|1@1+ (1,0) [0|0] "" Vector__XXX
 SG_ M5_CellBalance2 : 1|1@1+ (1,0) [0|0] "" Vector__XXX
 SG_ M5_CellBalance12 : 11|1@1+ (1,0) [0|0] "" Vector__XXX
 SG_ M5_CellBalance1 : 0|1@1+ (1,0) [0|0] "" Vector__XXX

BO_ 329 Lecu4MsgH: 8 Vector__XXX
 SG_ Lecu_Version3 : 63|8@0+ (1,0) [0|0] "" Vector__XXX
 SG_ Lecu_Version2 : 55|8@0+ (1,0) [0|0] "" Vector__XXX
 SG_ Lecu_Version1 : 47|8@0+ (1,0) [0|0] "" Vector__XXX
 SG_ Lecu_Version0 : 39|8@0+ (1,0) [0|0] "" Vector__XXX
 SG_ M4_CellBalance24 : 23|1@1+ (1,0) [0|0] "" Vector__XXX
 SG_ M4_CellBalance23 : 22|1@1+ (1,0) [0|0] "" Vector__XXX
 SG_ M4_CellBalance22 : 21|1@1+ (1,0) [0|0] "" Vector__XXX
 SG_ M4_CellBalance21 : 20|1@1+ (1,0) [0|0] "" Vector__XXX
 SG_ M4_CellBalance20 : 19|1@1+ (1,0) [0|0] "" Vector__XXX
 SG_ M4_CellBalance19 : 18|1@1+ (1,0) [0|0] "" Vector__XXX
 SG_ M4_CellBalance18 : 17|1@1+ (1,0) [0|0] "" Vector__XXX
 SG_ M4_CellBalance17 : 16|1@1+ (1,0) [0|0] "" Vector__XXX
 SG_ M4_CellBalance16 : 15|1@1+ (1,0) [0|0] "" Vector__XXX
 SG_ M4_CellBalance15 : 14|1@1+ (1,0) [0|0] "" Vector__XXX
 SG_ M4_CellBalance14 : 13|1@1+ (1,0) [0|0] "" Vector__XXX
 SG_ M4_CellBalance13 : 12|1@1+ (1,0) [0|0] "" Vector__XXX
 SG_ M4_CellBalance9 : 8|1@1+ (1,0) [0|0] "" Vector__XXX
 SG_ M4_CellBalance8 : 7|1@1+ (1,0) [0|0] "" Vector__XXX
 SG_ M4_CellBalance7 : 6|1@1+ (1,0) [0|0] "" Vector__XXX
 SG_ M4_CellBalance6 : 5|1@1+ (1,0) [0|0] "" Vector__XXX
 SG_ M4_CellBalance5 : 4|1@1+ (1,0) [0|0] "" Vector__XXX
 SG_ M4_CellBalance4 : 3|1@1+ (1,0) [0|0] "" Vector__XXX
 SG_ M4_CellBalance3 : 2|1@1+ (1,0) [0|0] "" Vector__XXX
 SG_ M4_CellBalance2 : 1|1@1+ (1,0) [0|0] "" Vector__XXX
 SG_ M4_CellBalance12 : 11|1@1+ (1,0) [0|0] "" Vector__XXX
 SG_ M4_CellBalance11 : 10|1@1+ (1,0) [0|0] "" Vector__XXX
 SG_ M4_CellBalance10 : 9|1@1+ (1,0) [0|0] "" Vector__XXX
 SG_ M4_CellBalance1 : 0|1@1+ (1,0) [0|0] "" Vector__XXX

BO_ 313 Lecu3MsgH: 8 Vector__XXX
 SG_ Lecu_Version3 : 63|8@0+ (1,0) [0|0] "" Vector__XXX
 SG_ Lecu_Version2 : 55|8@0+ (1,0) [0|0] "" Vector__XXX
 SG_ Lecu_Version1 : 47|8@0+ (1,0) [0|0] "" Vector__XXX
 SG_ Lecu_Version0 : 39|8@0+ (1,0) [0|0] "" Vector__XXX
 SG_ M3_CellBalance24 : 23|1@1+ (1,0) [0|0] "" Vector__XXX
 SG_ M3_CellBalance23 : 22|1@1+ (1,0) [0|0] "" Vector__XXX
 SG_ M3_CellBalance22 : 21|1@1+ (1,0) [0|0] "" Vector__XXX
 SG_ M3_CellBalance21 : 20|1@1+ (1,0) [0|0] "" Vector__XXX
 SG_ M3_CellBalance20 : 19|1@1+ (1,0) [0|0] "" Vector__XXX
 SG_ M3_CellBalance19 : 18|1@1+ (1,0) [0|0] "" Vector__XXX
 SG_ M3_CellBalance18 : 17|1@1+ (1,0) [0|0] "" Vector__XXX
 SG_ M3_CellBalance17 : 16|1@1+ (1,0) [0|0] "" Vector__XXX
 SG_ M3_CellBalance16 : 15|1@1+ (1,0) [0|0] "" Vector__XXX
 SG_ M3_CellBalance15 : 14|1@1+ (1,0) [0|0] "" Vector__XXX
 SG_ M3_CellBalance14 : 13|1@1+ (1,0) [0|0] "" Vector__XXX
 SG_ M3_CellBalance13 : 12|1@1+ (1,0) [0|0] "" Vector__XXX
 SG_ M3_CellBalance9 : 8|1@1+ (1,0) [0|0] "" Vector__XXX
 SG_ M3_CellBalance8 : 7|1@1+ (1,0) [0|0] "" Vector__XXX
 SG_ M3_CellBalance7 : 6|1@1+ (1,0) [0|0] "" Vector__XXX
 SG_ M3_CellBalance6 : 5|1@1+ (1,0) [0|0] "" Vector__XXX
 SG_ M3_CellBalance5 : 4|1@1+ (1,0) [0|0] "" Vector__XXX
 SG_ M3_CellBalance4 : 3|1@1+ (1,0) [0|0] "" Vector__XXX
 SG_ M3_CellBalance3 : 2|1@1+ (1,0) [0|0] "" Vector__XXX
 SG_ M3_CellBalance2 : 1|1@1+ (1,0) [0|0] "" Vector__XXX
 SG_ M3_CellBalance12 : 11|1@1+ (1,0) [0|0] "" Vector__XXX
 SG_ M3_CellBalance11 : 10|1@1+ (1,0) [0|0] "" Vector__XXX
 SG_ M3_CellBalance10 : 9|1@1+ (1,0) [0|0] "" Vector__XXX
 SG_ M3_CellBalance1 : 0|1@1+ (1,0) [0|0] "" Vector__XXX

BO_ 297 Lecu2MsgH: 8 Vector__XXX
 SG_ Lecu_Version3 : 63|8@0+ (1,0) [0|0] "" Vector__XXX
 SG_ Lecu_Version2 : 55|8@0+ (1,0) [0|0] "" Vector__XXX
 SG_ Lecu_Version1 : 47|8@0+ (1,0) [0|0] "" Vector__XXX
 SG_ Lecu_Version0 : 39|8@0+ (1,0) [0|0] "" Vector__XXX
 SG_ M2_CellBalance24 : 23|1@1+ (1,0) [0|0] "" Vector__XXX
 SG_ M2_CellBalance23 : 22|1@1+ (1,0) [0|0] "" Vector__XXX
 SG_ M2_CellBalance22 : 21|1@1+ (1,0) [0|0] "" Vector__XXX
 SG_ M2_CellBalance21 : 20|1@1+ (1,0) [0|0] "" Vector__XXX
 SG_ M2_CellBalance20 : 19|1@1+ (1,0) [0|0] "" Vector__XXX
 SG_ M2_CellBalance19 : 18|1@1+ (1,0) [0|0] "" Vector__XXX
 SG_ M2_CellBalance18 : 17|1@1+ (1,0) [0|0] "" Vector__XXX
 SG_ M2_CellBalance17 : 16|1@1+ (1,0) [0|0] "" Vector__XXX
 SG_ M2_CellBalance16 : 15|1@1+ (1,0) [0|0] "" Vector__XXX
 SG_ M2_CellBalance15 : 14|1@1+ (1,0) [0|0] "" Vector__XXX
 SG_ M2_CellBalance14 : 13|1@1+ (1,0) [0|0] "" Vector__XXX
 SG_ M2_CellBalance13 : 12|1@1+ (1,0) [0|0] "" Vector__XXX
 SG_ M2_CellBalance9 : 8|1@1+ (1,0) [0|0] "" Vector__XXX
 SG_ M2_CellBalance8 : 7|1@1+ (1,0) [0|0] "" Vector__XXX
 SG_ M2_CellBalance7 : 6|1@1+ (1,0) [0|0] "" Vector__XXX
 SG_ M2_CellBalance6 : 5|1@1+ (1,0) [0|0] "" Vector__XXX
 SG_ M2_CellBalance5 : 4|1@1+ (1,0) [0|0] "" Vector__XXX
 SG_ M2_CellBalance4 : 3|1@1+ (1,0) [0|0] "" Vector__XXX
 SG_ M2_CellBalance3 : 2|1@1+ (1,0) [0|0] "" Vector__XXX
 SG_ M2_CellBalance2 : 1|1@1+ (1,0) [0|0] "" Vector__XXX
 SG_ M2_CellBalance12 : 11|1@1+ (1,0) [0|0] "" Vector__XXX
 SG_ M2_CellBalance11 : 10|1@1+ (1,0) [0|0] "" Vector__XXX
 SG_ M2_CellBalance10 : 9|1@1+ (1,0) [0|0] "" Vector__XXX
 SG_ M2_CellBalance1 : 0|1@1+ (1,0) [0|0] "" Vector__XXX

BO_ 281 Lecu1MsgH: 8 Vector__XXX
 SG_ Lecu_Version3 : 63|8@0+ (1,0) [0|0] "" Vector__XXX
 SG_ Lecu_Version2 : 55|8@0+ (1,0) [0|0] "" Vector__XXX
 SG_ Lecu_Version1 : 47|8@0+ (1,0) [0|0] "" Vector__XXX
 SG_ Lecu_Version0 : 39|8@0+ (1,0) [0|0] "" Vector__XXX
 SG_ M1_CellBalance24 : 23|1@1+ (1,0) [0|0] "" Vector__XXX
 SG_ M1_CellBalance23 : 22|1@1+ (1,0) [0|0] "" Vector__XXX
 SG_ M1_CellBalance22 : 21|1@1+ (1,0) [0|0] "" Vector__XXX
 SG_ M1_CellBalance21 : 20|1@1+ (1,0) [0|0] "" Vector__XXX
 SG_ M1_CellBalance20 : 19|1@1+ (1,0) [0|0] "" Vector__XXX
 SG_ M1_CellBalance19 : 18|1@1+ (1,0) [0|0] "" Vector__XXX
 SG_ M1_CellBalance18 : 17|1@1+ (1,0) [0|0] "" Vector__XXX
 SG_ M1_CellBalance17 : 16|1@1+ (1,0) [0|0] "" Vector__XXX
 SG_ M1_CellBalance16 : 15|1@1+ (1,0) [0|0] "" Vector__XXX
 SG_ M1_CellBalance15 : 14|1@1+ (1,0) [0|0] "" Vector__XXX
 SG_ M1_CellBalance14 : 13|1@1+ (1,0) [0|0] "" Vector__XXX
 SG_ M1_CellBalance13 : 12|1@1+ (1,0) [0|0] "" Vector__XXX
 SG_ M1_CellBalance9 : 8|1@1+ (1,0) [0|0] "" Vector__XXX
 SG_ M1_CellBalance8 : 7|1@1+ (1,0) [0|0] "" Vector__XXX
 SG_ M1_CellBalance7 : 6|1@1+ (1,0) [0|0] "" Vector__XXX
 SG_ M1_CellBalance6 : 5|1@1+ (1,0) [0|0] "" Vector__XXX
 SG_ M1_CellBalance5 : 4|1@1+ (1,0) [0|0] "" Vector__XXX
 SG_ M1_CellBalance4 : 3|1@1+ (1,0) [0|0] "" Vector__XXX
 SG_ M1_CellBalance3 : 2|1@1+ (1,0) [0|0] "" Vector__XXX
 SG_ M1_CellBalance2 : 1|1@1+ (1,0) [0|0] "" Vector__XXX
 SG_ M1_CellBalance12 : 11|1@1+ (1,0) [0|0] "" Vector__XXX
 SG_ M1_CellBalance11 : 10|1@1+ (1,0) [0|0] "" Vector__XXX
 SG_ M1_CellBalance10 : 9|1@1+ (1,0) [0|0] "" Vector__XXX
 SG_ M1_CellBalance1 : 0|1@1+ (1,0) [0|0] "" Vector__XXX

BO_ 432 Lecu11MsgA: 8 LECU11
 SG_ M11_Tem_Min_Valid : 63|1@1+ (1,0) [0|0] ""  BMU
 SG_ M11_Tem_Min : 48|11@1+ (0.1,-40) [0|0] "℃"  BMU
 SG_ M11_Tem_Max_Valid : 47|1@1+ (1,0) [0|0] ""  BMU
 SG_ M11_Tem_Max : 32|11@1+ (0.1,-40) [0|0] "℃"  BMU
 SG_ M11_CellVoltageMin_Valid : 31|1@1+ (1,0) [0|0] ""  BMU
 SG_ M11_CellVoltageMin : 16|15@1- (0.001,0) [0|0] "V"  BMU
 SG_ M11_CellVoltageMax_Valid : 15|1@1+ (1,0) [0|0] ""  BMU
 SG_ M11_CellVoltageMax : 0|15@1- (0.001,0) [0|0] "V"  BMU

BO_ 416 Lecu10MsgA: 8 LECU10
 SG_ M10_Tem_Min_Valid : 63|1@1+ (1,0) [0|0] ""  BMU
 SG_ M10_Tem_Min : 48|11@1+ (0.1,-40) [0|0] "℃"  BMU
 SG_ M10_Tem_Max_Valid : 47|1@1+ (1,0) [0|0] ""  BMU
 SG_ M10_Tem_Max : 32|11@1+ (0.1,-40) [0|0] "℃"  BMU
 SG_ M10_CellVoltageMin_Valid : 31|1@1+ (1,0) [0|0] ""  BMU
 SG_ M10_CellVoltageMin : 16|15@1- (0.001,0) [0|0] "V"  BMU
 SG_ M10_CellVoltageMax_Valid : 15|1@1+ (1,0) [0|0] ""  BMU
 SG_ M10_CellVoltageMax : 0|15@1- (0.001,0) [0|0] "V"  BMU

BO_ 408 Lecu9MsgG: 8 Vector__XXX
 SG_ M9_Tem8_Valid : 63|1@1+ (1,0) [0|0] "" Vector__XXX
 SG_ M9_Tem8 : 48|11@1+ (0.1,-40) [0|0] "" Vector__XXX
 SG_ M9_Tem7_Valid : 47|1@1+ (1,0) [0|0] "" Vector__XXX
 SG_ M9_Tem7 : 32|11@1+ (0.1,-40) [0|0] "" Vector__XXX
 SG_ M9_Tem6_Valid : 31|1@1+ (1,0) [0|0] "" Vector__XXX
 SG_ M9_Tem6 : 16|11@1+ (0.1,-40) [0|0] "" Vector__XXX
 SG_ M9_Tem5_Valid : 15|1@1+ (1,0) [0|0] "" Vector__XXX
 SG_ M9_Tem5 : 0|11@1+ (0.1,-40) [0|0] "" Vector__XXX

BO_ 407 Lecu9MsgF: 8 Vector__XXX
 SG_ M9_Tem4_Valid : 63|1@1+ (1,0) [0|0] "" Vector__XXX
 SG_ M9_Tem4 : 48|11@1+ (0.1,-40) [0|0] "" Vector__XXX
 SG_ M9_Tem3_Valid : 47|1@1+ (1,0) [0|0] "" Vector__XXX
 SG_ M9_Tem3 : 32|11@1+ (0.1,-40) [0|0] "" Vector__XXX
 SG_ M9_Tem2_Valid : 31|1@1+ (1,0) [0|0] "" Vector__XXX
 SG_ M9_Tem2 : 16|11@1+ (0.1,-40) [0|0] "" Vector__XXX
 SG_ M9_Tem1_Valid : 15|1@1+ (1,0) [0|0] "" Vector__XXX
 SG_ M9_Tem1 : 0|11@1+ (0.1,-40) [0|0] "" Vector__XXX

BO_ 406 Lecu9MsgE: 8 Vector__XXX
 SG_ M9_CellVoltage12_Valid : 63|1@1+ (1,0) [0|0] "" Vector__XXX
 SG_ M9_CellVoltage12 : 48|15@1- (0.001,0) [0|0] "" Vector__XXX
 SG_ M9_CellVoltage11_Valid : 47|1@1+ (1,0) [0|0] "" Vector__XXX
 SG_ M9_CellVoltage11 : 32|15@1- (0.001,0) [0|0] "" Vector__XXX
 SG_ M9_CellVoltage10_Valid : 31|1@1+ (1,0) [0|0] "" Vector__XXX
 SG_ M9_CellVoltage10 : 16|15@1- (0.001,0) [0|0] "" Vector__XXX
 SG_ M9_CellVoltage9_Valid : 15|1@1+ (1,0) [0|0] "" Vector__XXX
 SG_ M9_CellVoltage9 : 0|15@1- (0.001,0) [0|0] "" Vector__XXX

BO_ 405 Lecu9MsgD: 8 Vector__XXX
 SG_ M9_CellVoltage8_Valid : 63|1@1+ (1,0) [0|0] "" Vector__XXX
 SG_ M9_CellVoltage8 : 48|15@1- (0.001,0) [0|0] "" Vector__XXX
 SG_ M9_CellVoltage7_Valid : 47|1@1+ (1,0) [0|0] "" Vector__XXX
 SG_ M9_CellVoltage7 : 32|15@1- (0.001,0) [0|0] "" Vector__XXX
 SG_ M9_CellVoltage6_Valid : 31|1@1+ (1,0) [0|0] "" Vector__XXX
 SG_ M9_CellVoltage6 : 16|15@1- (0.001,0) [0|0] "" Vector__XXX
 SG_ M9_CellVoltage5_Valid : 15|1@1+ (1,0) [0|0] "" Vector__XXX
 SG_ M9_CellVoltage5 : 0|15@1- (0.001,0) [0|0] "" Vector__XXX

BO_ 404 Lecu9MsgC: 8 Vector__XXX
 SG_ M9_CellVoltage4_Valid : 63|1@1+ (1,0) [0|0] "" Vector__XXX
 SG_ M9_CellVoltage4 : 48|15@1- (0.001,0) [0|0] "" Vector__XXX
 SG_ M9_CellVoltage3_Valid : 47|1@1+ (1,0) [0|0] "" Vector__XXX
 SG_ M9_CellVoltage3 : 32|15@1- (0.001,0) [0|0] "" Vector__XXX
 SG_ M9_CellVoltage2_Valid : 31|1@1+ (1,0) [0|0] "" Vector__XXX
 SG_ M9_CellVoltage2 : 16|15@1- (0.001,0) [0|0] "" Vector__XXX
 SG_ M9_CellVoltage1_Valid : 15|1@1+ (1,0) [0|0] "" Vector__XXX
 SG_ M9_CellVoltage1 : 0|15@1- (0.001,0) [0|0] "" Vector__XXX

BO_ 392 Lecu8MsgG: 8 Vector__XXX
 SG_ M8_Tem8_Valid : 63|1@1+ (1,0) [0|0] "" Vector__XXX
 SG_ M8_Tem8 : 48|11@1+ (0.1,-40) [0|0] "" Vector__XXX
 SG_ M8_Tem7_Valid : 47|1@1+ (1,0) [0|0] "" Vector__XXX
 SG_ M8_Tem7 : 32|11@1+ (0.1,-40) [0|0] "" Vector__XXX
 SG_ M8_Tem6_Valid : 31|1@1+ (1,0) [0|0] "" Vector__XXX
 SG_ M8_Tem6 : 16|11@1+ (0.1,-40) [0|0] "" Vector__XXX
 SG_ M8_Tem5_Valid : 15|1@1+ (1,0) [0|0] "" Vector__XXX
 SG_ M8_Tem5 : 0|11@1+ (0.1,-40) [0|0] "" Vector__XXX

BO_ 391 Lecu8MsgF: 8 Vector__XXX
 SG_ M8_Tem4_Valid : 63|1@1+ (1,0) [0|0] "" Vector__XXX
 SG_ M8_Tem4 : 48|11@1+ (0.1,-40) [0|0] "" Vector__XXX
 SG_ M8_Tem3_Valid : 47|1@1+ (1,0) [0|0] "" Vector__XXX
 SG_ M8_Tem3 : 32|11@1+ (0.1,-40) [0|0] "" Vector__XXX
 SG_ M8_Tem2_Valid : 31|1@1+ (1,0) [0|0] "" Vector__XXX
 SG_ M8_Tem2 : 16|11@1+ (0.1,-40) [0|0] "" Vector__XXX
 SG_ M8_Tem1_Valid : 15|1@1+ (1,0) [0|0] "" Vector__XXX
 SG_ M8_Tem1 : 0|11@1+ (0.1,-40) [0|0] "" Vector__XXX

BO_ 390 Lecu8MsgE: 8 Vector__XXX
 SG_ M8_CellVoltage12_Valid : 63|1@1+ (1,0) [0|0] "" Vector__XXX
 SG_ M8_CellVoltage12 : 48|15@1- (0.001,0) [0|0] "" Vector__XXX
 SG_ M8_CellVoltage11_Valid : 47|1@1+ (1,0) [0|0] "" Vector__XXX
 SG_ M8_CellVoltage11 : 32|15@1- (0.001,0) [0|0] "" Vector__XXX
 SG_ M8_CellVoltage10_Valid : 31|1@1+ (1,0) [0|0] "" Vector__XXX
 SG_ M8_CellVoltage10 : 16|15@1- (0.001,0) [0|0] "" Vector__XXX
 SG_ M8_CellVoltage9_Valid : 15|1@1+ (1,0) [0|0] "" Vector__XXX
 SG_ M8_CellVoltage9 : 0|15@1- (0.001,0) [0|0] "" Vector__XXX

BO_ 389 Lecu8MsgD: 8 Vector__XXX
 SG_ M8_CellVoltage8_Valid : 63|1@1+ (1,0) [0|0] "" Vector__XXX
 SG_ M8_CellVoltage8 : 48|15@1- (0.001,0) [0|0] "" Vector__XXX
 SG_ M8_CellVoltage7_Valid : 47|1@1+ (1,0) [0|0] "" Vector__XXX
 SG_ M8_CellVoltage7 : 32|15@1- (0.001,0) [0|0] "" Vector__XXX
 SG_ M8_CellVoltage6_Valid : 31|1@1+ (1,0) [0|0] "" Vector__XXX
 SG_ M8_CellVoltage6 : 16|15@1- (0.001,0) [0|0] "" Vector__XXX
 SG_ M8_CellVoltage5_Valid : 15|1@1+ (1,0) [0|0] "" Vector__XXX
 SG_ M8_CellVoltage5 : 0|15@1- (0.001,0) [0|0] "" Vector__XXX

BO_ 388 Lecu8MsgC: 8 Vector__XXX
 SG_ M8_CellVoltage4_Valid : 63|1@1+ (1,0) [0|0] "" Vector__XXX
 SG_ M8_CellVoltage4 : 48|15@1- (0.001,0) [0|0] "" Vector__XXX
 SG_ M8_CellVoltage3_Valid : 47|1@1+ (1,0) [0|0] "" Vector__XXX
 SG_ M8_CellVoltage3 : 32|15@1- (0.001,0) [0|0] "" Vector__XXX
 SG_ M8_CellVoltage2_Valid : 31|1@1+ (1,0) [0|0] "" Vector__XXX
 SG_ M8_CellVoltage2 : 16|15@1- (0.001,0) [0|0] "" Vector__XXX
 SG_ M8_CellVoltage1_Valid : 15|1@1+ (1,0) [0|0] "" Vector__XXX
 SG_ M8_CellVoltage1 : 0|15@1- (0.001,0) [0|0] "" Vector__XXX

BO_ 376 Lecu7MsgG: 8 Vector__XXX
 SG_ M7_Tem8_Valid : 63|1@1+ (1,0) [0|0] "" Vector__XXX
 SG_ M7_Tem8 : 48|11@1+ (0.1,-40) [0|0] "" Vector__XXX
 SG_ M7_Tem7_Valid : 47|1@1+ (1,0) [0|0] "" Vector__XXX
 SG_ M7_Tem7 : 32|11@1+ (0.1,-40) [0|0] "" Vector__XXX
 SG_ M7_Tem6_Valid : 31|1@1+ (1,0) [0|0] "" Vector__XXX
 SG_ M7_Tem6 : 16|11@1+ (0.1,-40) [0|0] "" Vector__XXX
 SG_ M7_Tem5_Valid : 15|1@1+ (1,0) [0|0] "" Vector__XXX
 SG_ M7_Tem5 : 0|11@1+ (0.1,-40) [0|0] "" Vector__XXX

BO_ 375 Lecu7MsgF: 8 Vector__XXX
 SG_ M7_Tem4_Valid : 63|1@1+ (1,0) [0|0] "" Vector__XXX
 SG_ M7_Tem4 : 48|11@1+ (0.1,-40) [0|0] "" Vector__XXX
 SG_ M7_Tem3_Valid : 47|1@1+ (1,0) [0|0] "" Vector__XXX
 SG_ M7_Tem3 : 32|11@1+ (0.1,-40) [0|0] "" Vector__XXX
 SG_ M7_Tem2_Valid : 31|1@1+ (1,0) [0|0] "" Vector__XXX
 SG_ M7_Tem2 : 16|11@1+ (0.1,-40) [0|0] "" Vector__XXX
 SG_ M7_Tem1_Valid : 15|1@1+ (1,0) [0|0] "" Vector__XXX
 SG_ M7_Tem1 : 0|11@1+ (0.1,-40) [0|0] "" Vector__XXX

BO_ 374 Lecu7MsgE: 8 Vector__XXX
 SG_ M7_CellVoltage12_Valid : 63|1@1+ (1,0) [0|0] "" Vector__XXX
 SG_ M7_CellVoltage12 : 48|15@1- (0.001,0) [0|0] "" Vector__XXX
 SG_ M7_CellVoltage11_Valid : 47|1@1+ (1,0) [0|0] "" Vector__XXX
 SG_ M7_CellVoltage11 : 32|15@1- (0.001,0) [0|0] "" Vector__XXX
 SG_ M7_CellVoltage10_Valid : 31|1@1+ (1,0) [0|0] "" Vector__XXX
 SG_ M7_CellVoltage10 : 16|15@1- (0.001,0) [0|0] "" Vector__XXX
 SG_ M7_CellVoltage9_Valid : 15|1@1+ (1,0) [0|0] "" Vector__XXX
 SG_ M7_CellVoltage9 : 0|15@1- (0.001,0) [0|0] "" Vector__XXX

BO_ 373 Lecu7MsgD: 8 Vector__XXX
 SG_ M7_CellVoltage8_Valid : 63|1@1+ (1,0) [0|0] "" Vector__XXX
 SG_ M7_CellVoltage8 : 48|15@1- (0.001,0) [0|0] "" Vector__XXX
 SG_ M7_CellVoltage7_Valid : 47|1@1+ (1,0) [0|0] "" Vector__XXX
 SG_ M7_CellVoltage7 : 32|15@1- (0.001,0) [0|0] "" Vector__XXX
 SG_ M7_CellVoltage6_Valid : 31|1@1+ (1,0) [0|0] "" Vector__XXX
 SG_ M7_CellVoltage6 : 16|15@1- (0.001,0) [0|0] "" Vector__XXX
 SG_ M7_CellVoltage5_Valid : 15|1@1+ (1,0) [0|0] "" Vector__XXX
 SG_ M7_CellVoltage5 : 0|15@1- (0.001,0) [0|0] "" Vector__XXX

BO_ 372 Lecu7MsgC: 8 Vector__XXX
 SG_ M7_CellVoltage4_Valid : 63|1@1+ (1,0) [0|0] "" Vector__XXX
 SG_ M7_CellVoltage4 : 48|15@1- (0.001,0) [0|0] "" Vector__XXX
 SG_ M7_CellVoltage3_Valid : 47|1@1+ (1,0) [0|0] "" Vector__XXX
 SG_ M7_CellVoltage3 : 32|15@1- (0.001,0) [0|0] "" Vector__XXX
 SG_ M7_CellVoltage2_Valid : 31|1@1+ (1,0) [0|0] "" Vector__XXX
 SG_ M7_CellVoltage2 : 16|15@1- (0.001,0) [0|0] "" Vector__XXX
 SG_ M7_CellVoltage1_Valid : 15|1@1+ (1,0) [0|0] "" Vector__XXX
 SG_ M7_CellVoltage1 : 0|15@1- (0.001,0) [0|0] "" Vector__XXX

BO_ 360 Lecu6MsgG: 8 Vector__XXX
 SG_ M6_Tem8_Valid : 63|1@1+ (1,0) [0|0] "" Vector__XXX
 SG_ M6_Tem8 : 48|11@1+ (0.1,-40) [0|0] "" Vector__XXX
 SG_ M6_Tem7_Valid : 47|1@1+ (1,0) [0|0] "" Vector__XXX
 SG_ M6_Tem7 : 32|11@1+ (0.1,-40) [0|0] "" Vector__XXX
 SG_ M6_Tem6_Valid : 31|1@1+ (1,0) [0|0] "" Vector__XXX
 SG_ M6_Tem6 : 16|11@1+ (0.1,-40) [0|0] "" Vector__XXX
 SG_ M6_Tem5_Valid : 15|1@1+ (1,0) [0|0] "" Vector__XXX
 SG_ M6_Tem5 : 0|11@1+ (0.1,-40) [0|0] "" Vector__XXX

BO_ 358 Lecu6MsgE: 8 Vector__XXX
 SG_ M6_CellVoltage12_Valid : 63|1@1+ (1,0) [0|0] "" Vector__XXX
 SG_ M6_CellVoltage12 : 48|15@1- (0.001,0) [0|0] "" Vector__XXX
 SG_ M6_CellVoltage11_Valid : 47|1@1+ (1,0) [0|0] "" Vector__XXX
 SG_ M6_CellVoltage11 : 32|15@1- (0.001,0) [0|0] "" Vector__XXX
 SG_ M6_CellVoltage10_Valid : 31|1@1+ (1,0) [0|0] "" Vector__XXX
 SG_ M6_CellVoltage10 : 16|15@1- (0.001,0) [0|0] "" Vector__XXX
 SG_ M6_CellVoltage9_Valid : 15|1@1+ (1,0) [0|0] "" Vector__XXX
 SG_ M6_CellVoltage9 : 0|15@1- (0.001,0) [0|0] "" Vector__XXX

BO_ 359 Lecu6MsgF: 8 Vector__XXX
 SG_ M6_Tem4_Valid : 63|1@1+ (1,0) [0|0] "" Vector__XXX
 SG_ M6_Tem4 : 48|11@1+ (0.1,-40) [0|0] "" Vector__XXX
 SG_ M6_Tem3_Valid : 47|1@1+ (1,0) [0|0] "" Vector__XXX
 SG_ M6_Tem3 : 32|11@1+ (0.1,-40) [0|0] "" Vector__XXX
 SG_ M6_Tem2_Valid : 31|1@1+ (1,0) [0|0] "" Vector__XXX
 SG_ M6_Tem2 : 16|11@1+ (0.1,-40) [0|0] "" Vector__XXX
 SG_ M6_Tem1_Valid : 15|1@1+ (1,0) [0|0] "" Vector__XXX
 SG_ M6_Tem1 : 0|11@1+ (0.1,-40) [0|0] "" Vector__XXX

BO_ 357 Lecu6MsgD: 8 Vector__XXX
 SG_ M6_CellVoltage8_Valid : 63|1@1+ (1,0) [0|0] "" Vector__XXX
 SG_ M6_CellVoltage8 : 48|15@1- (0.001,0) [0|0] "" Vector__XXX
 SG_ M6_CellVoltage7_Valid : 47|1@1+ (1,0) [0|0] "" Vector__XXX
 SG_ M6_CellVoltage7 : 32|15@1- (0.001,0) [0|0] "" Vector__XXX
 SG_ M6_CellVoltage6_Valid : 31|1@1+ (1,0) [0|0] "" Vector__XXX
 SG_ M6_CellVoltage6 : 16|15@1- (0.001,0) [0|0] "" Vector__XXX
 SG_ M6_CellVoltage5_Valid : 15|1@1+ (1,0) [0|0] "" Vector__XXX
 SG_ M6_CellVoltage5 : 0|15@1- (0.001,0) [0|0] "" Vector__XXX

BO_ 356 Lecu6MsgC: 8 Vector__XXX
 SG_ M6_CellVoltage4_Valid : 63|1@1+ (1,0) [0|0] "" Vector__XXX
 SG_ M6_CellVoltage4 : 48|15@1- (0.001,0) [0|0] "" Vector__XXX
 SG_ M6_CellVoltage3_Valid : 47|1@1+ (1,0) [0|0] "" Vector__XXX
 SG_ M6_CellVoltage3 : 32|15@1- (0.001,0) [0|0] "" Vector__XXX
 SG_ M6_CellVoltage2_Valid : 31|1@1+ (1,0) [0|0] "" Vector__XXX
 SG_ M6_CellVoltage2 : 16|15@1- (0.001,0) [0|0] "" Vector__XXX
 SG_ M6_CellVoltage1_Valid : 15|1@1+ (1,0) [0|0] "" Vector__XXX
 SG_ M6_CellVoltage1 : 0|15@1- (0.001,0) [0|0] "" Vector__XXX

BO_ 344 Lecu5MsgG: 8 Vector__XXX
 SG_ M5_Tem8_Valid : 63|1@1+ (1,0) [0|0] "" Vector__XXX
 SG_ M5_Tem8 : 48|11@1+ (0.1,-40) [0|0] "" Vector__XXX
 SG_ M5_Tem7_Valid : 47|1@1+ (1,0) [0|0] "" Vector__XXX
 SG_ M5_Tem7 : 32|11@1+ (0.1,-40) [0|0] "" Vector__XXX
 SG_ M5_Tem6_Valid : 31|1@1+ (1,0) [0|0] "" Vector__XXX
 SG_ M5_Tem6 : 16|11@1+ (0.1,-40) [0|0] "" Vector__XXX
 SG_ M5_Tem5_Valid : 15|1@1+ (1,0) [0|0] "" Vector__XXX
 SG_ M5_Tem5 : 0|11@1+ (0.1,-40) [0|0] "" Vector__XXX

BO_ 343 Lecu5MsgF: 8 Vector__XXX
 SG_ M5_Tem4_Valid : 63|1@1+ (1,0) [0|0] "" Vector__XXX
 SG_ M5_Tem4 : 48|11@1+ (0.1,-40) [0|0] "" Vector__XXX
 SG_ M5_Tem3_Valid : 47|1@1+ (1,0) [0|0] "" Vector__XXX
 SG_ M5_Tem3 : 32|11@1+ (0.1,-40) [0|0] "" Vector__XXX
 SG_ M5_Tem2_Valid : 31|1@1+ (1,0) [0|0] "" Vector__XXX
 SG_ M5_Tem2 : 16|11@1+ (0.1,-40) [0|0] "" Vector__XXX
 SG_ M5_Tem1_Valid : 15|1@1+ (1,0) [0|0] "" Vector__XXX
 SG_ M5_Tem1 : 0|11@1+ (0.1,-40) [0|0] "" Vector__XXX

BO_ 342 Lecu5MsgE: 8 Vector__XXX
 SG_ M5_CellVoltage9_Valid : 15|1@1+ (1,0) [0|0] "" Vector__XXX
 SG_ M5_CellVoltage9 : 0|15@1- (0.001,0) [0|0] "" Vector__XXX
 SG_ M5_CellVoltage12_Valid : 63|1@1+ (1,0) [0|0] "" Vector__XXX
 SG_ M5_CellVoltage12 : 48|15@1- (0.001,0) [0|0] "" Vector__XXX
 SG_ M5_CellVoltage11_Valid : 47|1@1+ (1,0) [0|0] "" Vector__XXX
 SG_ M5_CellVoltage11 : 32|15@1- (0.001,0) [0|0] "" Vector__XXX
 SG_ M5_CellVoltage10_Valid : 31|1@1+ (1,0) [0|0] "" Vector__XXX
 SG_ M5_CellVoltage10 : 16|15@1- (0.001,0) [0|0] "" Vector__XXX

BO_ 341 Lecu5MsgD: 8 Vector__XXX
 SG_ M5_CellVoltage8_Valid : 63|1@1+ (1,0) [0|0] "" Vector__XXX
 SG_ M5_CellVoltage8 : 48|15@1- (0.001,0) [0|0] "" Vector__XXX
 SG_ M5_CellVoltage7_Valid : 47|1@1+ (1,0) [0|0] "" Vector__XXX
 SG_ M5_CellVoltage7 : 32|15@1- (0.001,0) [0|0] "" Vector__XXX
 SG_ M5_CellVoltage6_Valid : 31|1@1+ (1,0) [0|0] "" Vector__XXX
 SG_ M5_CellVoltage6 : 16|15@1- (0.001,0) [0|0] "" Vector__XXX
 SG_ M5_CellVoltage5_Valid : 15|1@1+ (1,0) [0|0] "" Vector__XXX
 SG_ M5_CellVoltage5 : 0|15@1- (0.001,0) [0|0] "" Vector__XXX

BO_ 340 Lecu5MsgC: 8 Vector__XXX
 SG_ M5_CellVoltage4_Valid : 63|1@1+ (1,0) [0|0] "" Vector__XXX
 SG_ M5_CellVoltage4 : 48|15@1- (0.001,0) [0|0] "" Vector__XXX
 SG_ M5_CellVoltage3_Valid : 47|1@1+ (1,0) [0|0] "" Vector__XXX
 SG_ M5_CellVoltage3 : 32|15@1- (0.001,0) [0|0] "" Vector__XXX
 SG_ M5_CellVoltage2_Valid : 31|1@1+ (1,0) [0|0] "" Vector__XXX
 SG_ M5_CellVoltage2 : 16|15@1- (0.001,0) [0|0] "" Vector__XXX
 SG_ M5_CellVoltage1_Valid : 15|1@1+ (1,0) [0|0] "" Vector__XXX
 SG_ M5_CellVoltage1 : 0|15@1- (0.001,0) [0|0] "" Vector__XXX

BO_ 328 Lecu4MsgG: 8 Vector__XXX
 SG_ M4_Tem8_Valid : 63|1@1+ (1,0) [0|0] "" Vector__XXX
 SG_ M4_Tem8 : 48|11@1+ (0.1,-40) [0|0] "" Vector__XXX
 SG_ M4_Tem7_Valid : 47|1@1+ (1,0) [0|0] "" Vector__XXX
 SG_ M4_Tem7 : 32|11@1+ (0.1,-40) [0|0] "" Vector__XXX
 SG_ M4_Tem6_Valid : 31|1@1+ (1,0) [0|0] "" Vector__XXX
 SG_ M4_Tem6 : 16|11@1+ (0.1,-40) [0|0] "" Vector__XXX
 SG_ M4_Tem5_Valid : 15|1@1+ (1,0) [0|0] "" Vector__XXX
 SG_ M4_Tem5 : 0|11@1+ (0.1,-40) [0|0] "" Vector__XXX

BO_ 327 Lecu4MsgF: 8 Vector__XXX
 SG_ M4_Tem4_Valid : 63|1@1+ (1,0) [0|0] "" Vector__XXX
 SG_ M4_Tem4 : 48|11@1+ (0.1,-40) [0|0] "" Vector__XXX
 SG_ M4_Tem3_Valid : 47|1@1+ (1,0) [0|0] "" Vector__XXX
 SG_ M4_Tem3 : 32|11@1+ (0.1,-40) [0|0] "" Vector__XXX
 SG_ M4_Tem2_Valid : 31|1@1+ (1,0) [0|0] "" Vector__XXX
 SG_ M4_Tem2 : 16|11@1+ (0.1,-40) [0|0] "" Vector__XXX
 SG_ M4_Tem1_Valid : 15|1@1+ (1,0) [0|0] "" Vector__XXX
 SG_ M4_Tem1 : 0|11@1+ (0.1,-40) [0|0] "" Vector__XXX

BO_ 326 Lecu4MsgE: 8 Vector__XXX
 SG_ M4_CellVoltage12_Valid : 63|1@1+ (1,0) [0|0] "" Vector__XXX
 SG_ M4_CellVoltage12 : 48|15@1- (0.001,0) [0|0] "" Vector__XXX
 SG_ M4_CellVoltage11_Valid : 47|1@1+ (1,0) [0|0] "" Vector__XXX
 SG_ M4_CellVoltage11 : 32|15@1- (0.001,0) [0|0] "" Vector__XXX
 SG_ M4_CellVoltage10_Valid : 31|1@1+ (1,0) [0|0] "" Vector__XXX
 SG_ M4_CellVoltage10 : 16|15@1- (0.001,0) [0|0] "" Vector__XXX
 SG_ M4_CellVoltage9_Valid : 15|1@1+ (1,0) [0|0] "" Vector__XXX
 SG_ M4_CellVoltage9 : 0|15@1- (0.001,0) [0|0] "" Vector__XXX

BO_ 325 Lecu4MsgD: 8 Vector__XXX
 SG_ M4_CellVoltage8_Valid : 63|1@1+ (1,0) [0|0] "" Vector__XXX
 SG_ M4_CellVoltage8 : 48|15@1- (0.001,0) [0|0] "" Vector__XXX
 SG_ M4_CellVoltage7_Valid : 47|1@1+ (1,0) [0|0] "" Vector__XXX
 SG_ M4_CellVoltage7 : 32|15@1- (0.001,0) [0|0] "" Vector__XXX
 SG_ M4_CellVoltage6_Valid : 31|1@1+ (1,0) [0|0] "" Vector__XXX
 SG_ M4_CellVoltage6 : 16|15@1- (0.001,0) [0|0] "" Vector__XXX
 SG_ M4_CellVoltage5_Valid : 15|1@1+ (1,0) [0|0] "" Vector__XXX
 SG_ M4_CellVoltage5 : 0|15@1- (0.001,0) [0|0] "" Vector__XXX

BO_ 324 Lecu4MsgC: 8 Vector__XXX
 SG_ M4_CellVoltage4_Valid : 63|1@1+ (1,0) [0|0] "" Vector__XXX
 SG_ M4_CellVoltage4 : 48|15@1- (0.001,0) [0|0] "" Vector__XXX
 SG_ M4_CellVoltage3_Valid : 47|1@1+ (1,0) [0|0] "" Vector__XXX
 SG_ M4_CellVoltage3 : 32|15@1- (0.001,0) [0|0] "" Vector__XXX
 SG_ M4_CellVoltage2_Valid : 31|1@1+ (1,0) [0|0] "" Vector__XXX
 SG_ M4_CellVoltage2 : 16|15@1- (0.001,0) [0|0] "" Vector__XXX
 SG_ M4_CellVoltage1_Valid : 15|1@1+ (1,0) [0|0] "" Vector__XXX
 SG_ M4_CellVoltage1 : 0|15@1- (0.001,0) [0|0] "" Vector__XXX

BO_ 312 Lecu3MsgG: 8 Vector__XXX
 SG_ M3_Tem8_Valid : 63|1@1+ (1,0) [0|0] "" Vector__XXX
 SG_ M3_Tem8 : 48|11@1+ (0.1,-40) [0|0] "" Vector__XXX
 SG_ M3_Tem7_Valid : 47|1@1+ (1,0) [0|0] "" Vector__XXX
 SG_ M3_Tem7 : 32|11@1+ (0.1,-40) [0|0] "" Vector__XXX
 SG_ M3_Tem6_Valid : 31|1@1+ (1,0) [0|0] "" Vector__XXX
 SG_ M3_Tem6 : 16|11@1+ (0.1,-40) [0|0] "" Vector__XXX
 SG_ M3_Tem5_Valid : 15|1@1+ (1,0) [0|0] "" Vector__XXX
 SG_ M3_Tem5 : 0|11@1+ (0.1,-40) [0|0] "" Vector__XXX

BO_ 311 Lecu3MsgF: 8 Vector__XXX
 SG_ M3_Tem4_Valid : 63|1@1+ (1,0) [0|0] "" Vector__XXX
 SG_ M3_Tem4 : 48|11@1+ (0.1,-40) [0|0] "" Vector__XXX
 SG_ M3_Tem3_Valid : 47|1@1+ (1,0) [0|0] "" Vector__XXX
 SG_ M3_Tem3 : 32|11@1+ (0.1,-40) [0|0] "" Vector__XXX
 SG_ M3_Tem2_Valid : 31|1@1+ (1,0) [0|0] "" Vector__XXX
 SG_ M3_Tem2 : 16|11@1+ (0.1,-40) [0|0] "" Vector__XXX
 SG_ M3_Tem1_Valid : 15|1@1+ (1,0) [0|0] "" Vector__XXX
 SG_ M3_Tem1 : 0|11@1+ (0.1,-40) [0|0] "" Vector__XXX

BO_ 310 Lecu3MsgE: 8 Vector__XXX
 SG_ M3_CellVoltage12_Valid : 63|1@1+ (1,0) [0|0] "" Vector__XXX
 SG_ M3_CellVoltage12 : 48|15@1- (0.001,0) [0|0] "" Vector__XXX
 SG_ M3_CellVoltage11_Valid : 47|1@1+ (1,0) [0|0] "" Vector__XXX
 SG_ M3_CellVoltage11 : 32|15@1- (0.001,0) [0|0] "" Vector__XXX
 SG_ M3_CellVoltage10_Valid : 31|1@1+ (1,0) [0|0] "" Vector__XXX
 SG_ M3_CellVoltage10 : 16|15@1- (0.001,0) [0|0] "" Vector__XXX
 SG_ M3_CellVoltage9_Valid : 15|1@1+ (1,0) [0|0] "" Vector__XXX
 SG_ M3_CellVoltage9 : 0|15@1- (0.001,0) [0|0] "" Vector__XXX

BO_ 309 Lecu3MsgD: 8 Vector__XXX
 SG_ M3_CellVoltage8_Valid : 63|1@1+ (1,0) [0|0] "" Vector__XXX
 SG_ M3_CellVoltage8 : 48|15@1- (0.001,0) [0|0] "" Vector__XXX
 SG_ M3_CellVoltage7_Valid : 47|1@1+ (1,0) [0|0] "" Vector__XXX
 SG_ M3_CellVoltage7 : 32|15@1- (0.001,0) [0|0] "" Vector__XXX
 SG_ M3_CellVoltage6_Valid : 31|1@1+ (1,0) [0|0] "" Vector__XXX
 SG_ M3_CellVoltage6 : 16|15@1- (0.001,0) [0|0] "" Vector__XXX
 SG_ M3_CellVoltage5_Valid : 15|1@1+ (1,0) [0|0] "" Vector__XXX
 SG_ M3_CellVoltage5 : 0|15@1- (0.001,0) [0|0] "" Vector__XXX

BO_ 308 Lecu3MsgC: 8 Vector__XXX
 SG_ M3_CellVoltage4_Valid : 63|1@1+ (1,0) [0|0] "" Vector__XXX
 SG_ M3_CellVoltage4 : 48|15@1- (0.001,0) [0|0] "" Vector__XXX
 SG_ M3_CellVoltage3_Valid : 47|1@1+ (1,0) [0|0] "" Vector__XXX
 SG_ M3_CellVoltage3 : 32|15@1- (0.001,0) [0|0] "" Vector__XXX
 SG_ M3_CellVoltage2_Valid : 31|1@1+ (1,0) [0|0] "" Vector__XXX
 SG_ M3_CellVoltage2 : 16|15@1- (0.001,0) [0|0] "" Vector__XXX
 SG_ M3_CellVoltage1_Valid : 15|1@1+ (1,0) [0|0] "" Vector__XXX
 SG_ M3_CellVoltage1 : 0|15@1- (0.001,0) [0|0] "" Vector__XXX

BO_ 296 Lecu2MsgG: 8 Vector__XXX
 SG_ M2_Tem8_Valid : 63|1@1+ (1,0) [0|0] "" Vector__XXX
 SG_ M2_Tem8 : 48|11@1+ (0.1,-40) [0|0] "" Vector__XXX
 SG_ M2_Tem7_Valid : 47|1@1+ (1,0) [0|0] "" Vector__XXX
 SG_ M2_Tem7 : 32|11@1+ (0.1,-40) [0|0] "" Vector__XXX
 SG_ M2_Tem6_Valid : 31|1@1+ (1,0) [0|0] "" Vector__XXX
 SG_ M2_Tem6 : 16|11@1+ (0.1,-40) [0|0] "" Vector__XXX
 SG_ M2_Tem5_Valid : 15|1@1+ (1,0) [0|0] "" Vector__XXX
 SG_ M2_Tem5 : 0|11@1+ (0.1,-40) [0|0] "" Vector__XXX

BO_ 295 Lecu2MsgF: 8 Vector__XXX
 SG_ M2_Tem4_Valid : 63|1@1+ (1,0) [0|0] "" Vector__XXX
 SG_ M2_Tem4 : 48|11@1+ (0.1,-40) [0|0] "" Vector__XXX
 SG_ M2_Tem3_Valid : 47|1@1+ (1,0) [0|0] "" Vector__XXX
 SG_ M2_Tem3 : 32|11@1+ (0.1,-40) [0|0] "" Vector__XXX
 SG_ M2_Tem2_Valid : 31|1@1+ (1,0) [0|0] "" Vector__XXX
 SG_ M2_Tem2 : 16|11@1+ (0.1,-40) [0|0] "" Vector__XXX
 SG_ M2_Tem1_Valid : 15|1@1+ (1,0) [0|0] "" Vector__XXX
 SG_ M2_Tem1 : 0|11@1+ (0.1,-40) [0|0] "" Vector__XXX

BO_ 294 Lecu2MsgE: 8 Vector__XXX
 SG_ M2_CellVoltage12_Valid : 63|1@1+ (1,0) [0|0] "" Vector__XXX
 SG_ M2_CellVoltage12 : 48|15@1- (0.001,0) [0|0] "" Vector__XXX
 SG_ M2_CellVoltage11_Valid : 47|1@1+ (1,0) [0|0] "" Vector__XXX
 SG_ M2_CellVoltage11 : 32|15@1- (0.001,0) [0|0] "" Vector__XXX
 SG_ M2_CellVoltage10_Valid : 31|1@1+ (1,0) [0|0] "" Vector__XXX
 SG_ M2_CellVoltage10 : 16|15@1- (0.001,0) [0|0] "" Vector__XXX
 SG_ M2_CellVoltage9_Valid : 15|1@1+ (1,0) [0|0] "" Vector__XXX
 SG_ M2_CellVoltage9 : 0|15@1- (0.001,0) [0|0] "" Vector__XXX

BO_ 293 Lecu2MsgD: 8 Vector__XXX
 SG_ M2_CellVoltage8_Valid : 63|1@1+ (1,0) [0|0] "" Vector__XXX
 SG_ M2_CellVoltage8 : 48|15@1- (0.001,0) [0|0] "" Vector__XXX
 SG_ M2_CellVoltage7_Valid : 47|1@1+ (1,0) [0|0] "" Vector__XXX
 SG_ M2_CellVoltage7 : 32|15@1- (0.001,0) [0|0] "" Vector__XXX
 SG_ M2_CellVoltage6_Valid : 31|1@1+ (1,0) [0|0] "" Vector__XXX
 SG_ M2_CellVoltage6 : 16|15@1- (0.001,0) [0|0] "" Vector__XXX
 SG_ M2_CellVoltage5_Valid : 15|1@1+ (1,0) [0|0] "" Vector__XXX
 SG_ M2_CellVoltage5 : 0|15@1- (0.001,0) [0|0] "" Vector__XXX

BO_ 292 Lecu2MsgC: 8 Vector__XXX
 SG_ M2_CellVoltage4_Valid : 63|1@1+ (1,0) [0|0] "" Vector__XXX
 SG_ M2_CellVoltage4 : 48|15@1- (0.001,0) [0|0] "" Vector__XXX
 SG_ M2_CellVoltage3_Valid : 47|1@1+ (1,0) [0|0] "" Vector__XXX
 SG_ M2_CellVoltage3 : 32|15@1- (0.001,0) [0|0] "" Vector__XXX
 SG_ M2_CellVoltage1_Valid : 15|1@1+ (1,0) [0|0] "" Vector__XXX
 SG_ M2_CellVoltage2 : 16|15@1- (0.001,0) [0|0] "" Vector__XXX
 SG_ M2_CellVoltage2_Valid : 31|1@1+ (1,0) [0|0] "" Vector__XXX
 SG_ M2_CellVoltage1 : 0|15@1- (0.001,0) [0|0] "" Vector__XXX

BO_ 384 Lecu8MsgA: 8 LECU8
 SG_ M8_Tem_Min_Valid : 63|1@1+ (1,0) [0|0] ""  BMU
 SG_ M8_Tem_Min : 48|11@1+ (0.1,-40) [0|0] "℃"  BMU
 SG_ M8_Tem_Max_Valid : 47|1@1+ (1,0) [0|0] ""  BMU
 SG_ M8_Tem_Max : 32|11@1+ (0.1,-40) [0|0] "℃"  BMU
 SG_ M8_CellVoltageMin_Valid : 31|1@1+ (1,0) [0|0] ""  BMU
 SG_ M8_CellVoltageMin : 16|15@1- (0.001,0) [0|0] "V"  BMU
 SG_ M8_CellVoltageMax_Valid : 15|1@1+ (1,0) [0|0] ""  BMU
 SG_ M8_CellVoltageMax : 0|15@1- (0.001,0) [0|0] "V"  BMU

BO_ 400 Lecu9MsgA: 8 LECU9
 SG_ M9_Tem_Min_Valid : 63|1@1+ (1,0) [0|0] ""  BMU
 SG_ M9_Tem_Min : 48|11@1+ (0.1,-40) [0|0] "℃"  BMU
 SG_ M9_Tem_Max_Valid : 47|1@1+ (1,0) [0|0] ""  BMU
 SG_ M9_Tem_Max : 32|11@1+ (0.1,-40) [0|0] "℃"  BMU
 SG_ M9_CellVoltageMin_Valid : 31|1@1+ (1,0) [0|0] ""  BMU
 SG_ M9_CellVoltageMin : 16|15@1- (0.001,0) [0|0] "V"  BMU
 SG_ M9_CellVoltageMax_Valid : 15|1@1+ (1,0) [0|0] ""  BMU
 SG_ M9_CellVoltageMax : 0|15@1- (0.001,0) [0|0] "V"  BMU

BO_ 368 Lecu7MsgA: 8 LECU7
 SG_ M7_Tem_Min_Valid : 63|1@1+ (1,0) [0|0] ""  BMU
 SG_ M7_Tem_Min : 48|11@1+ (0.1,-40) [0|0] "℃"  BMU
 SG_ M7_Tem_Max_Valid : 47|1@1+ (1,0) [0|0] ""  BMU
 SG_ M7_Tem_Max : 32|11@1+ (0.1,-40) [0|0] "℃"  BMU
 SG_ M7_CellVoltageMin_Valid : 31|1@1+ (1,0) [0|0] ""  BMU
 SG_ M7_CellVoltageMin : 16|15@1- (0.001,0) [0|0] "V"  BMU
 SG_ M7_CellVoltageMax_Valid : 15|1@1+ (1,0) [0|0] ""  BMU
 SG_ M7_CellVoltageMax : 0|15@1- (0.001,0) [0|0] "V"  BMU

BO_ 352 Lecu6MsgA: 8 LECU6
 SG_ M6_Tem_Min_Valid : 63|1@1+ (1,0) [0|0] ""  BMU
 SG_ M6_Tem_Min : 48|11@1+ (0.1,-40) [0|0] "℃"  BMU
 SG_ M6_Tem_Max_Valid : 47|1@1+ (1,0) [0|0] ""  BMU
 SG_ M6_Tem_Max : 32|11@1+ (0.1,-40) [0|0] "℃"  BMU
 SG_ M6_CellVoltageMin_Valid : 31|1@1+ (1,0) [0|0] ""  BMU
 SG_ M6_CellVoltageMin : 16|15@1- (0.001,0) [0|0] "V"  BMU
 SG_ M6_CellVoltageMax_Valid : 15|1@1+ (1,0) [0|0] ""  BMU
 SG_ M6_CellVoltageMax : 0|15@1- (0.001,0) [0|0] "V"  BMU

BO_ 336 Lecu5MsgA: 8 LECU5
 SG_ M5_Tem_Min_Valid : 63|1@1+ (1,0) [0|0] ""  BMU
 SG_ M5_Tem_Min : 48|11@1+ (0.1,-40) [0|0] "℃"  BMU
 SG_ M5_Tem_Max_Valid : 47|1@1+ (1,0) [0|0] ""  BMU
 SG_ M5_Tem_Max : 32|11@1+ (0.1,-40) [0|0] "℃"  BMU
 SG_ M5_CellVoltageMin_Valid : 31|1@1+ (1,0) [0|0] ""  BMU
 SG_ M5_CellVoltageMin : 16|15@1- (0.001,0) [0|0] "V"  BMU
 SG_ M5_CellVoltageMax_Valid : 15|1@1+ (1,0) [0|0] ""  BMU
 SG_ M5_CellVoltageMax : 0|15@1- (0.001,0) [0|0] "V"  BMU

BO_ 320 Lecu4MsgA: 8 LECU4
 SG_ M4_Tem_Min_Valid : 63|1@1+ (1,0) [0|0] ""  BMU
 SG_ M4_Tem_Min : 48|11@1+ (0.1,-40) [0|0] "℃"  BMU
 SG_ M4_Tem_Max_Valid : 47|1@1+ (1,0) [0|0] ""  BMU
 SG_ M4_Tem_Max : 32|11@1+ (0.1,-40) [0|0] "℃"  BMU
 SG_ M4_CellVoltageMin_Valid : 31|1@1+ (1,0) [0|0] ""  BMU
 SG_ M4_CellVoltageMin : 16|15@1- (0.001,0) [0|0] "V"  BMU
 SG_ M4_CellVoltageMax_Valid : 15|1@1+ (1,0) [0|0] ""  BMU
 SG_ M4_CellVoltageMax : 0|15@1- (0.001,0) [0|0] "V"  BMU

BO_ 304 Lecu3MsgA: 8 LECU3
 SG_ M3_Tem_Min_Valid : 63|1@1+ (1,0) [0|0] ""  BMU
 SG_ M3_Tem_Min : 48|11@1+ (0.1,-40) [0|0] "℃"  BMU
 SG_ M3_Tem_Max_Valid : 47|1@1+ (1,0) [0|0] ""  BMU
 SG_ M3_Tem_Max : 32|11@1+ (0.1,-40) [0|0] "℃"  BMU
 SG_ M3_CellVoltageMin_Valid : 31|1@1+ (1,0) [0|0] ""  BMU
 SG_ M3_CellVoltageMin : 16|15@1- (0.001,0) [0|0] "V"  BMU
 SG_ M3_CellVoltageMax_Valid : 15|1@1+ (1,0) [0|0] ""  BMU
 SG_ M3_CellVoltageMax : 0|15@1- (0.001,0) [0|0] "V"  BMU

BO_ 288 Lecu2MsgA: 8 LECU2
 SG_ M2_Tem_Min_Valid : 63|1@1+ (1,0) [0|0] ""  BMU
 SG_ M2_Tem_Min : 48|11@1+ (0.1,-40) [0|0] "℃"  BMU
 SG_ M2_Tem_Max_Valid : 47|1@1+ (1,0) [0|0] ""  BMU
 SG_ M2_Tem_Max : 32|11@1+ (0.1,-40) [0|0] "℃"  BMU
 SG_ M2_CellVoltageMin_Valid : 31|1@1+ (1,0) [0|0] ""  BMU
 SG_ M2_CellVoltageMin : 16|15@1- (0.001,0) [0|0] "V"  BMU
 SG_ M2_CellVoltageMax_Valid : 15|1@1+ (1,0) [0|0] ""  BMU
 SG_ M2_CellVoltageMax : 0|15@1- (0.001,0) [0|0] "V"  BMU

BO_ 256 Local_CAN_MsgA: 3 BMU
 SG_ LocalCAN_RedundancyMsg_Rqu : 21|1@1+ (1,0) [0|0] ""  LECU25,LECU23,LECU22,LECU21,LECU19,LECU20,LECU18,LECU17,LECU16,LECU15,LECU14,LECU12,LECU11,LECU10,LECU9,LECU8,LECU7,LECU6,LECU5,LECU4,LECU2,LECU31,LECU30,LECU29,LECU28,LECU27,LECU26,LECU24,LECU13,LECU3,LECU1

BO_ 280 Lecu1MsgG: 8 Vector__XXX
 SG_ M1_Tem8_Valid : 63|1@1+ (1,0) [0|0] "" Vector__XXX
 SG_ M1_Tem8 : 48|11@1+ (0.1,-40) [0|0] "" Vector__XXX
 SG_ M1_Tem7_Valid : 47|1@1+ (1,0) [0|0] "" Vector__XXX
 SG_ M1_Tem7 : 32|11@1+ (0.1,-40) [0|0] "" Vector__XXX
 SG_ M1_Tem6_Valid : 31|1@1+ (1,0) [0|0] "" Vector__XXX
 SG_ M1_Tem5_Valid : 15|1@1+ (1,0) [0|0] "" Vector__XXX
 SG_ M1_Tem6 : 16|11@1+ (0.1,-40) [0|0] "" Vector__XXX
 SG_ M1_Tem5 : 0|11@1+ (0.1,-40) [0|0] "" Vector__XXX

BO_ 279 Lecu1MsgF: 8 Vector__XXX
 SG_ M1_Tem4_Valid : 63|1@1+ (1,0) [0|0] "" Vector__XXX
 SG_ M1_Tem3_Valid : 47|1@1+ (1,0) [0|0] "" Vector__XXX
 SG_ M1_Tem2_Valid : 31|1@1+ (1,0) [0|0] "" Vector__XXX
 SG_ M1_Tem1_Valid : 15|1@1+ (1,0) [0|0] "" Vector__XXX
 SG_ M1_Tem4 : 48|11@1+ (0.1,-40) [0|0] "" Vector__XXX
 SG_ M1_Tem3 : 32|11@1+ (0.1,-40) [0|0] "" Vector__XXX
 SG_ M1_Tem2 : 16|11@1+ (0.1,-40) [0|0] "" Vector__XXX
 SG_ M1_Tem1 : 0|11@1+ (0.1,-40) [0|0] "" Vector__XXX

BO_ 278 Lecu1MsgE: 8 Vector__XXX
 SG_ M1_CellVoltage12_Valid : 63|1@1+ (1,0) [0|0] "" Vector__XXX
 SG_ M1_CellVoltage11_Valid : 47|1@1+ (1,0) [0|0] "" Vector__XXX
 SG_ M1_CellVoltage10_Valid : 31|1@1+ (1,0) [0|0] "" Vector__XXX
 SG_ M1_CellVoltage9_Valid : 15|1@1+ (1,0) [0|0] "" Vector__XXX
 SG_ M1_CellVoltage9 : 0|15@1- (0.001,0) [0|0] "" Vector__XXX
 SG_ M1_CellVoltage10 : 16|15@1- (0.001,0) [0|0] "" Vector__XXX
 SG_ M1_CellVoltage11 : 32|15@1- (0.001,0) [0|0] "" Vector__XXX
 SG_ M1_CellVoltage12 : 48|15@1- (0.001,0) [0|0] "" Vector__XXX

BO_ 277 Lecu1MsgD: 8 Vector__XXX
 SG_ M1_CellVoltage8_Valid : 63|1@1+ (1,0) [0|0] "" Vector__XXX
 SG_ M1_CellVoltage7_Valid : 47|1@1+ (1,0) [0|0] "" Vector__XXX
 SG_ M1_CellVoltage6_Valid : 31|1@1+ (1,0) [0|0] "" Vector__XXX
 SG_ M1_CellVoltage5_Valid : 15|1@1+ (1,0) [0|0] "" Vector__XXX
 SG_ M1_CellVoltage5 : 0|15@1- (0.001,0) [0|0] "" Vector__XXX
 SG_ M1_CellVoltage6 : 16|15@1- (0.001,0) [0|0] "" Vector__XXX
 SG_ M1_CellVoltage8 : 48|15@1- (0.001,0) [0|0] "" Vector__XXX
 SG_ M1_CellVoltage7 : 32|15@1- (0.001,0) [0|0] "" Vector__XXX

BO_ 276 Lecu1MsgC: 8 Vector__XXX
 SG_ M1_CellVoltage4_Valid : 63|1@1+ (1,0) [0|0] "" Vector__XXX
 SG_ M1_CellVoltage3_Valid : 47|1@1+ (1,0) [0|0] "" Vector__XXX
 SG_ M1_CellVoltage2_Valid : 31|1@1+ (1,0) [0|0] "" Vector__XXX
 SG_ M1_CellVoltage1_Valid : 15|1@1+ (1,0) [0|0] "" Vector__XXX
 SG_ M1_CellVoltage4 : 48|15@1- (0.001,0) [0|0] "" Vector__XXX
 SG_ M1_CellVoltage3 : 32|15@1- (0.001,0) [0|0] "" Vector__XXX
 SG_ M1_CellVoltage2 : 16|15@1- (0.001,0) [0|0] "" Vector__XXX
 SG_ M1_CellVoltage1 : 0|15@1- (0.001,0) [0|0] "" Vector__XXX

BO_ 272 Lecu1MsgA: 8 LECU1
 SG_ M1_Tem_Min_Valid : 63|1@1+ (1,0) [0|0] ""  BMU
 SG_ M1_Tem_Max_Valid : 47|1@1+ (1,0) [0|0] ""  BMU
 SG_ M1_CellVoltageMin_Valid : 31|1@1+ (1,0) [0|0] ""  BMU
 SG_ M1_CellVoltageMax_Valid : 15|1@1+ (1,0) [0|0] ""  BMU
 SG_ M1_Tem_Min : 48|11@1+ (0.1,-40) [0|0] "℃"  BMU
 SG_ M1_Tem_Max : 32|11@1+ (0.1,-40) [0|0] "℃"  BMU
 SG_ M1_CellVoltageMin : 16|15@1- (0.001,0) [0|0] "V"  BMU
 SG_ M1_CellVoltageMax : 0|15@1- (0.001,0) [0|0] "V"  BMU

EV_ gParaReflashEnable: 0 [0|0] "" 0 1 DUMMY_NODE_VECTOR0 Vector__XXX;

EV_ gParaModeCmd: 0 [0|0] "" 0 2 DUMMY_NODE_VECTOR0 Vector__XXX;

EV_ gParaTxEnable: 0 [0|0] "" 0 3 DUMMY_NODE_VECTOR0 Vector__XXX;

EV_ BusCurMaxCalBChg1: 0 [0|0] "" 0 4 DUMMY_NODE_VECTOR0 Vector__XXX;

EV_ BusCurMaxCalBChg0: 0 [0|0] "" 0 5 DUMMY_NODE_VECTOR0 Vector__XXX;

EV_ BusCurMaxCalAChg1: 0 [0|0] "" 0 6 DUMMY_NODE_VECTOR0 Vector__XXX;

EV_ BusCurMaxCalAChg0: 0 [0|0] "" 0 7 DUMMY_NODE_VECTOR0 Vector__XXX;

EV_ BusCurMinCalBChg1: 0 [0|0] "" 0 8 DUMMY_NODE_VECTOR0 Vector__XXX;

EV_ BusCurMinCalBChg0: 0 [0|0] "" 0 9 DUMMY_NODE_VECTOR0 Vector__XXX;

EV_ BusCurMinCalAChg1: 0 [0|0] "" 0 10 DUMMY_NODE_VECTOR0 Vector__XXX;

EV_ BusCurMinCalAChg0: 0 [0|0] "" 0 11 DUMMY_NODE_VECTOR0 Vector__XXX;

EV_ gBusCurMinCalA1: 0 [0|0] "" 0 12 DUMMY_NODE_VECTOR0 Vector__XXX;

EV_ gBusCurMinCalA0: 0 [0|0] "" 0 13 DUMMY_NODE_VECTOR0 Vector__XXX;

EV_ gBusCurMinCalB0: 0 [0|0] "" 0 14 DUMMY_NODE_VECTOR0 Vector__XXX;

EV_ gBusCurMinCalB1: 0 [0|0] "" 0 15 DUMMY_NODE_VECTOR0 Vector__XXX;

EV_ gBusCurMaxCalA0: 0 [0|0] "" 0 16 DUMMY_NODE_VECTOR0 Vector__XXX;

EV_ gBusCurMaxCalA1: 0 [0|0] "" 0 17 DUMMY_NODE_VECTOR0 Vector__XXX;

EV_ gBusCurMaxCalB1: 0 [0|0] "" 0 18 DUMMY_NODE_VECTOR0 Vector__XXX;

EV_ gBusCurMaxCalB0: 0 [0|0] "" 0 19 DUMMY_NODE_VECTOR0 Vector__XXX;

EV_ Send: 0 [0|0] "" 0 20 DUMMY_NODE_VECTOR0 Vector__XXX;

EV_ Min: 0 [0|0] "" 0 21 DUMMY_NODE_VECTOR0 Vector__XXX;

EV_ Hour: 0 [0|0] "" 0 22 DUMMY_NODE_VECTOR0 Vector__XXX;

EV_ Month: 0 [0|0] "" 0 23 DUMMY_NODE_VECTOR0 Vector__XXX;

EV_ Year: 0 [0|0] "" 0 24 DUMMY_NODE_VECTOR0 Vector__XXX;

EV_ CMD: 0 [0|32] "" 0 25 DUMMY_NODE_VECTOR3 Vector__XXX;

EV_ Day: 0 [0|50] "" 0 26 DUMMY_NODE_VECTOR3 Vector__XXX;
CM_ SG_ 504 M15_Tem8 "温度值";
CM_ SG_ 504 M15_Tem7 "温度值";
CM_ SG_ 504 M15_Tem6 "温度值";
CM_ SG_ 504 M15_Tem5 "温度值";
CM_ SG_ 503 M15_Tem4 "温度值";
CM_ SG_ 503 M15_Tem3 "温度值";
CM_ SG_ 503 M15_Tem2 "温度值";
CM_ SG_ 503 M15_Tem1 "温度值";
CM_ SG_ 502 M15_CellVoltage12 "单体电池电压值";
CM_ SG_ 502 M15_CellVoltage11 "单体电池电压值";
CM_ SG_ 502 M15_CellVoltage10 "单体电池电压值";
CM_ SG_ 502 M15_CellVoltage9 "单体电池电压值";
CM_ SG_ 501 M15_CellVoltage8 "单体电池电压值";
CM_ SG_ 501 M15_CellVoltage7 "单体电池电压值";
CM_ SG_ 501 M15_CellVoltage6 "单体电池电压值";
CM_ SG_ 501 M15_CellVoltage5 "单体电池电压值";
CM_ SG_ 500 M15_CellVoltage4 "单体电池电压值";
CM_ SG_ 500 M15_CellVoltage3 "单体电池电压值";
CM_ SG_ 500 M15_CellVoltage2 "单体电池电压值";
CM_ SG_ 500 M15_CellVoltage1 "单体电池电压值";
CM_ SG_ 496 M15_Tem_Min "温度最小值";
CM_ SG_ 496 M15_Tem_Max "温度最大值";
CM_ SG_ 496 M15_CellVoltageMin "单体电池电压最小值";
CM_ SG_ 496 M15_CellVoltageMax "单体电池电压最大值";
CM_ SG_ 488 M14_Tem8 "温度值";
CM_ SG_ 488 M14_Tem7 "温度值";
CM_ SG_ 488 M14_Tem6 "温度值";
CM_ SG_ 488 M14_Tem5 "温度值";
CM_ SG_ 487 M14_Tem4 "温度值";
CM_ SG_ 487 M14_Tem3 "温度值";
CM_ SG_ 487 M14_Tem2 "温度值";
CM_ SG_ 487 M14_Tem1 "温度值";
CM_ SG_ 486 M14_CellVoltage12 "单体电池电压值";
CM_ SG_ 486 M14_CellVoltage11 "单体电池电压值";
CM_ SG_ 486 M14_CellVoltage10 "单体电池电压值";
CM_ SG_ 486 M14_CellVoltage9 "单体电池电压值";
CM_ SG_ 485 M14_CellVoltage8 "单体电池电压值";
CM_ SG_ 485 M14_CellVoltage7 "单体电池电压值";
CM_ SG_ 485 M14_CellVoltage6 "单体电池电压值";
CM_ SG_ 485 M14_CellVoltage5 "单体电池电压值";
CM_ SG_ 484 M14_CellVoltage4 "单体电池电压值";
CM_ SG_ 484 M14_CellVoltage3 "单体电池电压值";
CM_ SG_ 484 M14_CellVoltage2 "单体电池电压值";
CM_ SG_ 484 M14_CellVoltage1 "单体电池电压值";
CM_ SG_ 480 M14_Tem_Min "温度最小值";
CM_ SG_ 480 M14_Tem_Max "温度最大值";
CM_ SG_ 480 M14_CellVoltageMin "单体电池电压最小值";
CM_ SG_ 480 M14_CellVoltageMax "单体电池电压最大值";
CM_ SG_ 472 M13_Tem8 "温度值";
CM_ SG_ 472 M13_Tem7 "温度值";
CM_ SG_ 472 M13_Tem6 "温度值";
CM_ SG_ 472 M13_Tem5 "温度值";
CM_ SG_ 471 M13_Tem4 "温度值";
CM_ SG_ 471 M13_Tem3 "温度值";
CM_ SG_ 471 M13_Tem2 "温度值";
CM_ SG_ 471 M13_Tem1 "温度值";
CM_ SG_ 470 M13_CellVoltage12 "单体电池电压值";
CM_ SG_ 470 M13_CellVoltage11 "单体电池电压值";
CM_ SG_ 470 M13_CellVoltage10 "单体电池电压值";
CM_ SG_ 470 M13_CellVoltage9 "单体电池电压值";
CM_ SG_ 469 M13_CellVoltage8 "单体电池电压值";
CM_ SG_ 469 M13_CellVoltage7 "单体电池电压值";
CM_ SG_ 469 M13_CellVoltage6 "单体电池电压值";
CM_ SG_ 469 M13_CellVoltage5 "单体电池电压值";
CM_ SG_ 468 M13_CellVoltage4 "单体电池电压值";
CM_ SG_ 468 M13_CellVoltage3 "单体电池电压值";
CM_ SG_ 468 M13_CellVoltage2 "单体电池电压值";
CM_ SG_ 468 M13_CellVoltage1 "单体电池电压值";
CM_ SG_ 464 M13_Tem_Min "温度最小值";
CM_ SG_ 464 M13_Tem_Max "温度最大值";
CM_ SG_ 464 M13_CellVoltageMin "单体电池电压最小值";
CM_ SG_ 464 M13_CellVoltageMax "单体电池电压最大值";
CM_ SG_ 456 M12_Tem8 "温度值";
CM_ SG_ 456 M12_Tem7 "温度值";
CM_ SG_ 456 M12_Tem6 "温度值";
CM_ SG_ 456 M12_Tem5 "温度值";
CM_ SG_ 455 M12_Tem4 "温度值";
CM_ SG_ 455 M12_Tem3 "温度值";
CM_ SG_ 455 M12_Tem2 "温度值";
CM_ SG_ 455 M12_Tem1 "温度值";
CM_ SG_ 454 M12_CellVoltage12 "单体电池电压值";
CM_ SG_ 454 M12_CellVoltage11 "单体电池电压值";
CM_ SG_ 454 M12_CellVoltage10 "单体电池电压值";
CM_ SG_ 454 M12_CellVoltage9 "单体电池电压值";
CM_ SG_ 453 M12_CellVoltage8 "单体电池电压值";
CM_ SG_ 453 M12_CellVoltage7 "单体电池电压值";
CM_ SG_ 453 M12_CellVoltage6 "单体电池电压值";
CM_ SG_ 453 M12_CellVoltage5 "单体电池电压值";
CM_ SG_ 452 M12_CellVoltage4 "单体电池电压值";
CM_ SG_ 452 M12_CellVoltage3 "单体电池电压值";
CM_ SG_ 452 M12_CellVoltage2 "单体电池电压值";
CM_ SG_ 452 M12_CellVoltage1 "单体电池电压值";
CM_ SG_ 440 M11_Tem8 "温度值";
CM_ SG_ 440 M11_Tem7 "温度值";
CM_ SG_ 440 M11_Tem6 "温度值";
CM_ SG_ 440 M11_Tem5 "温度值";
CM_ SG_ 439 M11_Tem4 "温度值";
CM_ SG_ 439 M11_Tem3 "温度值";
CM_ SG_ 439 M11_Tem2 "温度值";
CM_ SG_ 439 M11_Tem1 "温度值";
CM_ SG_ 438 M11_CellVoltage12 "单体电池电压值";
CM_ SG_ 438 M11_CellVoltage11 "单体电池电压值";
CM_ SG_ 438 M11_CellVoltage10 "单体电池电压值";
CM_ SG_ 438 M11_CellVoltage9 "单体电池电压值";
CM_ SG_ 437 M11_CellVoltage8 "单体电池电压值";
CM_ SG_ 437 M11_CellVoltage7 "单体电池电压值";
CM_ SG_ 437 M11_CellVoltage6 "单体电池电压值";
CM_ SG_ 436 M11_CellVoltage4 "单体电池电压值";
CM_ SG_ 436 M11_CellVoltage3 "单体电池电压值";
CM_ SG_ 436 M11_CellVoltage2 "单体电池电压值";
CM_ SG_ 436 M11_CellVoltage1 "单体电池电压值";
CM_ SG_ 448 M12_Tem_Min "温度最小值";
CM_ SG_ 448 M12_Tem_Max "温度最大值";
CM_ SG_ 448 M12_CellVoltageMin "单体电池电压最小值";
CM_ SG_ 448 M12_CellVoltageMax "单体电池电压最大值";
CM_ SG_ 424 M10_Tem8 "温度值";
CM_ SG_ 424 M10_Tem7 "温度值";
CM_ SG_ 424 M10_Tem6 "温度值";
CM_ SG_ 424 M10_Tem5 "温度值";
CM_ SG_ 423 M10_Tem4 "温度值";
CM_ SG_ 423 M10_Tem3 "温度值";
CM_ SG_ 423 M10_Tem2 "温度值";
CM_ SG_ 423 M10_Tem1 "温度值";
CM_ SG_ 422 M10_CellVoltage12 "单体电池电压值";
CM_ SG_ 422 M10_CellVoltage11 "单体电池电压值";
CM_ SG_ 422 M10_CellVoltage10 "单体电池电压值";
CM_ SG_ 422 M10_CellVoltage9 "单体电池电压值";
CM_ SG_ 421 M10_CellVoltage8 "单体电池电压值";
CM_ SG_ 421 M10_CellVoltage7 "单体电池电压值";
CM_ SG_ 421 M10_CellVoltage6 "单体电池电压值";
CM_ SG_ 420 M10_CellVoltage1 "单体电池电压值";
CM_ SG_ 420 M10_CellVoltage4 "单体电池电压值";
CM_ SG_ 420 M10_CellVoltage3 "单体电池电压值";
CM_ SG_ 420 M10_CellVoltage2 "单体电池电压值";
CM_ SG_ 432 M11_Tem_Min "温度最小值";
CM_ SG_ 432 M11_Tem_Max "温度最大值";
CM_ SG_ 432 M11_CellVoltageMin "单体电池电压最小值";
CM_ SG_ 432 M11_CellVoltageMax "单体电池电压最大值";
CM_ SG_ 416 M10_Tem_Min "温度最小值";
CM_ SG_ 416 M10_Tem_Max "温度最大值";
CM_ SG_ 416 M10_CellVoltageMin "单体电池电压最小值";
CM_ SG_ 416 M10_CellVoltageMax "单体电池电压最大值";
CM_ SG_ 408 M9_Tem8 "温度值";
CM_ SG_ 408 M9_Tem7 "温度值";
CM_ SG_ 408 M9_Tem6 "温度值";
CM_ SG_ 408 M9_Tem5 "温度值";
CM_ SG_ 407 M9_Tem4 "温度值";
CM_ SG_ 407 M9_Tem3 "温度值";
CM_ SG_ 407 M9_Tem2 "温度值";
CM_ SG_ 407 M9_Tem1 "温度值";
CM_ SG_ 406 M9_CellVoltage12 "单体电池电压值";
CM_ SG_ 406 M9_CellVoltage11 "单体电池电压值";
CM_ SG_ 406 M9_CellVoltage10 "单体电池电压值";
CM_ SG_ 406 M9_CellVoltage9 "单体电池电压值";
CM_ SG_ 405 M9_CellVoltage8 "单体电池电压值";
CM_ SG_ 405 M9_CellVoltage7 "单体电池电压值";
CM_ SG_ 405 M9_CellVoltage6 "单体电池电压值";
CM_ SG_ 405 M9_CellVoltage5 "单体电池电压值";
CM_ SG_ 404 M9_CellVoltage4 "单体电池电压值";
CM_ SG_ 404 M9_CellVoltage3 "单体电池电压值";
CM_ SG_ 404 M9_CellVoltage2 "单体电池电压值";
CM_ SG_ 404 M9_CellVoltage1 "单体电池电压值";
CM_ SG_ 392 M8_Tem8 "温度值";
CM_ SG_ 392 M8_Tem7 "温度值";
CM_ SG_ 392 M8_Tem6 "温度值";
CM_ SG_ 392 M8_Tem5 "温度值";
CM_ SG_ 391 M8_Tem4 "温度值";
CM_ SG_ 391 M8_Tem3 "温度值";
CM_ SG_ 391 M8_Tem2 "温度值";
CM_ SG_ 391 M8_Tem1 "温度值";
CM_ SG_ 390 M8_CellVoltage12 "单体电池电压值";
CM_ SG_ 390 M8_CellVoltage11 "单体电池电压值";
CM_ SG_ 390 M8_CellVoltage10 "单体电池电压值";
CM_ SG_ 390 M8_CellVoltage9 "单体电池电压值";
CM_ SG_ 389 M8_CellVoltage8 "单体电池电压值";
CM_ SG_ 389 M8_CellVoltage7 "单体电池电压值";
CM_ SG_ 389 M8_CellVoltage6 "单体电池电压值";
CM_ SG_ 389 M8_CellVoltage5 "单体电池电压值";
CM_ SG_ 388 M8_CellVoltage4 "单体电池电压值";
CM_ SG_ 388 M8_CellVoltage3 "单体电池电压值";
CM_ SG_ 388 M8_CellVoltage2 "单体电池电压值";
CM_ SG_ 388 M8_CellVoltage1 "单体电池电压值";
CM_ SG_ 376 M7_Tem8 "温度值";
CM_ SG_ 376 M7_Tem7 "温度值";
CM_ SG_ 376 M7_Tem6 "温度值";
CM_ SG_ 376 M7_Tem5 "温度值";
CM_ SG_ 375 M7_Tem4 "温度值";
CM_ SG_ 375 M7_Tem3 "温度值";
CM_ SG_ 375 M7_Tem2 "温度值";
CM_ SG_ 375 M7_Tem1 "温度值";
CM_ SG_ 374 M7_CellVoltage12 "单体电池电压值";
CM_ SG_ 374 M7_CellVoltage11 "单体电池电压值";
CM_ SG_ 374 M7_CellVoltage10 "单体电池电压值";
CM_ SG_ 374 M7_CellVoltage9 "单体电池电压值";
CM_ SG_ 373 M7_CellVoltage8 "单体电池电压值";
CM_ SG_ 373 M7_CellVoltage7 "单体电池电压值";
CM_ SG_ 373 M7_CellVoltage6 "单体电池电压值";
CM_ SG_ 373 M7_CellVoltage5 "单体电池电压值";
CM_ SG_ 372 M7_CellVoltage4 "单体电池电压值";
CM_ SG_ 372 M7_CellVoltage3 "单体电池电压值";
CM_ SG_ 372 M7_CellVoltage2 "单体电池电压值";
CM_ SG_ 372 M7_CellVoltage1 "单体电池电压值";
CM_ SG_ 360 M6_Tem8 "温度值";
CM_ SG_ 360 M6_Tem7 "温度值";
CM_ SG_ 360 M6_Tem6 "温度值";
CM_ SG_ 360 M6_Tem5 "温度值";
CM_ SG_ 358 M6_CellVoltage12 "单体电池电压值";
CM_ SG_ 358 M6_CellVoltage11 "单体电池电压值";
CM_ SG_ 358 M6_CellVoltage10 "单体电池电压值";
CM_ SG_ 358 M6_CellVoltage9 "单体电池电压值";
CM_ SG_ 359 M6_Tem4 "温度值";
CM_ SG_ 359 M6_Tem3 "温度值";
CM_ SG_ 359 M6_Tem2 "温度值";
CM_ SG_ 359 M6_Tem1 "温度值";
CM_ SG_ 357 M6_CellVoltage8 "单体电池电压值";
CM_ SG_ 357 M6_CellVoltage7 "单体电池电压值";
CM_ SG_ 357 M6_CellVoltage6 "单体电池电压值";
CM_ SG_ 357 M6_CellVoltage5 "单体电池电压值";
CM_ SG_ 356 M6_CellVoltage4 "单体电池电压值";
CM_ SG_ 356 M6_CellVoltage3 "单体电池电压值";
CM_ SG_ 356 M6_CellVoltage2 "单体电池电压值";
CM_ SG_ 356 M6_CellVoltage1 "单体电池电压值";
CM_ SG_ 344 M5_Tem8 "温度值";
CM_ SG_ 344 M5_Tem7 "温度值";
CM_ SG_ 344 M5_Tem6 "温度值";
CM_ SG_ 344 M5_Tem5 "温度值";
CM_ SG_ 343 M5_Tem4 "温度值";
CM_ SG_ 343 M5_Tem3 "温度值";
CM_ SG_ 343 M5_Tem2 "温度值";
CM_ SG_ 343 M5_Tem1 "温度值";
CM_ SG_ 342 M5_CellVoltage9 "单体电池电压值";
CM_ SG_ 342 M5_CellVoltage12 "单体电池电压值";
CM_ SG_ 342 M5_CellVoltage11 "单体电池电压值";
CM_ SG_ 342 M5_CellVoltage10 "单体电池电压值";
CM_ SG_ 341 M5_CellVoltage8 "单体电池电压值";
CM_ SG_ 341 M5_CellVoltage7 "单体电池电压值";
CM_ SG_ 341 M5_CellVoltage6 "单体电池电压值";
CM_ SG_ 341 M5_CellVoltage5 "单体电池电压值";
CM_ SG_ 340 M5_CellVoltage4 "单体电池电压值";
CM_ SG_ 340 M5_CellVoltage3 "单体电池电压值";
CM_ SG_ 340 M5_CellVoltage2 "单体电池电压值";
CM_ SG_ 340 M5_CellVoltage1 "单体电池电压值";
CM_ SG_ 328 M4_Tem8 "温度值";
CM_ SG_ 328 M4_Tem7 "温度值";
CM_ SG_ 328 M4_Tem6 "温度值";
CM_ SG_ 328 M4_Tem5 "温度值";
CM_ SG_ 327 M4_Tem4 "温度值";
CM_ SG_ 327 M4_Tem3 "温度值";
CM_ SG_ 327 M4_Tem2 "温度值";
CM_ SG_ 327 M4_Tem1 "温度值";
CM_ SG_ 326 M4_CellVoltage12 "单体电池电压值";
CM_ SG_ 326 M4_CellVoltage11 "单体电池电压值";
CM_ SG_ 326 M4_CellVoltage10 "单体电池电压值";
CM_ SG_ 326 M4_CellVoltage9 "单体电池电压值";
CM_ SG_ 325 M4_CellVoltage8 "单体电池电压值";
CM_ SG_ 325 M4_CellVoltage7 "单体电池电压值";
CM_ SG_ 325 M4_CellVoltage6 "单体电池电压值";
CM_ SG_ 325 M4_CellVoltage5 "单体电池电压值";
CM_ SG_ 324 M4_CellVoltage4 "单体电池电压值";
CM_ SG_ 324 M4_CellVoltage3 "单体电池电压值";
CM_ SG_ 324 M4_CellVoltage2 "单体电池电压值";
CM_ SG_ 324 M4_CellVoltage1 "单体电池电压值";
CM_ SG_ 312 M3_Tem8 "温度值";
CM_ SG_ 312 M3_Tem7 "温度值";
CM_ SG_ 312 M3_Tem6 "温度值";
CM_ SG_ 312 M3_Tem5 "温度值";
CM_ SG_ 311 M3_Tem4 "温度值";
CM_ SG_ 311 M3_Tem3 "温度值";
CM_ SG_ 311 M3_Tem2 "温度值";
CM_ SG_ 311 M3_Tem1 "温度值";
CM_ SG_ 310 M3_CellVoltage12 "单体电池电压值";
CM_ SG_ 310 M3_CellVoltage11 "单体电池电压值";
CM_ SG_ 310 M3_CellVoltage10 "单体电池电压值";
CM_ SG_ 310 M3_CellVoltage9 "单体电池电压值";
CM_ SG_ 309 M3_CellVoltage8 "单体电池电压值";
CM_ SG_ 309 M3_CellVoltage7 "单体电池电压值";
CM_ SG_ 309 M3_CellVoltage6 "单体电池电压值";
CM_ SG_ 309 M3_CellVoltage5 "单体电池电压值";
CM_ SG_ 308 M3_CellVoltage4 "单体电池电压值";
CM_ SG_ 308 M3_CellVoltage3 "单体电池电压值";
CM_ SG_ 308 M3_CellVoltage2 "单体电池电压值";
CM_ SG_ 308 M3_CellVoltage1 "单体电池电压值";
CM_ SG_ 296 M2_Tem8 "温度值";
CM_ SG_ 296 M2_Tem7 "温度值";
CM_ SG_ 296 M2_Tem6 "温度值";
CM_ SG_ 296 M2_Tem5 "温度值";
CM_ SG_ 295 M2_Tem4 "温度值";
CM_ SG_ 295 M2_Tem3 "温度值";
CM_ SG_ 295 M2_Tem2 "温度值";
CM_ SG_ 295 M2_Tem1 "温度值";
CM_ SG_ 294 M2_CellVoltage12 "单体电池电压值";
CM_ SG_ 294 M2_CellVoltage11 "单体电池电压值";
CM_ SG_ 294 M2_CellVoltage10 "单体电池电压值";
CM_ SG_ 294 M2_CellVoltage9 "单体电池电压值";
CM_ SG_ 293 M2_CellVoltage8 "单体电池电压值";
CM_ SG_ 293 M2_CellVoltage7 "单体电池电压值";
CM_ SG_ 293 M2_CellVoltage6 "单体电池电压值";
CM_ SG_ 293 M2_CellVoltage5 "单体电池电压值";
CM_ SG_ 292 M2_CellVoltage4 "单体电池电压值";
CM_ SG_ 292 M2_CellVoltage3 "单体电池电压值";
CM_ SG_ 292 M2_CellVoltage2 "单体电池电压值";
CM_ SG_ 292 M2_CellVoltage1 "单体电池电压值";
CM_ SG_ 384 M8_Tem_Min "温度最小值";
CM_ SG_ 384 M8_Tem_Max "温度最大值";
CM_ SG_ 384 M8_CellVoltageMin "单体电池电压最小值";
CM_ SG_ 384 M8_CellVoltageMax "单体电池电压最大值";
CM_ SG_ 400 M9_Tem_Min "温度最小值";
CM_ SG_ 400 M9_Tem_Max "温度最大值";
CM_ SG_ 400 M9_CellVoltageMin "单体电池电压最小值";
CM_ SG_ 400 M9_CellVoltageMax "单体电池电压最大值";
CM_ SG_ 368 M7_Tem_Min "温度最小值";
CM_ SG_ 368 M7_Tem_Max "温度最大值";
CM_ SG_ 368 M7_CellVoltageMin "单体电池电压最小值";
CM_ SG_ 368 M7_CellVoltageMax "单体电池电压最大值";
CM_ SG_ 352 M6_Tem_Min "温度最小值";
CM_ SG_ 352 M6_Tem_Max "温度最大值";
CM_ SG_ 352 M6_CellVoltageMin "单体电池电压最小值";
CM_ SG_ 352 M6_CellVoltageMax "单体电池电压最大值";
CM_ SG_ 336 M5_Tem_Min "温度最小值";
CM_ SG_ 336 M5_Tem_Max "温度最大值";
CM_ SG_ 336 M5_CellVoltageMin "单体电池电压最小值";
CM_ SG_ 336 M5_CellVoltageMax "单体电池电压最大值";
CM_ SG_ 320 M4_Tem_Min "温度最小值";
CM_ SG_ 320 M4_Tem_Max "温度最大值";
CM_ SG_ 320 M4_CellVoltageMin "单体电池电压最小值";
CM_ SG_ 320 M4_CellVoltageMax "单体电池电压最大值";
CM_ SG_ 304 M3_Tem_Min "温度最小值";
CM_ SG_ 304 M3_Tem_Max "温度最大值";
CM_ SG_ 304 M3_CellVoltageMin "单体电池电压最小值";
CM_ SG_ 304 M3_CellVoltageMax "单体电池电压最大值";
CM_ SG_ 288 M2_Tem_Min "温度最小值";
CM_ SG_ 288 M2_Tem_Max "温度最大值";
CM_ SG_ 288 M2_CellVoltageMin "单体电池电压最小值";
CM_ SG_ 288 M2_CellVoltageMax "单体电池电压最大值";
CM_ SG_ 280 M1_Tem8 "温度值";
CM_ SG_ 280 M1_Tem7 "温度值";
CM_ SG_ 280 M1_Tem6 "温度值";
CM_ SG_ 280 M1_Tem5 "温度值";
CM_ SG_ 279 M1_Tem4 "温度值";
CM_ SG_ 279 M1_Tem3 "温度值";
CM_ SG_ 279 M1_Tem2 "温度值";
CM_ SG_ 279 M1_Tem1 "温度值";
CM_ SG_ 278 M1_CellVoltage9 "单体电池电压值";
CM_ SG_ 278 M1_CellVoltage10 "单体电池电压值";
CM_ SG_ 278 M1_CellVoltage11 "单体电池电压值";
CM_ SG_ 278 M1_CellVoltage12 "单体电池电压值";
CM_ SG_ 277 M1_CellVoltage5 "单体电池电压值";
CM_ SG_ 277 M1_CellVoltage6 "单体电池电压值";
CM_ SG_ 277 M1_CellVoltage8 "单体电池电压值";
CM_ SG_ 277 M1_CellVoltage7 "单体电池电压值";
CM_ SG_ 276 M1_CellVoltage4 "单体电池电压值";
CM_ SG_ 276 M1_CellVoltage3 "单体电池电压值";
CM_ SG_ 276 M1_CellVoltage2 "单体电池电压值";
CM_ SG_ 276 M1_CellVoltage1 "单体电池电压值";
CM_ SG_ 272 M1_Tem_Min "温度最小值";
CM_ SG_ 272 M1_Tem_Max "温度最大值";
CM_ SG_ 272 M1_CellVoltageMin "单体电池电压最小值";
CM_ SG_ 272 M1_CellVoltageMax "单体电池电压最大值";
BA_DEF_ SG_  "GenSigStartValue" FLOAT 0 0;
BA_DEF_ SG_  "GenSigSendType" ENUM  "NotUsed","NotUsed","NotUsed","NotUsed","OnChangeWithRepetition","NotUsed","IfActiveWithRepetition","NoSigSendType","NotUsed","NotUsed";
BA_DEF_ BO_  "GenMsgCycleTime" INT 0 65535;
BA_DEF_ BO_  "GenMsgILSupport" ENUM  "No","Yes";
BA_DEF_ BO_  "GenMsgSendType" ENUM  "Cyclic","NotUsed","NotUsed","NotUsed","NotUsed","NotUsed","NotUsed","NotUsed","NoMsgSendType","NotUsed","vector_leerstring";
BA_DEF_DEF_  "GenSigStartValue" 0;
BA_DEF_DEF_  "GenSigSendType" "NoSigSendType";
BA_DEF_DEF_  "GenMsgCycleTime" 0;
BA_DEF_DEF_  "GenMsgILSupport" "Yes";
BA_DEF_DEF_  "GenMsgSendType" "NoMsgSendType";
BA_ "GenMsgCycleTime" BO_ 608 100;
BA_ "GenMsgSendType" BO_ 608 0;
BA_ "GenMsgCycleTime" BO_ 624 100;
BA_ "GenMsgSendType" BO_ 624 0;
BA_ "GenMsgCycleTime" BO_ 640 100;
BA_ "GenMsgSendType" BO_ 640 0;
BA_ "GenMsgCycleTime" BO_ 656 100;
BA_ "GenMsgSendType" BO_ 656 0;
BA_ "GenMsgCycleTime" BO_ 672 100;
BA_ "GenMsgSendType" BO_ 672 0;
BA_ "GenMsgCycleTime" BO_ 688 100;
BA_ "GenMsgSendType" BO_ 688 0;
BA_ "GenMsgCycleTime" BO_ 704 100;
BA_ "GenMsgSendType" BO_ 704 0;
BA_ "GenMsgCycleTime" BO_ 283 1000;
BA_ "GenMsgSendType" BO_ 283 0;
BA_ "GenMsgCycleTime" BO_ 282 1000;
BA_ "GenMsgSendType" BO_ 282 0;
BA_ "GenMsgCycleTime" BO_ 496 100;
BA_ "GenMsgSendType" BO_ 496 0;
BA_ "GenMsgCycleTime" BO_ 480 100;
BA_ "GenMsgSendType" BO_ 480 0;
BA_ "GenMsgCycleTime" BO_ 464 100;
BA_ "GenMsgSendType" BO_ 464 0;
BA_ "GenMsgCycleTime" BO_ 448 100;
BA_ "GenMsgSendType" BO_ 448 0;
BA_ "GenMsgCycleTime" BO_ 329 1000;
BA_ "GenMsgSendType" BO_ 329 0;
BA_ "GenMsgCycleTime" BO_ 313 1000;
BA_ "GenMsgSendType" BO_ 313 0;
BA_ "GenMsgCycleTime" BO_ 297 1000;
BA_ "GenMsgSendType" BO_ 297 0;
BA_ "GenMsgCycleTime" BO_ 281 1000;
BA_ "GenMsgSendType" BO_ 281 0;
BA_ "GenMsgCycleTime" BO_ 432 100;
BA_ "GenMsgSendType" BO_ 432 0;
BA_ "GenMsgSendType" BO_ 416 0;
BA_ "GenMsgCycleTime" BO_ 416 100;
BA_ "GenMsgCycleTime" BO_ 328 1000;
BA_ "GenMsgSendType" BO_ 328 0;
BA_ "GenMsgCycleTime" BO_ 327 1000;
BA_ "GenMsgSendType" BO_ 327 0;
BA_ "GenMsgCycleTime" BO_ 326 1000;
BA_ "GenMsgSendType" BO_ 326 0;
BA_ "GenMsgCycleTime" BO_ 325 1000;
BA_ "GenMsgSendType" BO_ 325 0;
BA_ "GenMsgCycleTime" BO_ 324 1000;
BA_ "GenMsgSendType" BO_ 324 0;
BA_ "GenMsgCycleTime" BO_ 312 1000;
BA_ "GenMsgSendType" BO_ 312 0;
BA_ "GenMsgCycleTime" BO_ 311 1000;
BA_ "GenMsgSendType" BO_ 311 0;
BA_ "GenMsgCycleTime" BO_ 310 1000;
BA_ "GenMsgSendType" BO_ 310 0;
BA_ "GenMsgCycleTime" BO_ 309 1000;
BA_ "GenMsgSendType" BO_ 309 0;
BA_ "GenMsgCycleTime" BO_ 308 1000;
BA_ "GenMsgSendType" BO_ 308 0;
BA_ "GenMsgCycleTime" BO_ 296 1000;
BA_ "GenMsgSendType" BO_ 296 0;
BA_ "GenMsgCycleTime" BO_ 295 1000;
BA_ "GenMsgSendType" BO_ 295 0;
BA_ "GenMsgCycleTime" BO_ 294 1000;
BA_ "GenMsgSendType" BO_ 294 0;
BA_ "GenMsgCycleTime" BO_ 293 1000;
BA_ "GenMsgSendType" BO_ 293 0;
BA_ "GenMsgCycleTime" BO_ 292 1000;
BA_ "GenMsgSendType" BO_ 292 0;
BA_ "GenMsgCycleTime" BO_ 384 100;
BA_ "GenMsgSendType" BO_ 384 0;
BA_ "GenMsgCycleTime" BO_ 400 100;
BA_ "GenMsgSendType" BO_ 400 0;
BA_ "GenMsgCycleTime" BO_ 368 100;
BA_ "GenMsgSendType" BO_ 368 0;
BA_ "GenMsgCycleTime" BO_ 352 100;
BA_ "GenMsgSendType" BO_ 352 0;
BA_ "GenMsgCycleTime" BO_ 336 100;
BA_ "GenMsgSendType" BO_ 336 0;
BA_ "GenMsgCycleTime" BO_ 320 100;
BA_ "GenMsgSendType" BO_ 320 0;
BA_ "GenMsgCycleTime" BO_ 304 100;
BA_ "GenMsgSendType" BO_ 304 0;
BA_ "GenMsgCycleTime" BO_ 288 100;
BA_ "GenMsgSendType" BO_ 288 0;
BA_ "GenMsgCycleTime" BO_ 280 1000;
BA_ "GenMsgSendType" BO_ 280 0;
BA_ "GenMsgCycleTime" BO_ 279 1000;
BA_ "GenMsgSendType" BO_ 279 0;
BA_ "GenMsgCycleTime" BO_ 278 1000;
BA_ "GenMsgSendType" BO_ 278 0;
BA_ "GenMsgCycleTime" BO_ 277 1000;
BA_ "GenMsgSendType" BO_ 277 0;
BA_ "GenMsgCycleTime" BO_ 276 1000;
BA_ "GenMsgSendType" BO_ 276 0;
BA_ "GenMsgCycleTime" BO_ 272 100;
BA_ "GenMsgSendType" BO_ 272 0;
VAL_ 633 Lecu_Version1 86 "V" ;
VAL_ 633 Lecu_Version0 76 "L" ;
VAL_ 633 M23_CellBalance24 1 "on" 0 "off" ;
VAL_ 633 M23_CellBalance23 1 "on" 0 "off" ;
VAL_ 633 M23_CellBalance22 1 "on" 0 "off" ;
VAL_ 633 M23_CellBalance21 1 "on" 0 "off" ;
VAL_ 633 M23_CellBalance20 1 "on" 0 "off" ;
VAL_ 633 M23_CellBalance19 1 "on" 0 "off" ;
VAL_ 633 M23_CellBalance18 1 "on" 0 "off" ;
VAL_ 633 M23_CellBalance17 1 "on" 0 "off" ;
VAL_ 633 M23_CellBalance16 1 "on" 0 "off" ;
VAL_ 633 M23_CellBalance15 1 "on" 0 "off" ;
VAL_ 633 M23_CellBalance14 1 "on" 0 "off" ;
VAL_ 633 M23_CellBalance13 1 "on" 0 "off" ;
VAL_ 633 M23_CellBalance9 1 "on" 0 "off" ;
VAL_ 633 M23_CellBalance8 1 "on" 0 "off" ;
VAL_ 633 M23_CellBalance7 1 "on" 0 "off" ;
VAL_ 633 M23_CellBalance6 1 "on" 0 "off" ;
VAL_ 633 M23_CellBalance5 1 "on" 0 "off" ;
VAL_ 633 M23_CellBalance4 1 "on" 0 "off" ;
VAL_ 633 M23_CellBalance3 1 "on" 0 "off" ;
VAL_ 633 M23_CellBalance2 1 "on" 0 "off" ;
VAL_ 633 M23_CellBalance12 1 "on" 0 "off" ;
VAL_ 633 M23_CellBalance11 1 "on" 0 "off" ;
VAL_ 633 M23_CellBalance10 1 "on" 0 "off" ;
VAL_ 633 M23_CellBalance1 1 "on" 0 "off" ;
VAL_ 649 Lecu_Version1 86 "V" ;
VAL_ 649 Lecu_Version0 76 "L" ;
VAL_ 649 M24_CellBalance24 1 "on" 0 "off" ;
VAL_ 649 M24_CellBalance23 1 "on" 0 "off" ;
VAL_ 649 M24_CellBalance22 1 "on" 0 "off" ;
VAL_ 649 M24_CellBalance21 1 "on" 0 "off" ;
VAL_ 649 M24_CellBalance20 1 "on" 0 "off" ;
VAL_ 649 M24_CellBalance19 1 "on" 0 "off" ;
VAL_ 649 M24_CellBalance18 1 "on" 0 "off" ;
VAL_ 649 M24_CellBalance17 1 "on" 0 "off" ;
VAL_ 649 M24_CellBalance16 1 "on" 0 "off" ;
VAL_ 649 M24_CellBalance15 1 "on" 0 "off" ;
VAL_ 649 M24_CellBalance14 1 "on" 0 "off" ;
VAL_ 649 M24_CellBalance13 1 "on" 0 "off" ;
VAL_ 649 M24_CellBalance9 1 "on" 0 "off" ;
VAL_ 649 M24_CellBalance8 1 "on" 0 "off" ;
VAL_ 649 M24_CellBalance7 1 "on" 0 "off" ;
VAL_ 649 M24_CellBalance6 1 "on" 0 "off" ;
VAL_ 649 M24_CellBalance5 1 "on" 0 "off" ;
VAL_ 649 M24_CellBalance4 1 "on" 0 "off" ;
VAL_ 649 M24_CellBalance3 1 "on" 0 "off" ;
VAL_ 649 M24_CellBalance2 1 "on" 0 "off" ;
VAL_ 649 M24_CellBalance12 1 "on" 0 "off" ;
VAL_ 649 M24_CellBalance11 1 "on" 0 "off" ;
VAL_ 649 M24_CellBalance10 1 "on" 0 "off" ;
VAL_ 649 M24_CellBalance1 1 "on" 0 "off" ;
VAL_ 665 Lecu_Version1 86 "V" ;
VAL_ 665 Lecu_Version0 76 "L" ;
VAL_ 665 M25_CellBalance24 1 "on" 0 "off" ;
VAL_ 665 M25_CellBalance23 1 "on" 0 "off" ;
VAL_ 665 M25_CellBalance22 1 "on" 0 "off" ;
VAL_ 665 M25_CellBalance21 1 "on" 0 "off" ;
VAL_ 665 M25_CellBalance20 1 "on" 0 "off" ;
VAL_ 665 M25_CellBalance19 1 "on" 0 "off" ;
VAL_ 665 M25_CellBalance18 1 "on" 0 "off" ;
VAL_ 665 M25_CellBalance17 1 "on" 0 "off" ;
VAL_ 665 M25_CellBalance16 1 "on" 0 "off" ;
VAL_ 665 M25_CellBalance15 1 "on" 0 "off" ;
VAL_ 665 M25_CellBalance14 1 "on" 0 "off" ;
VAL_ 665 M25_CellBalance13 1 "on" 0 "off" ;
VAL_ 665 M25_CellBalance9 1 "on" 0 "off" ;
VAL_ 665 M25_CellBalance8 1 "on" 0 "off" ;
VAL_ 665 M25_CellBalance7 1 "on" 0 "off" ;
VAL_ 665 M25_CellBalance6 1 "on" 0 "off" ;
VAL_ 665 M25_CellBalance5 1 "on" 0 "off" ;
VAL_ 665 M25_CellBalance4 1 "on" 0 "off" ;
VAL_ 665 M25_CellBalance3 1 "on" 0 "off" ;
VAL_ 665 M25_CellBalance2 1 "on" 0 "off" ;
VAL_ 665 M25_CellBalance12 1 "on" 0 "off" ;
VAL_ 665 M25_CellBalance11 1 "on" 0 "off" ;
VAL_ 665 M25_CellBalance10 1 "on" 0 "off" ;
VAL_ 665 M25_CellBalance1 1 "on" 0 "off" ;
VAL_ 681 Lecu_Version1 86 "V" ;
VAL_ 681 Lecu_Version0 76 "L" ;
VAL_ 681 M26_CellBalance24 1 "on" 0 "off" ;
VAL_ 681 M26_CellBalance23 1 "on" 0 "off" ;
VAL_ 681 M26_CellBalance22 1 "on" 0 "off" ;
VAL_ 681 M26_CellBalance21 1 "on" 0 "off" ;
VAL_ 681 M26_CellBalance20 1 "on" 0 "off" ;
VAL_ 681 M26_CellBalance19 1 "on" 0 "off" ;
VAL_ 681 M26_CellBalance18 1 "on" 0 "off" ;
VAL_ 681 M26_CellBalance17 1 "on" 0 "off" ;
VAL_ 681 M26_CellBalance16 1 "on" 0 "off" ;
VAL_ 681 M26_CellBalance15 1 "on" 0 "off" ;
VAL_ 681 M26_CellBalance14 1 "on" 0 "off" ;
VAL_ 681 M26_CellBalance13 1 "on" 0 "off" ;
VAL_ 681 M26_CellBalance9 1 "on" 0 "off" ;
VAL_ 681 M26_CellBalance8 1 "on" 0 "off" ;
VAL_ 681 M26_CellBalance7 1 "on" 0 "off" ;
VAL_ 681 M26_CellBalance6 1 "on" 0 "off" ;
VAL_ 681 M26_CellBalance5 1 "on" 0 "off" ;
VAL_ 681 M26_CellBalance4 1 "on" 0 "off" ;
VAL_ 681 M26_CellBalance3 1 "on" 0 "off" ;
VAL_ 681 M26_CellBalance2 1 "on" 0 "off" ;
VAL_ 681 M26_CellBalance12 1 "on" 0 "off" ;
VAL_ 681 M26_CellBalance11 1 "on" 0 "off" ;
VAL_ 681 M26_CellBalance10 1 "on" 0 "off" ;
VAL_ 681 M26_CellBalance1 1 "on" 0 "off" ;
VAL_ 697 Lecu_Version1 86 "V" ;
VAL_ 697 Lecu_Version0 76 "L" ;
VAL_ 697 M27_CellBalance24 1 "on" 0 "off" ;
VAL_ 697 M27_CellBalance23 1 "on" 0 "off" ;
VAL_ 697 M27_CellBalance22 1 "on" 0 "off" ;
VAL_ 697 M27_CellBalance21 1 "on" 0 "off" ;
VAL_ 697 M27_CellBalance20 1 "on" 0 "off" ;
VAL_ 697 M27_CellBalance19 1 "on" 0 "off" ;
VAL_ 697 M27_CellBalance18 1 "on" 0 "off" ;
VAL_ 697 M27_CellBalance17 1 "on" 0 "off" ;
VAL_ 697 M27_CellBalance16 1 "on" 0 "off" ;
VAL_ 697 M27_CellBalance15 1 "on" 0 "off" ;
VAL_ 697 M27_CellBalance14 1 "on" 0 "off" ;
VAL_ 697 M27_CellBalance13 1 "on" 0 "off" ;
VAL_ 697 M27_CellBalance9 1 "on" 0 "off" ;
VAL_ 697 M27_CellBalance8 1 "on" 0 "off" ;
VAL_ 697 M27_CellBalance7 1 "on" 0 "off" ;
VAL_ 697 M27_CellBalance6 1 "on" 0 "off" ;
VAL_ 697 M27_CellBalance5 1 "on" 0 "off" ;
VAL_ 697 M27_CellBalance4 1 "on" 0 "off" ;
VAL_ 697 M27_CellBalance3 1 "on" 0 "off" ;
VAL_ 697 M27_CellBalance2 1 "on" 0 "off" ;
VAL_ 697 M27_CellBalance12 1 "on" 0 "off" ;
VAL_ 697 M27_CellBalance11 1 "on" 0 "off" ;
VAL_ 697 M27_CellBalance10 1 "on" 0 "off" ;
VAL_ 697 M27_CellBalance1 1 "on" 0 "off" ;
VAL_ 713 Lecu_Version1 86 "V" ;
VAL_ 713 Lecu_Version0 76 "L" ;
VAL_ 713 M28_CellBalance24 1 "on" 0 "off" ;
VAL_ 713 M28_CellBalance23 1 "on" 0 "off" ;
VAL_ 713 M28_CellBalance22 1 "on" 0 "off" ;
VAL_ 713 M28_CellBalance21 1 "on" 0 "off" ;
VAL_ 713 M28_CellBalance20 1 "on" 0 "off" ;
VAL_ 713 M28_CellBalance19 1 "on" 0 "off" ;
VAL_ 713 M28_CellBalance18 1 "on" 0 "off" ;
VAL_ 713 M28_CellBalance17 1 "on" 0 "off" ;
VAL_ 713 M28_CellBalance16 1 "on" 0 "off" ;
VAL_ 713 M28_CellBalance15 1 "on" 0 "off" ;
VAL_ 713 M28_CellBalance14 1 "on" 0 "off" ;
VAL_ 713 M28_CellBalance13 1 "on" 0 "off" ;
VAL_ 713 M28_CellBalance9 1 "on" 0 "off" ;
VAL_ 713 M28_CellBalance8 1 "on" 0 "off" ;
VAL_ 713 M28_CellBalance7 1 "on" 0 "off" ;
VAL_ 713 M28_CellBalance6 1 "on" 0 "off" ;
VAL_ 713 M28_CellBalance5 1 "on" 0 "off" ;
VAL_ 713 M28_CellBalance4 1 "on" 0 "off" ;
VAL_ 713 M28_CellBalance3 1 "on" 0 "off" ;
VAL_ 713 M28_CellBalance2 1 "on" 0 "off" ;
VAL_ 713 M28_CellBalance12 1 "on" 0 "off" ;
VAL_ 713 M28_CellBalance11 1 "on" 0 "off" ;
VAL_ 713 M28_CellBalance10 1 "on" 0 "off" ;
VAL_ 713 M28_CellBalance1 1 "on" 0 "off" ;
VAL_ 729 Lecu_Version1 86 "V" ;
VAL_ 729 Lecu_Version0 76 "L" ;
VAL_ 729 M29_CellBalance24 1 "on" 0 "off" ;
VAL_ 729 M29_CellBalance23 1 "on" 0 "off" ;
VAL_ 729 M29_CellBalance22 1 "on" 0 "off" ;
VAL_ 729 M29_CellBalance21 1 "on" 0 "off" ;
VAL_ 729 M29_CellBalance20 1 "on" 0 "off" ;
VAL_ 729 M29_CellBalance19 1 "on" 0 "off" ;
VAL_ 729 M29_CellBalance18 1 "on" 0 "off" ;
VAL_ 729 M29_CellBalance17 1 "on" 0 "off" ;
VAL_ 729 M29_CellBalance16 1 "on" 0 "off" ;
VAL_ 729 M29_CellBalance15 1 "on" 0 "off" ;
VAL_ 729 M29_CellBalance14 1 "on" 0 "off" ;
VAL_ 729 M29_CellBalance13 1 "on" 0 "off" ;
VAL_ 729 M29_CellBalance9 1 "on" 0 "off" ;
VAL_ 729 M29_CellBalance8 1 "on" 0 "off" ;
VAL_ 729 M29_CellBalance7 1 "on" 0 "off" ;
VAL_ 729 M29_CellBalance6 1 "on" 0 "off" ;
VAL_ 729 M29_CellBalance5 1 "on" 0 "off" ;
VAL_ 729 M29_CellBalance4 1 "on" 0 "off" ;
VAL_ 729 M29_CellBalance3 1 "on" 0 "off" ;
VAL_ 729 M29_CellBalance2 1 "on" 0 "off" ;
VAL_ 729 M29_CellBalance12 1 "on" 0 "off" ;
VAL_ 729 M29_CellBalance11 1 "on" 0 "off" ;
VAL_ 729 M29_CellBalance10 1 "on" 0 "off" ;
VAL_ 729 M29_CellBalance1 1 "on" 0 "off" ;
VAL_ 745 Lecu_Version1 86 "V" ;
VAL_ 745 Lecu_Version0 76 "L" ;
VAL_ 745 M30_CellBalance24 1 "on" 0 "off" ;
VAL_ 745 M30_CellBalance23 1 "on" 0 "off" ;
VAL_ 745 M30_CellBalance22 1 "on" 0 "off" ;
VAL_ 745 M30_CellBalance21 1 "on" 0 "off" ;
VAL_ 745 M30_CellBalance20 1 "on" 0 "off" ;
VAL_ 745 M30_CellBalance19 1 "on" 0 "off" ;
VAL_ 745 M30_CellBalance18 1 "on" 0 "off" ;
VAL_ 745 M30_CellBalance17 1 "on" 0 "off" ;
VAL_ 745 M30_CellBalance16 1 "on" 0 "off" ;
VAL_ 745 M30_CellBalance15 1 "on" 0 "off" ;
VAL_ 745 M30_CellBalance14 1 "on" 0 "off" ;
VAL_ 745 M30_CellBalance13 1 "on" 0 "off" ;
VAL_ 745 M30_CellBalance9 1 "on" 0 "off" ;
VAL_ 745 M30_CellBalance8 1 "on" 0 "off" ;
VAL_ 745 M30_CellBalance7 1 "on" 0 "off" ;
VAL_ 745 M30_CellBalance6 1 "on" 0 "off" ;
VAL_ 745 M30_CellBalance5 1 "on" 0 "off" ;
VAL_ 745 M30_CellBalance4 1 "on" 0 "off" ;
VAL_ 745 M30_CellBalance3 1 "on" 0 "off" ;
VAL_ 745 M30_CellBalance2 1 "on" 0 "off" ;
VAL_ 745 M30_CellBalance12 1 "on" 0 "off" ;
VAL_ 745 M30_CellBalance11 1 "on" 0 "off" ;
VAL_ 745 M30_CellBalance10 1 "on" 0 "off" ;
VAL_ 745 M30_CellBalance1 1 "on" 0 "off" ;
VAL_ 761 Lecu_Version1 86 "V" ;
VAL_ 761 Lecu_Version0 76 "L" ;
VAL_ 761 M31_CellBalance24 1 "on" 0 "off" ;
VAL_ 761 M31_CellBalance23 1 "on" 0 "off" ;
VAL_ 761 M31_CellBalance22 1 "on" 0 "off" ;
VAL_ 761 M31_CellBalance21 1 "on" 0 "off" ;
VAL_ 761 M31_CellBalance20 1 "on" 0 "off" ;
VAL_ 761 M31_CellBalance19 1 "on" 0 "off" ;
VAL_ 761 M31_CellBalance18 1 "on" 0 "off" ;
VAL_ 761 M31_CellBalance17 1 "on" 0 "off" ;
VAL_ 761 M31_CellBalance16 1 "on" 0 "off" ;
VAL_ 761 M31_CellBalance15 1 "on" 0 "off" ;
VAL_ 761 M31_CellBalance14 1 "on" 0 "off" ;
VAL_ 761 M31_CellBalance13 1 "on" 0 "off" ;
VAL_ 761 M31_CellBalance9 1 "on" 0 "off" ;
VAL_ 761 M31_CellBalance8 1 "on" 0 "off" ;
VAL_ 761 M31_CellBalance7 1 "on" 0 "off" ;
VAL_ 761 M31_CellBalance6 1 "on" 0 "off" ;
VAL_ 761 M31_CellBalance5 1 "on" 0 "off" ;
VAL_ 761 M31_CellBalance4 1 "on" 0 "off" ;
VAL_ 761 M31_CellBalance3 1 "on" 0 "off" ;
VAL_ 761 M31_CellBalance2 1 "on" 0 "off" ;
VAL_ 761 M31_CellBalance12 1 "on" 0 "off" ;
VAL_ 761 M31_CellBalance11 1 "on" 0 "off" ;
VAL_ 761 M31_CellBalance10 1 "on" 0 "off" ;
VAL_ 761 M31_CellBalance1 1 "on" 0 "off" ;
VAL_ 505 Lecu_Version1 86 "V" ;
VAL_ 505 Lecu_Version0 76 "L" ;
VAL_ 505 M15_CellBalance24 1 "on" 0 "off" ;
VAL_ 505 M15_CellBalance23 1 "on" 0 "off" ;
VAL_ 505 M15_CellBalance22 1 "on" 0 "off" ;
VAL_ 505 M15_CellBalance21 1 "on" 0 "off" ;
VAL_ 505 M15_CellBalance20 1 "on" 0 "off" ;
VAL_ 505 M15_CellBalance19 1 "on" 0 "off" ;
VAL_ 505 M15_CellBalance18 1 "on" 0 "off" ;
VAL_ 505 M15_CellBalance17 1 "on" 0 "off" ;
VAL_ 505 M15_CellBalance16 1 "on" 0 "off" ;
VAL_ 505 M15_CellBalance15 1 "on" 0 "off" ;
VAL_ 505 M15_CellBalance14 1 "on" 0 "off" ;
VAL_ 505 M15_CellBalance13 1 "on" 0 "off" ;
VAL_ 505 M15_CellBalance9 1 "on" 0 "off" ;
VAL_ 505 M15_CellBalance8 1 "on" 0 "off" ;
VAL_ 505 M15_CellBalance7 1 "on" 0 "off" ;
VAL_ 505 M15_CellBalance6 1 "on" 0 "off" ;
VAL_ 505 M15_CellBalance5 1 "on" 0 "off" ;
VAL_ 505 M15_CellBalance4 1 "on" 0 "off" ;
VAL_ 505 M15_CellBalance3 1 "on" 0 "off" ;
VAL_ 505 M15_CellBalance2 1 "on" 0 "off" ;
VAL_ 505 M15_CellBalance12 1 "on" 0 "off" ;
VAL_ 505 M15_CellBalance11 1 "on" 0 "off" ;
VAL_ 505 M15_CellBalance10 1 "on" 0 "off" ;
VAL_ 505 M15_CellBalance1 1 "on" 0 "off" ;
VAL_ 489 Lecu_Version1 86 "V" ;
VAL_ 489 Lecu_Version0 76 "L" ;
VAL_ 489 M14_CellBalance24 1 "on" 0 "off" ;
VAL_ 489 M14_CellBalance23 1 "on" 0 "off" ;
VAL_ 489 M14_CellBalance22 1 "on" 0 "off" ;
VAL_ 489 M14_CellBalance21 1 "on" 0 "off" ;
VAL_ 489 M14_CellBalance20 1 "on" 0 "off" ;
VAL_ 489 M14_CellBalance19 1 "on" 0 "off" ;
VAL_ 489 M14_CellBalance18 1 "on" 0 "off" ;
VAL_ 489 M14_CellBalance17 1 "on" 0 "off" ;
VAL_ 489 M14_CellBalance16 1 "on" 0 "off" ;
VAL_ 489 M14_CellBalance15 1 "on" 0 "off" ;
VAL_ 489 M14_CellBalance14 1 "on" 0 "off" ;
VAL_ 489 M14_CellBalance13 1 "on" 0 "off" ;
VAL_ 489 M14_CellBalance9 1 "on" 0 "off" ;
VAL_ 489 M14_CellBalance8 1 "on" 0 "off" ;
VAL_ 489 M14_CellBalance7 1 "on" 0 "off" ;
VAL_ 489 M14_CellBalance6 1 "on" 0 "off" ;
VAL_ 489 M14_CellBalance5 1 "on" 0 "off" ;
VAL_ 489 M14_CellBalance4 1 "on" 0 "off" ;
VAL_ 489 M14_CellBalance3 1 "on" 0 "off" ;
VAL_ 489 M14_CellBalance2 1 "on" 0 "off" ;
VAL_ 489 M14_CellBalance12 1 "on" 0 "off" ;
VAL_ 489 M14_CellBalance11 1 "on" 0 "off" ;
VAL_ 489 M14_CellBalance10 1 "on" 0 "off" ;
VAL_ 489 M14_CellBalance1 1 "on" 0 "off" ;
VAL_ 361 Lecu_Version1 86 "V" ;
VAL_ 361 Lecu_Version0 76 "L" ;
VAL_ 361 M6_CellBalance24 1 "on" 0 "off" ;
VAL_ 361 M6_CellBalance23 1 "on" 0 "off" ;
VAL_ 361 M6_CellBalance22 1 "on" 0 "off" ;
VAL_ 361 M6_CellBalance21 1 "on" 0 "off" ;
VAL_ 361 M6_CellBalance20 1 "on" 0 "off" ;
VAL_ 361 M6_CellBalance19 1 "on" 0 "off" ;
VAL_ 361 M6_CellBalance18 1 "on" 0 "off" ;
VAL_ 361 M6_CellBalance17 1 "on" 0 "off" ;
VAL_ 361 M6_CellBalance16 1 "on" 0 "off" ;
VAL_ 361 M6_CellBalance15 1 "on" 0 "off" ;
VAL_ 361 M6_CellBalance14 1 "on" 0 "off" ;
VAL_ 361 M6_CellBalance13 1 "on" 0 "off" ;
VAL_ 361 M6_CellBalance9 1 "on" 0 "off" ;
VAL_ 361 M6_CellBalance8 1 "on" 0 "off" ;
VAL_ 361 M6_CellBalance7 1 "on" 0 "off" ;
VAL_ 361 M6_CellBalance6 1 "on" 0 "off" ;
VAL_ 361 M6_CellBalance5 1 "on" 0 "off" ;
VAL_ 361 M6_CellBalance4 1 "on" 0 "off" ;
VAL_ 361 M6_CellBalance3 1 "on" 0 "off" ;
VAL_ 361 M6_CellBalance2 1 "on" 0 "off" ;
VAL_ 361 M6_CellBalance12 1 "on" 0 "off" ;
VAL_ 361 M6_CellBalance11 1 "on" 0 "off" ;
VAL_ 361 M6_CellBalance10 1 "on" 0 "off" ;
VAL_ 361 M6_CellBalance1 1 "on" 0 "off" ;
VAL_ 473 Lecu_Version1 86 "V" ;
VAL_ 473 Lecu_Version0 76 "L" ;
VAL_ 473 M13_CellBalance24 1 "on" 0 "off" ;
VAL_ 473 M13_CellBalance23 1 "on" 0 "off" ;
VAL_ 473 M13_CellBalance22 1 "on" 0 "off" ;
VAL_ 473 M13_CellBalance21 1 "on" 0 "off" ;
VAL_ 473 M13_CellBalance20 1 "on" 0 "off" ;
VAL_ 473 M13_CellBalance19 1 "on" 0 "off" ;
VAL_ 473 M13_CellBalance18 1 "on" 0 "off" ;
VAL_ 473 M13_CellBalance17 1 "on" 0 "off" ;
VAL_ 473 M13_CellBalance16 1 "on" 0 "off" ;
VAL_ 473 M13_CellBalance15 1 "on" 0 "off" ;
VAL_ 473 M13_CellBalance14 1 "on" 0 "off" ;
VAL_ 473 M13_CellBalance13 1 "on" 0 "off" ;
VAL_ 473 M13_CellBalance9 1 "on" 0 "off" ;
VAL_ 473 M13_CellBalance8 1 "on" 0 "off" ;
VAL_ 473 M13_CellBalance7 1 "on" 0 "off" ;
VAL_ 473 M13_CellBalance6 1 "on" 0 "off" ;
VAL_ 473 M13_CellBalance5 1 "on" 0 "off" ;
VAL_ 473 M13_CellBalance4 1 "on" 0 "off" ;
VAL_ 473 M13_CellBalance3 1 "on" 0 "off" ;
VAL_ 473 M13_CellBalance2 1 "on" 0 "off" ;
VAL_ 473 M13_CellBalance12 1 "on" 0 "off" ;
VAL_ 473 M13_CellBalance11 1 "on" 0 "off" ;
VAL_ 473 M13_CellBalance10 1 "on" 0 "off" ;
VAL_ 473 M13_CellBalance1 1 "on" 0 "off" ;
VAL_ 457 Lecu_Version1 86 "V" ;
VAL_ 457 Lecu_Version0 76 "L" ;
VAL_ 457 M12_CellBalance24 1 "on" 0 "off" ;
VAL_ 457 M12_CellBalance23 1 "on" 0 "off" ;
VAL_ 457 M12_CellBalance22 1 "on" 0 "off" ;
VAL_ 457 M12_CellBalance21 1 "on" 0 "off" ;
VAL_ 457 M12_CellBalance20 1 "on" 0 "off" ;
VAL_ 457 M12_CellBalance19 1 "on" 0 "off" ;
VAL_ 457 M12_CellBalance18 1 "on" 0 "off" ;
VAL_ 457 M12_CellBalance17 1 "on" 0 "off" ;
VAL_ 457 M12_CellBalance16 1 "on" 0 "off" ;
VAL_ 457 M12_CellBalance15 1 "on" 0 "off" ;
VAL_ 457 M12_CellBalance14 1 "on" 0 "off" ;
VAL_ 457 M12_CellBalance13 1 "on" 0 "off" ;
VAL_ 457 M12_CellBalance9 1 "on" 0 "off" ;
VAL_ 457 M12_CellBalance8 1 "on" 0 "off" ;
VAL_ 457 M12_CellBalance7 1 "on" 0 "off" ;
VAL_ 457 M12_CellBalance6 1 "on" 0 "off" ;
VAL_ 457 M12_CellBalance5 1 "on" 0 "off" ;
VAL_ 457 M12_CellBalance4 1 "on" 0 "off" ;
VAL_ 457 M12_CellBalance3 1 "on" 0 "off" ;
VAL_ 457 M12_CellBalance2 1 "on" 0 "off" ;
VAL_ 457 M12_CellBalance12 1 "on" 0 "off" ;
VAL_ 457 M12_CellBalance11 1 "on" 0 "off" ;
VAL_ 457 M12_CellBalance10 1 "on" 0 "off" ;
VAL_ 457 M12_CellBalance1 1 "on" 0 "off" ;
VAL_ 441 Lecu_Version1 86 "V" ;
VAL_ 441 Lecu_Version0 76 "L" ;
VAL_ 441 M11_CellBalance24 1 "on" 0 "off" ;
VAL_ 441 M11_CellBalance23 1 "on" 0 "off" ;
VAL_ 441 M11_CellBalance22 1 "on" 0 "off" ;
VAL_ 441 M11_CellBalance21 1 "on" 0 "off" ;
VAL_ 441 M11_CellBalance20 1 "on" 0 "off" ;
VAL_ 441 M11_CellBalance19 1 "on" 0 "off" ;
VAL_ 441 M11_CellBalance18 1 "on" 0 "off" ;
VAL_ 441 M11_CellBalance17 1 "on" 0 "off" ;
VAL_ 441 M11_CellBalance16 1 "on" 0 "off" ;
VAL_ 441 M11_CellBalance15 1 "on" 0 "off" ;
VAL_ 441 M11_CellBalance14 1 "on" 0 "off" ;
VAL_ 441 M11_CellBalance13 1 "on" 0 "off" ;
VAL_ 441 M11_CellBalance9 1 "on" 0 "off" ;
VAL_ 441 M11_CellBalance8 1 "on" 0 "off" ;
VAL_ 441 M11_CellBalance7 1 "on" 0 "off" ;
VAL_ 441 M11_CellBalance6 1 "on" 0 "off" ;
VAL_ 441 M11_CellBalance5 1 "on" 0 "off" ;
VAL_ 441 M11_CellBalance4 1 "on" 0 "off" ;
VAL_ 441 M11_CellBalance3 1 "on" 0 "off" ;
VAL_ 441 M11_CellBalance2 1 "on" 0 "off" ;
VAL_ 441 M11_CellBalance12 1 "on" 0 "off" ;
VAL_ 441 M11_CellBalance11 1 "on" 0 "off" ;
VAL_ 441 M11_CellBalance10 1 "on" 0 "off" ;
VAL_ 441 M11_CellBalance1 1 "on" 0 "off" ;
VAL_ 425 Lecu_Version1 86 "V" ;
VAL_ 425 Lecu_Version0 76 "L" ;
VAL_ 425 M10_CellBalance24 1 "on" 0 "off" ;
VAL_ 425 M10_CellBalance23 1 "on" 0 "off" ;
VAL_ 425 M10_CellBalance22 1 "on" 0 "off" ;
VAL_ 425 M10_CellBalance21 1 "on" 0 "off" ;
VAL_ 425 M10_CellBalance20 1 "on" 0 "off" ;
VAL_ 425 M10_CellBalance19 1 "on" 0 "off" ;
VAL_ 425 M10_CellBalance18 1 "on" 0 "off" ;
VAL_ 425 M10_CellBalance17 1 "on" 0 "off" ;
VAL_ 425 M10_CellBalance16 1 "on" 0 "off" ;
VAL_ 425 M10_CellBalance15 1 "on" 0 "off" ;
VAL_ 425 M10_CellBalance14 1 "on" 0 "off" ;
VAL_ 425 M10_CellBalance13 1 "on" 0 "off" ;
VAL_ 425 M10_CellBalance9 1 "on" 0 "off" ;
VAL_ 425 M10_CellBalance8 1 "on" 0 "off" ;
VAL_ 425 M10_CellBalance7 1 "on" 0 "off" ;
VAL_ 425 M10_CellBalance6 1 "on" 0 "off" ;
VAL_ 425 M10_CellBalance5 1 "on" 0 "off" ;
VAL_ 425 M10_CellBalance4 1 "on" 0 "off" ;
VAL_ 425 M10_CellBalance3 1 "on" 0 "off" ;
VAL_ 425 M10_CellBalance2 1 "on" 0 "off" ;
VAL_ 425 M10_CellBalance12 1 "on" 0 "off" ;
VAL_ 425 M10_CellBalance11 1 "on" 0 "off" ;
VAL_ 425 M10_CellBalance10 1 "on" 0 "off" ;
VAL_ 425 M10_CellBalance1 1 "on" 0 "off" ;
VAL_ 409 Lecu_Version1 86 "V" ;
VAL_ 409 Lecu_Version0 76 "L" ;
VAL_ 409 M9_CellBalance24 1 "on" 0 "off" ;
VAL_ 409 M9_CellBalance23 1 "on" 0 "off" ;
VAL_ 409 M9_CellBalance22 1 "on" 0 "off" ;
VAL_ 409 M9_CellBalance21 1 "on" 0 "off" ;
VAL_ 409 M9_CellBalance20 1 "on" 0 "off" ;
VAL_ 409 M9_CellBalance19 1 "on" 0 "off" ;
VAL_ 409 M9_CellBalance18 1 "on" 0 "off" ;
VAL_ 409 M9_CellBalance17 1 "on" 0 "off" ;
VAL_ 409 M9_CellBalance16 1 "on" 0 "off" ;
VAL_ 409 M9_CellBalance15 1 "on" 0 "off" ;
VAL_ 409 M9_CellBalance14 1 "on" 0 "off" ;
VAL_ 409 M9_CellBalance13 1 "on" 0 "off" ;
VAL_ 409 M9_CellBalance9 1 "on" 0 "off" ;
VAL_ 409 M9_CellBalance8 1 "on" 0 "off" ;
VAL_ 409 M9_CellBalance7 1 "on" 0 "off" ;
VAL_ 409 M9_CellBalance6 1 "on" 0 "off" ;
VAL_ 409 M9_CellBalance5 1 "on" 0 "off" ;
VAL_ 409 M9_CellBalance4 1 "on" 0 "off" ;
VAL_ 409 M9_CellBalance3 1 "on" 0 "off" ;
VAL_ 409 M9_CellBalance2 1 "on" 0 "off" ;
VAL_ 409 M9_CellBalance12 1 "on" 0 "off" ;
VAL_ 409 M9_CellBalance11 1 "on" 0 "off" ;
VAL_ 409 M9_CellBalance10 1 "on" 0 "off" ;
VAL_ 409 M9_CellBalance1 1 "on" 0 "off" ;
VAL_ 393 Lecu_Version1 86 "V" ;
VAL_ 393 Lecu_Version0 76 "L" ;
VAL_ 393 M8_CellBalance24 1 "on" 0 "off" ;
VAL_ 393 M8_CellBalance23 1 "on" 0 "off" ;
VAL_ 393 M8_CellBalance22 1 "on" 0 "off" ;
VAL_ 393 M8_CellBalance21 1 "on" 0 "off" ;
VAL_ 393 M8_CellBalance20 1 "on" 0 "off" ;
VAL_ 393 M8_CellBalance19 1 "on" 0 "off" ;
VAL_ 393 M8_CellBalance18 1 "on" 0 "off" ;
VAL_ 393 M8_CellBalance17 1 "on" 0 "off" ;
VAL_ 393 M8_CellBalance16 1 "on" 0 "off" ;
VAL_ 393 M8_CellBalance15 1 "on" 0 "off" ;
VAL_ 393 M8_CellBalance14 1 "on" 0 "off" ;
VAL_ 393 M8_CellBalance13 1 "on" 0 "off" ;
VAL_ 393 M8_CellBalance9 1 "on" 0 "off" ;
VAL_ 393 M8_CellBalance8 1 "on" 0 "off" ;
VAL_ 393 M8_CellBalance7 1 "on" 0 "off" ;
VAL_ 393 M8_CellBalance6 1 "on" 0 "off" ;
VAL_ 393 M8_CellBalance5 1 "on" 0 "off" ;
VAL_ 393 M8_CellBalance4 1 "on" 0 "off" ;
VAL_ 393 M8_CellBalance3 1 "on" 0 "off" ;
VAL_ 393 M8_CellBalance2 1 "on" 0 "off" ;
VAL_ 393 M8_CellBalance12 1 "on" 0 "off" ;
VAL_ 393 M8_CellBalance11 1 "on" 0 "off" ;
VAL_ 393 M8_CellBalance10 1 "on" 0 "off" ;
VAL_ 393 M8_CellBalance1 1 "on" 0 "off" ;
VAL_ 377 Lecu_Version1 86 "V" ;
VAL_ 377 Lecu_Version0 76 "L" ;
VAL_ 377 M7_CellBalance24 1 "on" 0 "off" ;
VAL_ 377 M7_CellBalance23 1 "on" 0 "off" ;
VAL_ 377 M7_CellBalance22 1 "on" 0 "off" ;
VAL_ 377 M7_CellBalance21 1 "on" 0 "off" ;
VAL_ 377 M7_CellBalance20 1 "on" 0 "off" ;
VAL_ 377 M7_CellBalance19 1 "on" 0 "off" ;
VAL_ 377 M7_CellBalance18 1 "on" 0 "off" ;
VAL_ 377 M7_CellBalance17 1 "on" 0 "off" ;
VAL_ 377 M7_CellBalance16 1 "on" 0 "off" ;
VAL_ 377 M7_CellBalance15 1 "on" 0 "off" ;
VAL_ 377 M7_CellBalance14 1 "on" 0 "off" ;
VAL_ 377 M7_CellBalance13 1 "on" 0 "off" ;
VAL_ 377 M7_CellBalance9 1 "on" 0 "off" ;
VAL_ 377 M7_CellBalance8 1 "on" 0 "off" ;
VAL_ 377 M7_CellBalance7 1 "on" 0 "off" ;
VAL_ 377 M7_CellBalance6 1 "on" 0 "off" ;
VAL_ 377 M7_CellBalance5 1 "on" 0 "off" ;
VAL_ 377 M7_CellBalance4 1 "on" 0 "off" ;
VAL_ 377 M7_CellBalance3 1 "on" 0 "off" ;
VAL_ 377 M7_CellBalance2 1 "on" 0 "off" ;
VAL_ 377 M7_CellBalance12 1 "on" 0 "off" ;
VAL_ 377 M7_CellBalance11 1 "on" 0 "off" ;
VAL_ 377 M7_CellBalance10 1 "on" 0 "off" ;
VAL_ 377 M7_CellBalance1 1 "on" 0 "off" ;
VAL_ 345 Lecu_Version1 86 "V" ;
VAL_ 345 Lecu_Version0 76 "L" ;
VAL_ 345 M5_CellBalance24 1 "on" 0 "off" ;
VAL_ 345 M5_CellBalance23 1 "on" 0 "off" ;
VAL_ 345 M5_CellBalance22 1 "on" 0 "off" ;
VAL_ 345 M5_CellBalance21 1 "on" 0 "off" ;
VAL_ 345 M5_CellBalance20 1 "on" 0 "off" ;
VAL_ 345 M5_CellBalance19 1 "on" 0 "off" ;
VAL_ 345 M5_CellBalance18 1 "on" 0 "off" ;
VAL_ 345 M5_CellBalance17 1 "on" 0 "off" ;
VAL_ 345 M5_CellBalance16 1 "on" 0 "off" ;
VAL_ 345 M5_CellBalance15 1 "on" 0 "off" ;
VAL_ 345 M5_CellBalance14 1 "on" 0 "off" ;
VAL_ 345 M5_CellBalance13 1 "on" 0 "off" ;
VAL_ 345 M5_CellBalance11 1 "on" 0 "off" ;
VAL_ 345 M5_CellBalance10 1 "on" 0 "off" ;
VAL_ 345 M5_CellBalance9 1 "on" 0 "off" ;
VAL_ 345 M5_CellBalance8 1 "on" 0 "off" ;
VAL_ 345 M5_CellBalance7 1 "on" 0 "off" ;
VAL_ 345 M5_CellBalance6 1 "on" 0 "off" ;
VAL_ 345 M5_CellBalance5 1 "on" 0 "off" ;
VAL_ 345 M5_CellBalance4 1 "on" 0 "off" ;
VAL_ 345 M5_CellBalance3 1 "on" 0 "off" ;
VAL_ 345 M5_CellBalance2 1 "on" 0 "off" ;
VAL_ 345 M5_CellBalance12 1 "on" 0 "off" ;
VAL_ 345 M5_CellBalance1 1 "on" 0 "off" ;
VAL_ 329 Lecu_Version1 86 "V" ;
VAL_ 329 Lecu_Version0 76 "L" ;
VAL_ 329 M4_CellBalance24 1 "on" 0 "off" ;
VAL_ 329 M4_CellBalance23 1 "on" 0 "off" ;
VAL_ 329 M4_CellBalance22 1 "on" 0 "off" ;
VAL_ 329 M4_CellBalance21 1 "on" 0 "off" ;
VAL_ 329 M4_CellBalance20 1 "on" 0 "off" ;
VAL_ 329 M4_CellBalance19 1 "on" 0 "off" ;
VAL_ 329 M4_CellBalance18 1 "on" 0 "off" ;
VAL_ 329 M4_CellBalance17 1 "on" 0 "off" ;
VAL_ 329 M4_CellBalance16 1 "on" 0 "off" ;
VAL_ 329 M4_CellBalance15 1 "on" 0 "off" ;
VAL_ 329 M4_CellBalance14 1 "on" 0 "off" ;
VAL_ 329 M4_CellBalance13 1 "on" 0 "off" ;
VAL_ 329 M4_CellBalance9 1 "on" 0 "off" ;
VAL_ 329 M4_CellBalance8 1 "on" 0 "off" ;
VAL_ 329 M4_CellBalance7 1 "on" 0 "off" ;
VAL_ 329 M4_CellBalance6 1 "on" 0 "off" ;
VAL_ 329 M4_CellBalance5 1 "on" 0 "off" ;
VAL_ 329 M4_CellBalance4 1 "on" 0 "off" ;
VAL_ 329 M4_CellBalance3 1 "on" 0 "off" ;
VAL_ 329 M4_CellBalance2 1 "on" 0 "off" ;
VAL_ 329 M4_CellBalance12 1 "on" 0 "off" ;
VAL_ 329 M4_CellBalance11 1 "on" 0 "off" ;
VAL_ 329 M4_CellBalance10 1 "on" 0 "off" ;
VAL_ 329 M4_CellBalance1 1 "on" 0 "off" ;
VAL_ 313 Lecu_Version1 86 "V" ;
VAL_ 313 Lecu_Version0 76 "L" ;
VAL_ 313 M3_CellBalance24 1 "on" 0 "off" ;
VAL_ 313 M3_CellBalance23 1 "on" 0 "off" ;
VAL_ 313 M3_CellBalance22 1 "on" 0 "off" ;
VAL_ 313 M3_CellBalance21 1 "on" 0 "off" ;
VAL_ 313 M3_CellBalance20 1 "on" 0 "off" ;
VAL_ 313 M3_CellBalance19 1 "on" 0 "off" ;
VAL_ 313 M3_CellBalance18 1 "on" 0 "off" ;
VAL_ 313 M3_CellBalance17 1 "on" 0 "off" ;
VAL_ 313 M3_CellBalance16 1 "on" 0 "off" ;
VAL_ 313 M3_CellBalance15 1 "on" 0 "off" ;
VAL_ 313 M3_CellBalance14 1 "on" 0 "off" ;
VAL_ 313 M3_CellBalance13 1 "on" 0 "off" ;
VAL_ 313 M3_CellBalance9 1 "on" 0 "off" ;
VAL_ 313 M3_CellBalance8 1 "on" 0 "off" ;
VAL_ 313 M3_CellBalance7 1 "on" 0 "off" ;
VAL_ 313 M3_CellBalance6 1 "on" 0 "off" ;
VAL_ 313 M3_CellBalance5 1 "on" 0 "off" ;
VAL_ 313 M3_CellBalance4 1 "on" 0 "off" ;
VAL_ 313 M3_CellBalance3 1 "on" 0 "off" ;
VAL_ 313 M3_CellBalance2 1 "on" 0 "off" ;
VAL_ 313 M3_CellBalance12 1 "on" 0 "off" ;
VAL_ 313 M3_CellBalance11 1 "on" 0 "off" ;
VAL_ 313 M3_CellBalance10 1 "on" 0 "off" ;
VAL_ 313 M3_CellBalance1 1 "on" 0 "off" ;
VAL_ 297 Lecu_Version1 86 "V" ;
VAL_ 297 Lecu_Version0 76 "L" ;
VAL_ 297 M2_CellBalance24 1 "on" 0 "off" ;
VAL_ 297 M2_CellBalance23 1 "on" 0 "off" ;
VAL_ 297 M2_CellBalance22 1 "on" 0 "off" ;
VAL_ 297 M2_CellBalance21 1 "on" 0 "off" ;
VAL_ 297 M2_CellBalance20 1 "on" 0 "off" ;
VAL_ 297 M2_CellBalance19 1 "on" 0 "off" ;
VAL_ 297 M2_CellBalance18 1 "on" 0 "off" ;
VAL_ 297 M2_CellBalance17 1 "on" 0 "off" ;
VAL_ 297 M2_CellBalance16 1 "on" 0 "off" ;
VAL_ 297 M2_CellBalance15 1 "on" 0 "off" ;
VAL_ 297 M2_CellBalance14 1 "on" 0 "off" ;
VAL_ 297 M2_CellBalance13 1 "on" 0 "off" ;
VAL_ 297 M2_CellBalance9 1 "on" 0 "off" ;
VAL_ 297 M2_CellBalance8 1 "on" 0 "off" ;
VAL_ 297 M2_CellBalance7 1 "on" 0 "off" ;
VAL_ 297 M2_CellBalance6 1 "on" 0 "off" ;
VAL_ 297 M2_CellBalance5 1 "on" 0 "off" ;
VAL_ 297 M2_CellBalance4 1 "on" 0 "off" ;
VAL_ 297 M2_CellBalance3 1 "on" 0 "off" ;
VAL_ 297 M2_CellBalance2 1 "on" 0 "off" ;
VAL_ 297 M2_CellBalance12 1 "on" 0 "off" ;
VAL_ 297 M2_CellBalance11 1 "on" 0 "off" ;
VAL_ 297 M2_CellBalance10 1 "on" 0 "off" ;
VAL_ 297 M2_CellBalance1 1 "on" 0 "off" ;
VAL_ 281 Lecu_Version1 86 "V" ;
VAL_ 281 Lecu_Version0 76 "L" ;
VAL_ 281 M1_CellBalance24 1 "on" 0 "off" ;
VAL_ 281 M1_CellBalance23 1 "on" 0 "off" ;
VAL_ 281 M1_CellBalance22 1 "on" 0 "off" ;
VAL_ 281 M1_CellBalance21 1 "on" 0 "off" ;
VAL_ 281 M1_CellBalance20 1 "on" 0 "off" ;
VAL_ 281 M1_CellBalance19 1 "on" 0 "off" ;
VAL_ 281 M1_CellBalance18 1 "on" 0 "off" ;
VAL_ 281 M1_CellBalance17 1 "on" 0 "off" ;
VAL_ 281 M1_CellBalance16 1 "on" 0 "off" ;
VAL_ 281 M1_CellBalance15 1 "on" 0 "off" ;
VAL_ 281 M1_CellBalance14 1 "on" 0 "off" ;
VAL_ 281 M1_CellBalance13 1 "on" 0 "off" ;
VAL_ 281 M1_CellBalance9 1 "on" 0 "off" ;
VAL_ 281 M1_CellBalance8 1 "on" 0 "off" ;
VAL_ 281 M1_CellBalance7 1 "on" 0 "off" ;
VAL_ 281 M1_CellBalance6 1 "on" 0 "off" ;
VAL_ 281 M1_CellBalance5 1 "on" 0 "off" ;
VAL_ 281 M1_CellBalance4 1 "on" 0 "off" ;
VAL_ 281 M1_CellBalance3 1 "on" 0 "off" ;
VAL_ 281 M1_CellBalance2 1 "on" 0 "off" ;
VAL_ 281 M1_CellBalance12 1 "on" 0 "off" ;
VAL_ 281 M1_CellBalance11 1 "on" 0 "off" ;
VAL_ 281 M1_CellBalance10 1 "on" 0 "off" ;
VAL_ 281 M1_CellBalance1 1 "on" 0 "off" ;
